VERSION ""

NS_ :

BS_:

BU_: Sound_A Ladegeraet_PAG_PF Motor_EDC17_Pirol PSM_Ant_Derivate GW_Routing_Derivate GW_Applikation_Derivate BMS_Hybrid Getriebe_Derivate LEH_Hybrid Motor_MED17_Hybrid Sound_I Tool Airbag Waehlhebel

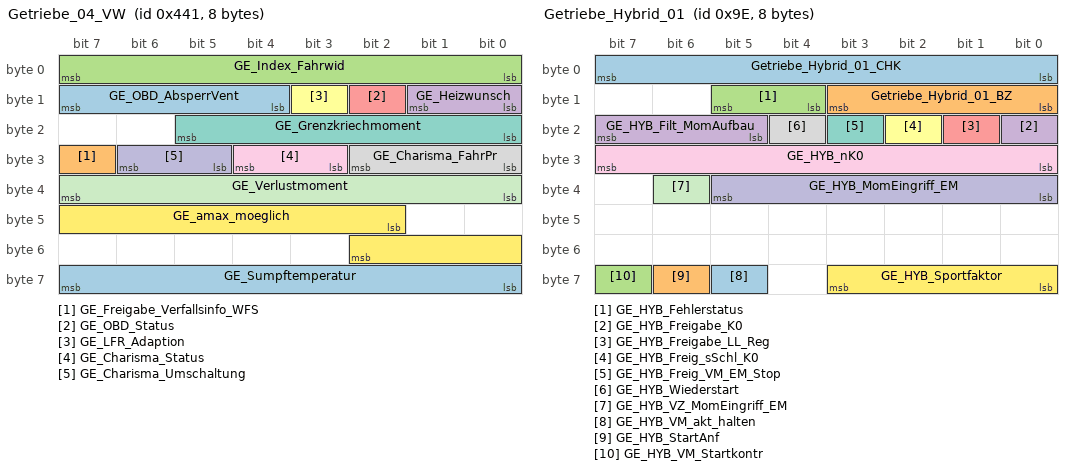
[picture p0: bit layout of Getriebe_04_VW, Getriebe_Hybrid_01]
BO_ 1089 Getriebe_04_VW: 8 Getriebe_Derivate
 SG_ GE_OBD_AbsperrVent : 12|4@1+ (1,0) [0|15] ""  GW_Routing_Derivate,Motor_EDC17_Pirol,Motor_MED17_Hybrid
 SG_ GE_Freigabe_Verfallsinfo_WFS : 31|1@1+ (1,0) [0|1] ""  GW_Routing_Derivate
 SG_ GE_Index_Fahrwid : 0|8@1+ (0.249,-31.623) [-31.623|31.623] ""  GW_Routing_Derivate,Motor_EDC17_Pirol,PSM_Ant_Derivate,Motor_MED17_Hybrid
 SG_ GE_Heizwunsch : 8|2@1+ (1,0) [0|3] ""  GW_Routing_Derivate,PSM_Ant_Derivate,Motor_MED17_Hybrid,Motor_EDC17_Pirol
 SG_ GE_OBD_Status : 10|1@1+ (1,0) [0|1] ""  GW_Routing_Derivate,Motor_EDC17_Pirol,PSM_Ant_Derivate,Motor_MED17_Hybrid
 SG_ GE_LFR_Adaption : 11|1@1+ (1,0) [0|1] ""  GW_Routing_Derivate,Motor_EDC17_Pirol,PSM_Ant_Derivate,Motor_MED17_Hybrid
 SG_ GE_Grenzkriechmoment : 16|6@1+ (2,0) [0|122] ""  GW_Routing_Derivate,PSM_Ant_Derivate
 SG_ GE_Charisma_FahrPr : 24|3@1+ (1,0) [0|7] ""  GW_Routing_Derivate
 SG_ GE_Charisma_Status : 27|2@1+ (1,0) [0|3] ""  GW_Routing_Derivate,PSM_Ant_Derivate
 SG_ GE_Charisma_Umschaltung : 29|2@1+ (1,0) [0|3] ""  GW_Routing_Derivate
 SG_ GE_Verlustmoment : 32|8@1+ (1,0) [0|254] ""  GW_Routing_Derivate,Motor_EDC17_Pirol,PSM_Ant_Derivate,Motor_MED17_Hybrid
 SG_ GE_amax_moeglich : 42|9@1+ (0.024,-2.016) [-2.016|10.224] "Unit_MeterPerSeconSquar"  GW_Routing_Derivate,Motor_EDC17_Pirol,PSM_Ant_Derivate,Motor_MED17_Hybrid
 SG_ GE_Sumpftemperatur : 56|8@1+ (1,-58) [-58|196] "Unit_DegreCelsi"  GW_Routing_Derivate,BMS_Hybrid,Motor_EDC17_Pirol,PSM_Ant_Derivate,Motor_MED17_Hybrid

BO_ 158 Getriebe_Hybrid_01: 8 Getriebe_Derivate
 SG_ Getriebe_Hybrid_01_CHK : 0|8@1+ (1,0) [0|255] "" Vector__XXX
 SG_ Getriebe_Hybrid_01_BZ : 8|4@1+ (1,0) [0|15] ""  Motor_MED17_Hybrid
 SG_ GE_HYB_Fehlerstatus : 12|2@1+ (1,0) [0|3] ""  Motor_MED17_Hybrid
 SG_ GE_HYB_Freigabe_K0 : 16|1@1+ (1,0) [0|1] ""  Motor_MED17_Hybrid
 SG_ GE_HYB_Freigabe_LL_Reg : 17|1@1+ (1,0) [0|1] ""  Motor_MED17_Hybrid
 SG_ GE_HYB_Freig_sSchl_K0 : 18|1@1+ (1,0) [0|1] ""  Motor_MED17_Hybrid
 SG_ GE_HYB_Freig_VM_EM_Stop : 19|1@1+ (1,0) [0|1] ""  Motor_MED17_Hybrid
 SG_ GE_HYB_Wiederstart : 20|1@1+ (1,0) [0|1] ""  Motor_MED17_Hybrid
 SG_ GE_HYB_nK0 : 24|8@1+ (25,0) [0|6350] "Unit_MinutInver" Vector__XXX
 SG_ GE_HYB_MomEingriff_EM : 32|6@1+ (0.5,0) [0|31.5] "Unit_NewtoMeter" Vector__XXX
 SG_ GE_HYB_VZ_MomEingriff_EM : 38|1@1+ (1,0) [0|1] "" Vector__XXX
 SG_ GE_HYB_Sportfaktor : 56|4@1+ (1,0) [0|15] ""  Motor_MED17_Hybrid
 SG_ GE_HYB_VM_akt_halten : 61|1@1+ (1,0) [0|1] ""  Motor_MED17_Hybrid
 SG_ GE_HYB_StartAnf : 62|1@1+ (1,0) [0|1] ""  Motor_MED17_Hybrid
 SG_ GE_HYB_VM_Startkontr : 63|1@1+ (1,0) [0|1] ""  Motor_MED17_Hybrid
 SG_ GE_HYB_Filt_MomAufbau : 21|3@1+ (1,0) [0|7] "" Vector__XXX

BO_ 2022 ISO_EMotor_01_Req: 8 GW_Routing_Derivate
 SG_ ISO_EMotor_01_Req_Data : 0|64@1+ (1,0) [0|1] ""  LEH_Hybrid

BO_ 2030 ISO_EMotor_01_Resp: 8 LEH_Hybrid
 SG_ ISO_EMotor_01_Resp_Data : 0|64@1+ (1,0) [0|1] ""  GW_Routing_Derivate

BO_ 2021 ISO_Hybrid_01_Req: 8 GW_Routing_Derivate
 SG_ ISO_Hybrid_01_Req_Data : 0|64@1+ (1,0) [0|1] ""  BMS_Hybrid

BO_ 2029 ISO_Hybrid_01_Resp: 8 BMS_Hybrid
 SG_ ISO_Hybrid_01_Resp_Data : 0|64@1+ (1,0) [0|1] ""  GW_Routing_Derivate

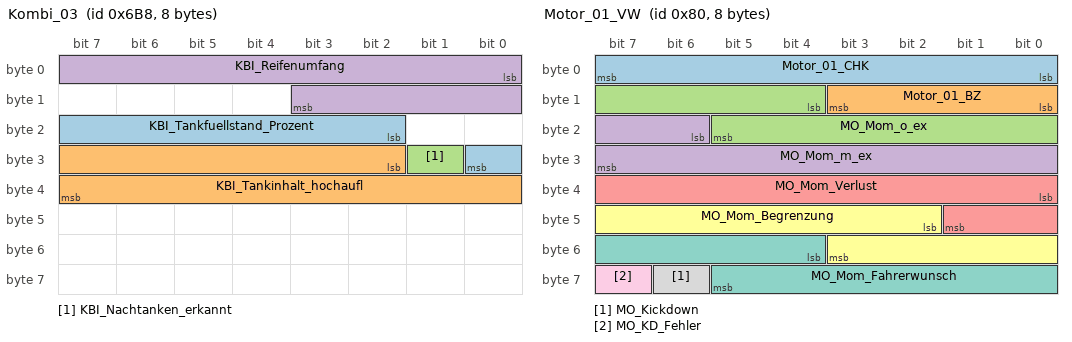
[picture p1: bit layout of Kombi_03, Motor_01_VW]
BO_ 1720 Kombi_03: 8 GW_Routing_Derivate
 SG_ KBI_Tankfuellstand_Prozent : 18|7@1+ (1,0) [0|100] "Unit_PerCent" Vector__XXX
 SG_ KBI_Tankinhalt_hochaufl : 26|14@1+ (0.01,0) [0|163.81] "Unit_Liter"  BMS_Hybrid
 SG_ KBI_Nachtanken_erkannt : 25|1@1+ (1,0) [0|1] ""  BMS_Hybrid
 SG_ KBI_Reifenumfang : 0|12@1+ (1,0) [0|4095] "Unit_MilliMeter"  Motor_MED17_Hybrid,PSM_Ant_Derivate

BO_ 128 Motor_01_VW: 8 Motor_MED17_Hybrid
 SG_ Motor_01_CHK : 0|8@1+ (1,0) [0|255] ""  PSM_Ant_Derivate,GW_Routing_Derivate,Getriebe_Derivate
 SG_ Motor_01_BZ : 8|4@1+ (1,0) [0|15] ""  PSM_Ant_Derivate,GW_Routing_Derivate,Getriebe_Derivate
 SG_ MO_Mom_o_ex : 12|10@1+ (1,0) [0|1021] ""  Sound_A,Sound_I,PSM_Ant_Derivate,GW_Routing_Derivate,Getriebe_Derivate
 SG_ MO_Mom_m_ex : 22|10@1+ (1,0) [0|1021] ""  PSM_Ant_Derivate,GW_Routing_Derivate,Getriebe_Derivate
 SG_ MO_Mom_Verlust : 32|10@1+ (1,0) [0|1021] ""  Sound_A,Sound_I,PSM_Ant_Derivate,GW_Routing_Derivate,Getriebe_Derivate
 SG_ MO_Mom_Begrenzung : 42|10@1+ (1,0) [0|1021] ""  PSM_Ant_Derivate,GW_Routing_Derivate,Getriebe_Derivate
 SG_ MO_Mom_Fahrerwunsch : 52|10@1+ (1,0) [0|1021] ""  PSM_Ant_Derivate,GW_Routing_Derivate,Getriebe_Derivate
 SG_ MO_Kickdown : 62|1@1+ (1,0) [0|1] ""  PSM_Ant_Derivate,GW_Routing_Derivate,Getriebe_Derivate
 SG_ MO_KD_Fehler : 63|1@1+ (1,0) [0|1] ""  PSM_Ant_Derivate,GW_Applikation_Derivate,GW_Routing_Derivate

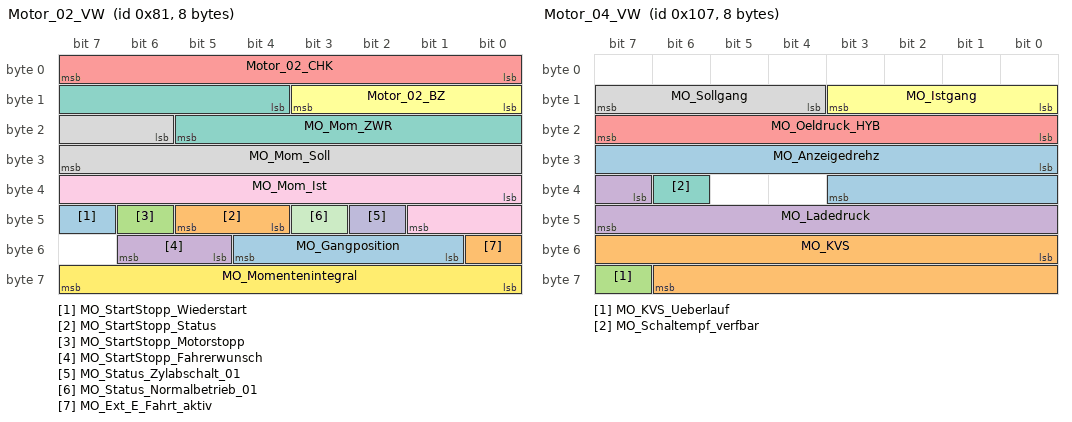
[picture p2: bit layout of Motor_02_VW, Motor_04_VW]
BO_ 129 Motor_02_VW: 8 Motor_MED17_Hybrid
 SG_ MO_StartStopp_Wiederstart : 47|1@1+ (1,0) [0|1] ""  GW_Routing_Derivate,PSM_Ant_Derivate,GW_Applikation_Derivate,Getriebe_Derivate
 SG_ MO_StartStopp_Status : 44|2@1+ (1,0) [0|3] ""  GW_Routing_Derivate,PSM_Ant_Derivate,GW_Applikation_Derivate
 SG_ MO_StartStopp_Motorstopp : 46|1@1+ (1,0) [0|1] ""  GW_Routing_Derivate,LEH_Hybrid,PSM_Ant_Derivate,GW_Applikation_Derivate,Getriebe_Derivate
 SG_ MO_StartStopp_Fahrerwunsch : 53|2@1+ (1,0) [0|3] ""  GW_Routing_Derivate
 SG_ Motor_02_CHK : 0|8@1+ (1,0) [0|255] ""  PSM_Ant_Derivate,GW_Routing_Derivate,Getriebe_Derivate
 SG_ Motor_02_BZ : 8|4@1+ (1,0) [0|15] ""  PSM_Ant_Derivate,GW_Routing_Derivate,Getriebe_Derivate
 SG_ MO_Mom_ZWR : 12|10@1+ (1,0) [0|1021] ""  PSM_Ant_Derivate,Getriebe_Derivate
 SG_ MO_Mom_Soll : 22|10@1+ (1,0) [0|1021] ""  PSM_Ant_Derivate
 SG_ MO_Mom_Ist : 32|10@1+ (1,0) [0|1021] ""  PSM_Ant_Derivate,Getriebe_Derivate
 SG_ MO_Status_Zylabschalt_01 : 42|1@1+ (1,0) [0|1] ""  PSM_Ant_Derivate
 SG_ MO_Status_Normalbetrieb_01 : 43|1@1+ (1,0) [0|1] ""  PSM_Ant_Derivate,Getriebe_Derivate
 SG_ MO_Momentenintegral : 56|8@1+ (0.3921,0) [0|99.9855] ""  PSM_Ant_Derivate,Getriebe_Derivate
 SG_ MO_Gangposition : 49|4@1+ (1,0) [0|15] "" Vector__XXX
 SG_ MO_Ext_E_Fahrt_aktiv : 48|1@1+ (1,0) [0|1] ""  Getriebe_Derivate,GW_Routing_Derivate

BO_ 261 Motor_03_VW: 8 Motor_MED17_Hybrid
 SG_ MO_QBit_Motormomente : 13|1@1+ (1,0) [0|1] ""  Getriebe_Derivate,GW_Routing_Derivate,PSM_Ant_Derivate
 SG_ Motor_03_CHK : 0|8@1+ (1,0) [0|255] ""  BMS_Hybrid,PSM_Ant_Derivate,LEH_Hybrid,GW_Routing_Derivate,Getriebe_Derivate
 SG_ Motor_03_BZ : 8|4@1+ (1,0) [0|15] ""  BMS_Hybrid,PSM_Ant_Derivate,LEH_Hybrid,GW_Routing_Derivate,Getriebe_Derivate
 SG_ MO_QBit_Fahrpedalwerte_01 : 12|1@1+ (1,0) [0|1] ""  BMS_Hybrid,PSM_Ant_Derivate,GW_Routing_Derivate,Getriebe_Derivate
 SG_ MO_QBit_Fahrer_bremst : 14|1@1+ (1,0) [0|1] ""  PSM_Ant_Derivate,GW_Routing_Derivate,Getriebe_Derivate
 SG_ MO_QBit_Drehzahl_01 : 15|1@1+ (1,0) [0|1] ""  PSM_Ant_Derivate,BMS_Hybrid,GW_Routing_Derivate,Getriebe_Derivate,LEH_Hybrid
 SG_ MO_Drehzahl_01 : 16|16@1+ (0.25,0) [0|16383] "Unit_MinutInver"  Sound_A,Sound_I,PSM_Ant_Derivate,BMS_Hybrid,GW_Applikation_Derivate,GW_Routing_Derivate,Getriebe_Derivate,LEH_Hybrid
 SG_ MO_Moment_im_Leerlauf : 32|1@1+ (1,0) [0|1] ""  PSM_Ant_Derivate,GW_Routing_Derivate,Getriebe_Derivate
 SG_ MO_Interlock : 33|1@1+ (1,0) [0|1] ""  PSM_Ant_Derivate,GW_Routing_Derivate
 SG_ MO_BLS : 34|1@1+ (1,0) [0|1] ""  PSM_Ant_Derivate,GW_Routing_Derivate,Getriebe_Derivate
 SG_ MO_Fahrer_bremst : 35|1@1+ (1,0) [0|1] ""  PSM_Ant_Derivate,GW_Routing_Derivate,Getriebe_Derivate
 SG_ MO_Konsistenz_Bremsped : 36|1@1+ (1,0) [0|1] ""  PSM_Ant_Derivate,GW_Routing_Derivate
 SG_ MO_Kuppl_schalter : 37|1@1+ (1,0) [0|1] ""  PSM_Ant_Derivate,GW_Routing_Derivate
 SG_ MO_Timeout_ESP : 38|1@1+ (1,0) [0|1] ""  PSM_Ant_Derivate,GW_Routing_Derivate
 SG_ MO_Motor_laeuft : 39|1@1+ (1,0) [0|1] ""  PSM_Ant_Derivate,GW_Applikation_Derivate,GW_Routing_Derivate,Getriebe_Derivate
 SG_ MO_Solldrehz_Leerlauf : 40|8@1+ (10,0) [0|2540] "Unit_MinutInver"  PSM_Ant_Derivate,GW_Routing_Derivate,Getriebe_Derivate,GW_Applikation_Derivate
 SG_ MO_Fahrpedalrohwert_01 : 48|8@1+ (0.4,0) [0|101.6] "Unit_PerCent"  Sound_A,Sound_I,BMS_Hybrid,PSM_Ant_Derivate,GW_Routing_Derivate,Getriebe_Derivate
 SG_ MO_erste_Ungenauschwelle : 56|1@1+ (1,0) [0|1] ""  PSM_Ant_Derivate,GW_Routing_Derivate,Getriebe_Derivate
 SG_ MO_QBit_Stressfaktor : 57|1@1+ (1,0) [0|1] ""  PSM_Ant_Derivate,GW_Routing_Derivate
 SG_ MO_Stressfaktor : 58|6@1+ (1.6,0) [0|100.8] "Unit_PerCent"  PSM_Ant_Derivate,GW_Routing_Derivate

BO_ 263 Motor_04_VW: 8 Motor_MED17_Hybrid
 SG_ MO_Anzeigedrehz : 24|12@1+ (3,0) [0|12282] "U/min"  PSM_Ant_Derivate,GW_Routing_Derivate
 SG_ MO_KVS : 48|15@1+ (1,0) [0|32767] "Unit_MicroLiter"  BMS_Hybrid,PSM_Ant_Derivate,GW_Routing_Derivate
 SG_ MO_KVS_Ueberlauf : 63|1@1+ (1,0) [0|1] ""  BMS_Hybrid,PSM_Ant_Derivate,GW_Routing_Derivate
 SG_ MO_Ladedruck : 39|9@1+ (0.01,0) [0|5.1] "Unit_Bar"  GW_Routing_Derivate,PSM_Ant_Derivate
 SG_ MO_Oeldruck_HYB : 16|8@1+ (0.04,0) [0|10] "Uni_Bar"  GW_Routing_Derivate
 SG_ MO_Istgang : 8|4@1+ (1,0) [0|15] "" Vector__XXX
 SG_ MO_Schaltempf_verfbar : 38|1@1+ (1,0) [0|1] "" Vector__XXX
 SG_ MO_Sollgang : 12|4@1+ (1,0) [0|15] "" Vector__XXX

BO_ 782 Motor_05_VW: 8 Motor_MED17_Hybrid
 SG_ MO_Handshake_STH : 47|1@1+ (1,0) [0|1] ""  GW_Routing_Derivate
 SG_ Motor_05_CHK : 0|8@1+ (1,0) [0|255] ""  GW_Routing_Derivate,Getriebe_Derivate
 SG_ Motor_05_BZ : 8|4@1+ (1,0) [0|15] ""  GW_Routing_Derivate,Getriebe_Derivate
 SG_ MO_EKlKomLeiRed : 12|2@1+ (1,0) [0|3] ""  GW_Routing_Derivate
 SG_ MO_Freig_Reku : 14|2@1+ (1,0) [0|3] ""  BMS_Hybrid,GW_Routing_Derivate,GW_Applikation_Derivate
 SG_ MO_Klima_Eingr : 16|2@1+ (1,0) [0|3] ""  GW_Routing_Derivate
 SG_ MO_Status_Normalbetrieb_02 : 18|1@1+ (1,0) [0|1] ""  GW_Routing_Derivate
 SG_ MO_Schaltbeeinfl_Leistungsbegr : 19|1@1+ (1,0) [0|1] ""  GW_Routing_Derivate
 SG_ MO_Schaltbeeinfl_Partikelfilter : 20|1@1+ (1,0) [0|1] ""  GW_Routing_Derivate,Getriebe_Derivate
 SG_ MO_Prio_MIN_Wunschdrehzahl : 21|1@1+ (1,0) [0|1] ""  GW_Routing_Derivate,Getriebe_Derivate
 SG_ MO_Freig_Anlass : 22|1@1+ (1,0) [0|1] ""  GW_Routing_Derivate
 SG_ MO_Aussp_Anlass : 23|1@1+ (1,0) [0|1] ""  GW_Routing_Derivate
 SG_ MO_MAX_Wunschdrehzahl : 24|9@1+ (25,0) [0|12750] "Unit_MinutInver"  GW_Routing_Derivate,Getriebe_Derivate
 SG_ MO_Prio_MAX_Wunschdrehzahl : 33|1@1+ (1,0) [0|1] ""  GW_Routing_Derivate,Getriebe_Derivate
 SG_ MO_Luftpfad_aktiv : 34|1@1+ (1,0) [0|1] ""  GW_Routing_Derivate
 SG_ MO_v_Begrenz_Aktiv : 35|1@1+ (1,0) [0|1] ""  GW_Routing_Derivate
 SG_ MO_v_Begrenz_Aktivierbar : 36|1@1+ (1,0) [0|1] ""  GW_Routing_Derivate
 SG_ MO_Verbot_EKP : 37|1@1+ (1,0) [0|1] ""  GW_Routing_Derivate
 SG_ MO_Anf_Pruefimpuls : 38|1@1+ (1,0) [0|1] ""  GW_Routing_Derivate
 SG_ MO_Anf_KL75 : 39|1@1+ (1,0) [0|1] ""  GW_Routing_Derivate
 SG_ MO_Charisma_FahrPr : 40|3@1+ (1,0) [0|7] ""  GW_Routing_Derivate
 SG_ MO_Charisma_Status : 43|2@1+ (1,0) [0|3] ""  PSM_Ant_Derivate,GW_Routing_Derivate
 SG_ MO_Charisma_Umschaltung : 45|2@1+ (1,0) [0|3] ""  GW_Routing_Derivate
 SG_ MO_MIN_Wunschdrehzahl : 48|8@1+ (25,0) [0|6350] "Unit_MinutInver"  GW_Routing_Derivate,Getriebe_Derivate
 SG_ MO_Drehzahlbeeinflussung : 56|8@1+ (0.39,0) [0|99.45] "Unit_PerCent"  GW_Routing_Derivate

BO_ 1088 Motor_06_VW: 8 Motor_MED17_Hybrid
 SG_ MO_Kat_Warnung : 22|1@1+ (1,0) [0|1] ""  GW_Routing_Derivate
 SG_ MO_ITM_Warnung_Pumpe : 11|1@1+ (1,0) [0|1] ""  GW_Routing_Derivate
 SG_ MO_HYB_Text_4 : 31|1@1+ (1,0) [0|1] ""  GW_Routing_Derivate
 SG_ MO_HYB_Status_HV_Ladung : 8|3@1+ (1,0) [0|7] ""  GW_Routing_Derivate
 SG_ MO_Zustand_HWP : 20|2@1+ (1,0) [0|3] ""  GW_Routing_Derivate
 SG_ MO_Kuehlerluefter_MUX M : 0|1@1+ (1,0) [0|1] ""  GW_Routing_Derivate
 SG_ MO_Kuehlerluefter_1 m0 : 1|7@1+ (1,0) [0|100] "Unit_PerCent"  GW_Routing_Derivate
 SG_ MO_Kuehlerluefter_2 m1 : 1|7@1+ (1,0) [0|100] "Unit_PerCent"  GW_Routing_Derivate
 SG_ WIV_Anzeige_aktiv : 12|1@1+ (1,0) [0|1] ""  GW_Routing_Derivate
 SG_ WIV_Oelmin_Warn : 13|1@1+ (1,0) [0|1] ""  GW_Routing_Derivate
 SG_ WIV_Sensorfehler : 14|1@1+ (1,0) [0|1] ""  GW_Routing_Derivate
 SG_ WIV_Schieflage : 15|1@1+ (1,0) [0|1] ""  GW_Routing_Derivate
 SG_ WIV_Oelstand : 16|4@1+ (12.5,0) [0|100] "Unit_PerCent"  GW_Routing_Derivate
 SG_ WIV_Oelsystem_aktiv : 24|1@1+ (1,0) [0|1] ""  GW_Routing_Derivate
 SG_ WIV_nicht_betriebswarm : 25|1@1+ (1,0) [0|1] ""  GW_Routing_Derivate
 SG_ WIV_Ueberfuell_Warn : 26|1@1+ (1,0) [0|1] ""  GW_Routing_Derivate
 SG_ WIV_laufender_Motor : 27|1@1+ (1,0) [0|1] ""  GW_Routing_Derivate
 SG_ MO_Text_Motorstart : 32|4@1+ (1,0) [0|15] ""  GW_Routing_Derivate
 SG_ MO_Text_MSG_Werkstatt : 40|1@1+ (1,0) [0|1] ""  GW_Routing_Derivate
 SG_ MO_Text_Partikelfil_Reg : 41|1@1+ (1,0) [0|1] ""  GW_Routing_Derivate
 SG_ MO_Text_Fehler_Kraftstoffsys : 42|1@1+ (1,0) [0|1] ""  GW_Routing_Derivate
 SG_ WIV_Oelmenge : 43|5@1+ (125,0) [0|3875] "Unit_MilliLiter"  GW_Routing_Derivate
 SG_ MO_Systemlampe : 48|1@1+ (1,0) [0|1] ""  GW_Routing_Derivate
 SG_ MO_OBD2_Lampe : 49|1@1+ (1,0) [0|1] ""  GW_Routing_Derivate
 SG_ MO_Heissleuchte : 50|1@1+ (1,0) [0|1] ""  GW_Routing_Derivate
 SG_ MO_Partikel_Lampe : 51|1@1+ (1,0) [0|1] ""  GW_Routing_Derivate
 SG_ MO_Winterfahrprog : 52|1@1+ (1,0) [0|1] ""  GW_Routing_Derivate
 SG_ WIV_Oelstand_nicht_vorhanden : 53|1@1+ (1,0) [0|1] ""  GW_Routing_Derivate
 SG_ WIV_nachfuellanzeige_ein : 54|1@1+ (1,0) [0|1] ""  GW_Routing_Derivate
 SG_ WIV_Ueberfuell_deaktiv : 55|1@1+ (1,0) [0|1] ""  GW_Routing_Derivate
 SG_ WIV_Unterfuell_Warn : 56|1@1+ (1,0) [0|1] ""  GW_Routing_Derivate
 SG_ MO_Tankdeckel_Lampe : 57|1@1+ (1,0) [0|1] ""  GW_Routing_Derivate
 SG_ MO_Text_Tankdeckelwarn : 58|1@1+ (1,0) [0|1] ""  GW_Routing_Derivate
 SG_ WIV_Enable_Oeldr_Motor : 59|1@1+ (1,0) [0|1] ""  GW_Routing_Derivate
 SG_ WIV_Oeldr_Warn_Motor : 60|1@1+ (1,0) [0|1] ""  GW_Routing_Derivate
 SG_ MO_Avus_Motorschutz : 61|2@1+ (1,0) [0|3] ""  GW_Routing_Derivate
 SG_ MO_HYB_Fahrbereitschaft : 63|1@1+ (1,0) [0|1] ""  Sound_A,Sound_I,BMS_Hybrid,GW_Applikation_Derivate,GW_Routing_Derivate
 SG_ WIV_Oeldyn_avl : 39|1@1+ (1,0) [0|1] ""  GW_Routing_Derivate
 SG_ MO_HYB_Text_7 : 38|1@1+ (1,0) [0|1] ""  GW_Routing_Derivate
 SG_ MO_HYB_Text_6 : 37|1@1+ (1,0) [0|1] ""  GW_Routing_Derivate
 SG_ MO_HYB_Text_5 : 36|1@1+ (1,0) [0|1] ""  GW_Routing_Derivate
 SG_ MO_HYB_Text_3 : 30|1@1+ (1,0) [0|1] ""  GW_Routing_Derivate
 SG_ MO_HYB_Text_2 : 29|1@1+ (1,0) [0|1] ""  GW_Routing_Derivate
 SG_ MO_HYB_Text_1 : 28|1@1+ (1,0) [0|1] ""  GW_Routing_Derivate

BO_ 1600 Motor_07_VW: 8 Motor_MED17_Hybrid
 SG_ MO_Nachlaufzeit_Heizungspumpe : 58|6@1+ (15,0) [0|945] "Unit_Secon"  GW_Routing_Derivate
 SG_ MO_Kennfeldk : 40|1@1+ (1,0) [0|1] ""  GW_Routing_Derivate
 SG_ MO_QBit_Ansaugluft_Temp : 0|1@1+ (1,0) [0|1] ""  GW_Routing_Derivate
 SG_ MO_QBit_Oel_Temp : 1|1@1+ (1,0) [0|1] ""  GW_Routing_Derivate
 SG_ MO_QBit_Kuehlmittel_Temp : 2|1@1+ (1,0) [0|1] ""  GW_Routing_Derivate,Getriebe_Derivate,LEH_Hybrid
 SG_ MO_Stellgliedtest_Soundaktuator : 3|1@1+ (1,0) [0|1] ""  GW_Routing_Derivate
 SG_ MO_HYB_Fehler_HV_Netz : 4|1@1+ (1,0) [0|1] ""  GW_Applikation_Derivate,GW_Routing_Derivate
 SG_ MO_Absperrventil_oeffnen : 6|2@1+ (1,0) [0|3] ""  GW_Routing_Derivate
 SG_ MO_Ansaugluft_Temp : 8|8@1+ (0.75,-48) [-48|141.75] "Unit_DegreCelsi"  GW_Routing_Derivate,Getriebe_Derivate
 SG_ MO_Oel_Temp : 16|8@1+ (1,-60) [-60|193] "Unit_DegreCelsi"  GW_Routing_Derivate
 SG_ MO_Kuehlmittel_Temp : 24|8@1+ (0.75,-48) [-48|141.75] "Unit_DegreCelsi"  BMS_Hybrid,GW_Applikation_Derivate,GW_Routing_Derivate,Getriebe_Derivate,LEH_Hybrid
 SG_ MO_Hoeheninfo : 32|8@1+ (0.00781,0) [0|1.98374] ""  GW_Routing_Derivate,Getriebe_Derivate
 SG_ MO_Versionsinfo : 41|6@1+ (1,0) [0|63] ""  Getriebe_Derivate,GW_Routing_Derivate
 SG_ MO_Getriebe_kuehlen : 47|1@1+ (1,0) [0|1] ""  Getriebe_Derivate,GW_Routing_Derivate
 SG_ MO_Mom_Traegheit_02 : 48|5@1+ (0.01,0) [0|0.31] "Unit_KiloGramMeterSquar"  GW_Routing_Derivate
 SG_ MO_Heizungspumpenansteuerung : 53|4@1+ (10,0) [0|100] "Unit_PerCent"  GW_Routing_Derivate
 SG_ MO_SpannungsAnf : 57|1@1+ (1,0) [0|1] ""  GW_Applikation_Derivate,GW_Routing_Derivate
 SG_ MO_aktives_Getriebeheizen : 5|1@1+ (1,0) [0|1] ""  Getriebe_Derivate,GW_Routing_Derivate

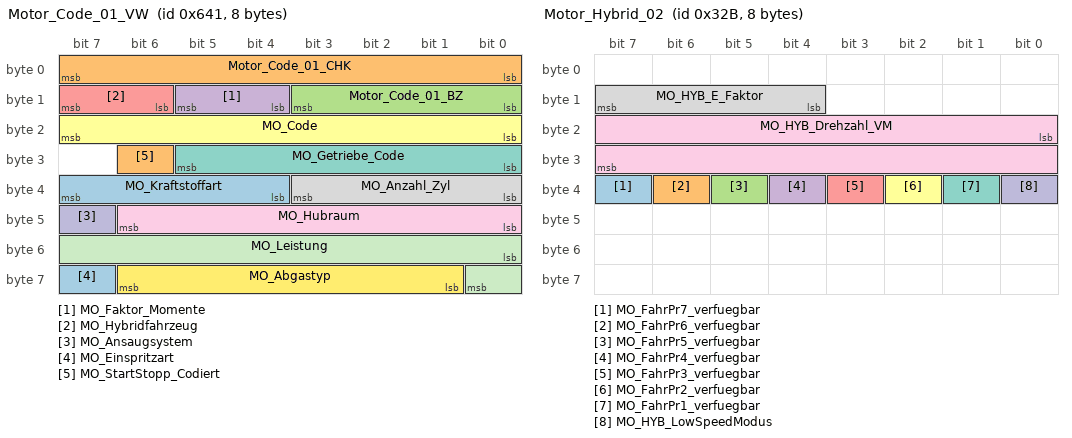
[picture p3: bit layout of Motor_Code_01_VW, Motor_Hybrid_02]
BO_ 1601 Motor_Code_01_VW: 8 Motor_MED17_Hybrid
 SG_ MO_Kraftstoffart : 36|4@1+ (1,0) [0|15] ""  PSM_Ant_Derivate,GW_Routing_Derivate,Getriebe_Derivate
 SG_ Motor_Code_01_CHK : 0|8@1+ (1,0) [0|255] ""  PSM_Ant_Derivate,LEH_Hybrid,GW_Routing_Derivate,Getriebe_Derivate
 SG_ Motor_Code_01_BZ : 8|4@1+ (1,0) [0|15] ""  PSM_Ant_Derivate,LEH_Hybrid,GW_Routing_Derivate,Getriebe_Derivate
 SG_ MO_Faktor_Momente : 12|2@1+ (1,0) [0|3] ""  PSM_Ant_Derivate,GW_Routing_Derivate,Getriebe_Derivate
 SG_ MO_Hybridfahrzeug : 14|2@1+ (1,0) [0|3] ""  PSM_Ant_Derivate,GW_Routing_Derivate
 SG_ MO_Code : 16|8@1+ (1,0) [0|255] ""  PSM_Ant_Derivate,GW_Routing_Derivate,Getriebe_Derivate
 SG_ MO_Getriebe_Code : 24|6@1+ (1,0) [0|63] ""  PSM_Ant_Derivate,GW_Routing_Derivate,Getriebe_Derivate
 SG_ MO_Anzahl_Zyl : 32|4@1+ (1,0) [0|15] ""  GW_Routing_Derivate
 SG_ MO_Hubraum : 40|7@1+ (0.1,0) [0|12.7] "Unit_Liter"  GW_Routing_Derivate
 SG_ MO_Ansaugsystem : 47|1@1+ (1,0) [0|1] ""  GW_Routing_Derivate
 SG_ MO_Leistung : 48|9@1+ (1,0) [0|511] "Unit_KiloWatt"  GW_Routing_Derivate,Getriebe_Derivate
 SG_ MO_Abgastyp : 57|6@1+ (1,0) [0|63] ""  LEH_Hybrid,BMS_Hybrid,GW_Routing_Derivate,Getriebe_Derivate
 SG_ MO_Einspritzart : 63|1@1+ (1,0) [0|1] ""  GW_Routing_Derivate
 SG_ MO_StartStopp_Codiert : 30|1@1+ (1,0) [0|1] ""  GW_Routing_Derivate,Getriebe_Derivate

BO_ 157 Motor_Hybrid_01: 8 Motor_MED17_Hybrid
 SG_ MO_HYB_EMode_Info : 14|2@1+ (1,0) [0|3] ""  Getriebe_Derivate
 SG_ Motor_Hybrid_01_CHK : 0|8@1+ (1,0) [0|255] ""  Getriebe_Derivate
 SG_ Motor_Hybrid_01_BZ : 8|4@1+ (1,0) [0|15] ""  BMS_Hybrid,Getriebe_Derivate
 SG_ MO_HYB_IstStatusK0 : 12|2@1+ (1,0) [0|3] ""  Getriebe_Derivate
 SG_ MO_HYB_max_ind_VM_Mom : 16|10@1+ (1,0) [0|1021] "Unit_NewtoMeter"  Getriebe_Derivate
 SG_ MO_HYB_Zielzustand : 26|3@1+ (1,0) [0|7] ""  BMS_Hybrid,Getriebe_Derivate
 SG_ MO_HYB_Startmodus : 29|3@1+ (1,0) [0|7] ""  Getriebe_Derivate
 SG_ MO_HYB_Startmodus_PQ3x : 32|1@1+ (1,0) [0|1] "" Vector__XXX
 SG_ MO_HYB_Stoppmodus : 33|1@1+ (1,0) [0|1] "" Vector__XXX
 SG_ MO_HYB_VM_Mom_oE : 40|10@1+ (1,-100) [-100|922] "Unit_NewtoMeter"  Getriebe_Derivate
 SG_ MO_HYB_VM_aktiv : 50|1@1+ (1,0) [0|1] ""  BMS_Hybrid,Getriebe_Derivate,GW_Routing_Derivate
 SG_ MO_HYB_Schaltverhinderung : 51|1@1+ (1,0) [0|1] ""  Getriebe_Derivate
 SG_ MO_HYB_Selektor_Momverlauf_EM M : 53|3@1+ (1,0) [0|7] ""  Getriebe_Derivate
 SG_ MO_HYB_Momverlauf_Rek m1 : 56|8@1+ (2,0) [0|510] "Unit_NewtoMeter"  Getriebe_Derivate
 SG_ MO_HYB_KnickDZ_Rek m2 : 56|8@1+ (12.5,0) [0|3150] "Unit_MinutInver"  Getriebe_Derivate
 SG_ MO_HYB_Momverlauf_EM m3 : 56|8@1+ (2,0) [0|510] "Unit_NewtoMeter"  Getriebe_Derivate
 SG_ MO_HYB_KnickDZ_EM m4 : 56|8@1+ (12.5,0) [0|3150] "Unit_MinutInver"  Getriebe_Derivate

BO_ 811 Motor_Hybrid_02: 8 Motor_MED17_Hybrid
 SG_ MO_FahrPr7_verfuegbar : 39|1@1+ (1,0) [0|1] ""  GW_Routing_Derivate
 SG_ MO_FahrPr6_verfuegbar : 38|1@1+ (1,0) [0|1] ""  GW_Routing_Derivate
 SG_ MO_FahrPr5_verfuegbar : 37|1@1+ (1,0) [0|1] ""  GW_Routing_Derivate
 SG_ MO_FahrPr4_verfuegbar : 36|1@1+ (1,0) [0|1] ""  GW_Routing_Derivate
 SG_ MO_FahrPr3_verfuegbar : 35|1@1+ (1,0) [0|1] ""  GW_Routing_Derivate
 SG_ MO_FahrPr2_verfuegbar : 34|1@1+ (1,0) [0|1] ""  GW_Routing_Derivate
 SG_ MO_FahrPr1_verfuegbar : 33|1@1+ (1,0) [0|1] ""  GW_Routing_Derivate
 SG_ MO_HYB_E_Faktor : 12|4@1+ (1,0) [0|15] ""  Getriebe_Derivate,GW_Routing_Derivate
 SG_ MO_HYB_Drehzahl_VM : 16|16@1+ (0.25,0) [0|16256] "Unit_MinutInver"  Getriebe_Derivate,GW_Routing_Derivate,BMS_Hybrid
 SG_ MO_HYB_LowSpeedModus : 32|1@1+ (1,0) [0|1] ""  Getriebe_Derivate,GW_Routing_Derivate

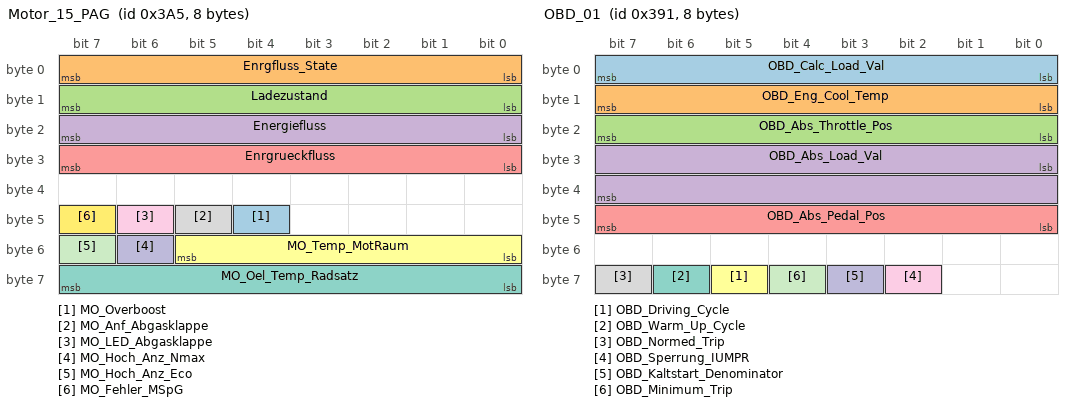
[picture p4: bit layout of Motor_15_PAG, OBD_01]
BO_ 933 Motor_15_PAG: 8 Motor_MED17_Hybrid
 SG_ MO_Overboost : 44|1@1+ (1,0) [0|1] ""  GW_Routing_Derivate
 SG_ Enrgfluss_State : 0|8@1+ (1,0) [0|255] ""  GW_Routing_Derivate
 SG_ Ladezustand : 8|8@1+ (1,0) [0|100] "Unit_PerCent"  GW_Routing_Derivate
 SG_ Energiefluss : 16|8@1+ (1,-128) [-100|100] "Unit_PerCent"  GW_Routing_Derivate
 SG_ Enrgrueckfluss : 24|8@1+ (0.2,0) [0|50.8] ""  GW_Routing_Derivate
 SG_ MO_Temp_MotRaum : 48|6@1+ (3,-48) [-48|141] "Unit_DegreCelsi"  GW_Routing_Derivate
 SG_ MO_Oel_Temp_Radsatz : 56|8@1+ (1,-60) [-60|193] "Unit_DegreCelsi"  GW_Routing_Derivate
 SG_ MO_Anf_Abgasklappe : 45|1@1+ (1,0) [0|1] ""  GW_Routing_Derivate
 SG_ MO_LED_Abgasklappe : 46|1@1+ (1,0) [0|1] ""  GW_Routing_Derivate
 SG_ MO_Hoch_Anz_Nmax : 54|1@1+ (1,0) [0|1] ""  GW_Routing_Derivate
 SG_ MO_Hoch_Anz_Eco : 55|1@1+ (1,0) [0|1] ""  GW_Routing_Derivate
 SG_ MO_Fehler_MSpG : 47|1@1+ (1,0) [0|1] ""  GW_Routing_Derivate

BO_ 1730 NMH_Getriebe: 7 Getriebe_Derivate
 SG_ NMH_GE_N_Haltephase : 19|1@1+ (1,0) [0|1] "" Vector__XXX
 SG_ NMH_GE_Start_1 : 0|1@1+ (1,0) [0|1] ""  Motor_EDC17_Pirol,BMS_Hybrid,LEH_Hybrid,Ladegeraet_PAG_PF,GW_Applikation_Derivate,Motor_MED17_Hybrid
 SG_ NMH_GE_Start_2 : 1|1@1+ (1,0) [0|1] ""  GW_Applikation_Derivate
 SG_ NMH_GE_Normal_Mode_1 : 2|1@1+ (1,0) [0|1] ""  GW_Applikation_Derivate
 SG_ NMH_GE_Normal_Mode_2 : 3|1@1+ (1,0) [0|1] ""  GW_Applikation_Derivate
 SG_ NMH_GE_Car_WakeUp : 6|1@1+ (1,0) [0|1] "" Vector__XXX
 SG_ NMH_GE_Per_WakeUp : 8|5@1+ (1,0) [0|31] "" Vector__XXX
 SG_ NMH_GE_Fkt_WakeUp : 13|3@1+ (1,0) [0|7] "" Vector__XXX
 SG_ NMH_GE_NM_aktiv_Klemme_15 : 16|1@1+ (1,0) [0|1] "" Vector__XXX
 SG_ NMH_GE_NM_aktiv_Diagnose : 17|1@1+ (1,0) [0|1] "" Vector__XXX
 SG_ NMH_GE_NM_aktiv_Start : 18|1@1+ (1,0) [0|1] "" Vector__XXX
 SG_ NMH_GE_kein_NL : 24|1@1+ (1,0) [0|1] "" Vector__XXX
 SG_ NMH_GE_NL_Daten_EEPROM : 25|1@1+ (1,0) [0|1] "" Vector__XXX
 SG_ NMH_GE_NL_Drucksens : 26|1@1+ (1,0) [0|1] "" Vector__XXX
 SG_ NMH_GE_NL_Abtrieb : 27|1@1+ (1,0) [0|1] "" Vector__XXX
 SG_ NMH_GE_NL_Waehlhebel : 28|1@1+ (1,0) [0|1] "" Vector__XXX
 SG_ NMH_GE_NL_Wegfahrsperre : 29|1@1+ (1,0) [0|1] "" Vector__XXX
 SG_ NM_GE_Signalfehler : 32|1@1+ (1,0) [0|1] "" Vector__XXX
 SG_ NMH_GE_TimeOut_Fehler : 33|1@1+ (1,0) [0|1] "" Vector__XXX
 SG_ NMH_GE_CAN_Diag_deaktiv : 34|1@1+ (1,0) [0|1] "" Vector__XXX
 SG_ NMH_GE_KompSchutz : 35|1@1+ (1,0) [0|1] "" Vector__XXX
 SG_ NMH_GE_Mute_Mode : 36|1@1+ (1,0) [0|1] "" Vector__XXX
 SG_ NMH_GE_Transport_Mode : 37|1@1+ (1,0) [0|1] "" Vector__XXX
 SG_ NMH_GE_Abschaltstufe_aktiv : 38|1@1+ (1,0) [0|1] "" Vector__XXX
 SG_ NMH_GE_Eindraht_Fehler : 39|1@1+ (1,0) [0|1] "" Vector__XXX
 SG_ NMH_GE_Lokalaktiv : 48|1@1+ (1,0) [0|1] "" Vector__XXX
 SG_ NMH_GE_Subsystemaktiv : 49|1@1+ (1,0) [0|1] "" Vector__XXX
 SG_ NMH_GSG_Subbusaktiv : 50|1@1+ (1,0) [0|1] "" Vector__XXX

BO_ 1729 NMH_Motor: 7 Motor_MED17_Hybrid
 SG_ NMH_MO_Start_1 : 0|1@1+ (1,0) [0|1] ""  BMS_Hybrid,LEH_Hybrid,Ladegeraet_PAG_PF,GW_Applikation_Derivate,Getriebe_Derivate
 SG_ NMH_MO_Start_2 : 1|1@1+ (1,0) [0|1] ""  GW_Applikation_Derivate
 SG_ NMH_MO_Normal_Mode_1 : 2|1@1+ (1,0) [0|1] ""  GW_Applikation_Derivate
 SG_ NMH_MO_NM_aktiv_HV_Abschaltung : 21|1@1+ (1,0) [0|1] "" Vector__XXX
 SG_ NMH_MO_Normal_Mode_2 : 3|1@1+ (1,0) [0|1] ""  GW_Applikation_Derivate
 SG_ NMH_MO_Car_WakeUp : 6|1@1+ (1,0) [0|1] "" Vector__XXX
 SG_ NMH_MO_Per_WakeUp : 8|5@1+ (1,0) [0|31] "" Vector__XXX
 SG_ NMH_MO_Fkt_WakeUp : 13|3@1+ (1,0) [0|7] "" Vector__XXX
 SG_ NMH_MO_NM_aktiv_Klemme_15 : 16|1@1+ (1,0) [0|1] "" Vector__XXX
 SG_ NMH_MO_NM_aktiv_Diagnose : 17|1@1+ (1,0) [0|1] "" Vector__XXX
 SG_ NMH_MO_NM_aktiv_Start : 18|1@1+ (1,0) [0|1] "" Vector__XXX
 SG_ NMH_MO_NM_aktiv_EKP_Vorlauf : 19|1@1+ (1,0) [0|1] "" Vector__XXX
 SG_ NMH_MO_NM_aktiv_STH_Betrieb : 20|1@1+ (1,0) [0|1] "" Vector__XXX
 SG_ NMH_MO_kein_NL : 24|1@1+ (1,0) [0|1] "" Vector__XXX
 SG_ NMH_MO_NL_Kuehlerluefter : 25|1@1+ (1,0) [0|1] "" Vector__XXX
 SG_ NMH_MO_NL_Diagnose : 26|1@1+ (1,0) [0|1] "" Vector__XXX
 SG_ NMH_MO_NL_WFS : 27|1@1+ (1,0) [0|1] "" Vector__XXX
 SG_ NMH_MO_NL_EEPROM : 28|1@1+ (1,0) [0|1] "" Vector__XXX
 SG_ NMH_MO_NL_Sonstige : 29|1@1+ (1,0) [0|1] "" Vector__XXX
 SG_ NM_MO_Signalfehler : 32|1@1+ (1,0) [0|1] "" Vector__XXX
 SG_ NMH_MO_TimeOut_Fehler : 33|1@1+ (1,0) [0|1] "" Vector__XXX
 SG_ NMH_MO_CAN_Diag_deaktiv : 34|1@1+ (1,0) [0|1] "" Vector__XXX
 SG_ NMH_MO_KompSchutz : 35|1@1+ (1,0) [0|1] "" Vector__XXX
 SG_ NMH_MO_Mute_Mode : 36|1@1+ (1,0) [0|1] "" Vector__XXX
 SG_ NMH_MO_Transport_Mode : 37|1@1+ (1,0) [0|1] "" Vector__XXX
 SG_ NMH_MO_Abschaltstufe_aktiv : 38|1@1+ (1,0) [0|1] "" Vector__XXX
 SG_ NMH_MO_Eindraht_Fehler : 39|1@1+ (1,0) [0|1] "" Vector__XXX
 SG_ NMH_MO_Lokalaktiv : 48|1@1+ (1,0) [0|1] "" Vector__XXX
 SG_ NMH_MO_Subsystemaktiv : 49|1@1+ (1,0) [0|1] "" Vector__XXX

BO_ 913 OBD_01: 8 Motor_MED17_Hybrid
 SG_ OBD_Calc_Load_Val : 0|8@1+ (0.39215686275,0) [0|100] "Unit_PerCent"  BMS_Hybrid,Getriebe_Derivate,LEH_Hybrid
 SG_ OBD_Eng_Cool_Temp : 8|8@1+ (1,-40) [-40|215] "Unit_DegreCelsi"  BMS_Hybrid,Getriebe_Derivate,LEH_Hybrid
 SG_ OBD_Abs_Throttle_Pos : 16|8@1+ (0.39215686275,0) [0|100] "Unit_PerCent"  BMS_Hybrid,Getriebe_Derivate,LEH_Hybrid
 SG_ OBD_Abs_Load_Val : 24|16@1+ (0.39215686275,0) [0|25700] "Unit_PerCent"  BMS_Hybrid,Getriebe_Derivate,LEH_Hybrid
 SG_ OBD_Abs_Pedal_Pos : 40|8@1+ (0.39215686275,0) [0|100] "Unit_PerCent"  BMS_Hybrid,Getriebe_Derivate,LEH_Hybrid
 SG_ OBD_Driving_Cycle : 61|1@1+ (1,0) [0|1] ""  BMS_Hybrid,Getriebe_Derivate,LEH_Hybrid
 SG_ OBD_Warm_Up_Cycle : 62|1@1+ (1,0) [0|1] ""  BMS_Hybrid,Getriebe_Derivate,LEH_Hybrid,GW_Applikation_Derivate
 SG_ OBD_Normed_Trip : 63|1@1+ (1,0) [0|1] ""  LEH_Hybrid,BMS_Hybrid,Getriebe_Derivate
 SG_ OBD_Sperrung_IUMPR : 58|1@1+ (1,0) [0|1] ""  BMS_Hybrid
 SG_ OBD_Kaltstart_Denominator : 59|1@1+ (1,0) [0|1] ""  LEH_Hybrid,BMS_Hybrid
 SG_ OBD_Minimum_Trip : 60|1@1+ (1,0) [0|1] ""  LEH_Hybrid,Getriebe_Derivate,BMS_Hybrid

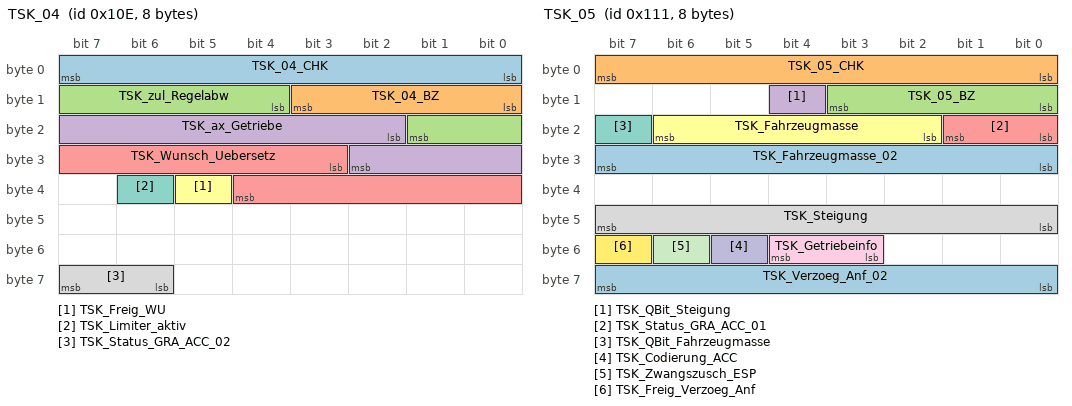
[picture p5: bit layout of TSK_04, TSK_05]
BO_ 270 TSK_04: 8 Motor_MED17_Hybrid
 SG_ TSK_04_CHK : 0|8@1+ (1,0) [0|255] ""  Getriebe_Derivate
 SG_ TSK_04_BZ : 8|4@1+ (1,0) [0|15] ""  Getriebe_Derivate
 SG_ TSK_zul_Regelabw : 12|6@1+ (0.024,0) [0|1.512] "Unit_MeterPerSeconSquar"  Getriebe_Derivate
 SG_ TSK_ax_Getriebe : 18|9@1+ (0.024,-2.016) [-2.016|10.224] "Unit_MeterPerSeconSquar"  Getriebe_Derivate
 SG_ TSK_Wunsch_Uebersetz : 27|10@1+ (0.0245,0) [0.0245|25.0635] "" Vector__XXX
 SG_ TSK_Freig_WU : 37|1@1+ (1,0) [0|1] "" Vector__XXX
 SG_ TSK_Limiter_aktiv : 38|1@1+ (1,0) [0|1] ""  Getriebe_Derivate
 SG_ TSK_Status_GRA_ACC_02 : 62|2@1+ (1,0) [0|3] ""  Getriebe_Derivate

BO_ 273 TSK_05: 8 Motor_MED17_Hybrid
 SG_ TSK_Fahrzeugmasse_02 : 24|8@1+ (32,0) [0|8128] "Unit_KiloGram"  GW_Routing_Derivate
 SG_ TSK_05_CHK : 0|8@1+ (1,0) [0|255] ""  PSM_Ant_Derivate,GW_Routing_Derivate,Getriebe_Derivate
 SG_ TSK_05_BZ : 8|4@1+ (1,0) [0|15] ""  PSM_Ant_Derivate,GW_Routing_Derivate,Getriebe_Derivate
 SG_ TSK_QBit_Steigung : 12|1@1+ (1,0) [0|1] ""  GW_Routing_Derivate
 SG_ TSK_Status_GRA_ACC_01 : 16|2@1+ (1,0) [0|3] ""  PSM_Ant_Derivate,GW_Routing_Derivate
 SG_ TSK_Fahrzeugmasse : 18|5@1+ (200,500) [500|6500] "Unit_KiloGram"  Getriebe_Derivate,GW_Routing_Derivate
 SG_ TSK_QBit_Fahrzeugmasse : 23|1@1+ (1,0) [0|1] ""  GW_Routing_Derivate
 SG_ TSK_Steigung : 40|8@1+ (0.8,-101.6) [-101.6|101.6] "Unit_PerCent"  GW_Routing_Derivate
 SG_ TSK_Getriebeinfo : 51|2@1+ (1,0) [0|3] ""  GW_Routing_Derivate
 SG_ TSK_Codierung_ACC : 53|1@1+ (1,0) [0|1] ""  GW_Routing_Derivate
 SG_ TSK_Zwangszusch_ESP : 54|1@1+ (1,0) [0|1] ""  GW_Routing_Derivate
 SG_ TSK_Freig_Verzoeg_Anf : 55|1@1+ (1,0) [0|1] ""  GW_Routing_Derivate
 SG_ TSK_Verzoeg_Anf_02 : 56|8@1+ (0.024,-3.984) [-3.984|2.136] "Unit_MeterPerSeconSquar"  GW_Routing_Derivate

BO_ 915 WBA_02: 8 Getriebe_Derivate
 SG_ WBA_GE_Zusatzwarnungen m0 : 39|3@1+ (1,0) [0|7] "" Vector__XXX
 SG_ WBA_Effizienzmodus : 14|1@1+ (1,0) [0|1] "" Vector__XXX
 SG_ WBA_Istgang m1 : 24|4@1+ (1,0) [0|15] "" Vector__XXX
 SG_ WBA_GE_Texte m0 : 32|3@1+ (1,0) [0|7] "" Vector__XXX
 SG_ WBA_Schaltschema_Aktiv m0 : 35|1@1+ (1,0) [0|1] "" Vector__XXX
 SG_ WH_Warnung m0 : 36|3@1+ (1,0) [0|7] "" Vector__XXX
 SG_ WBA_Sollgang m1 : 28|4@1+ (1,0) [0|15] "" Vector__XXX
 SG_ WBA_02_BZ : 8|4@1+ (1,0) [0|15] "" Vector__XXX
 SG_ WBA_Senderkennung M : 12|1@1+ (1,0) [0|1] "" Vector__XXX
 SG_ WBA_Lampe_Shift_Lock m0 : 13|1@1+ (1,0) [0|1] "" Vector__XXX
 SG_ WBA_Blinken m0 : 16|1@1+ (1,0) [0|1] ""  GW_Routing_Derivate
 SG_ WBA_Getriebevariante m0 : 17|4@1+ (1,0) [0|15] "" Vector__XXX
 SG_ WBA_GE_Warnung : 21|3@1+ (1,0) [0|7] ""  GW_Routing_Derivate
 SG_ WBA_Fahrstufe m0 : 24|4@1+ (1,0) [0|15] ""  GW_Routing_Derivate
 SG_ WBA_Schaltempf_verfbar m1 : 13|1@1+ (1,0) [0|1] "" Vector__XXX
 SG_ WBA_eing_Gang m0 : 28|4@1+ (1,0) [0|15] ""  GW_Routing_Derivate
 SG_ WBA_02_CHK : 0|8@1+ (1,0) [0|255] "" Vector__XXX

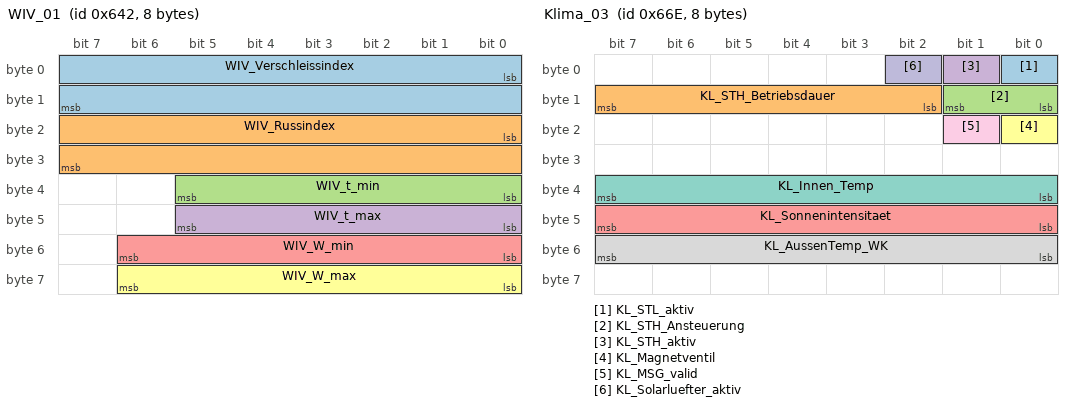
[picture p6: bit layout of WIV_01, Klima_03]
BO_ 1602 WIV_01: 8 Motor_MED17_Hybrid
 SG_ WIV_Verschleissindex : 0|16@1+ (2E-008,0) [0|0.00131068] ""  GW_Routing_Derivate
 SG_ WIV_Russindex : 16|16@1+ (2E-008,0) [0|0.00131068] ""  GW_Routing_Derivate
 SG_ WIV_t_min : 32|6@1+ (1,0) [0|63] "Unit_Month"  GW_Routing_Derivate
 SG_ WIV_t_max : 40|6@1+ (1,0) [0|63] "Unit_Month"  GW_Routing_Derivate
 SG_ WIV_W_min : 48|7@1+ (1000,0) [0|127000] "Unit_KiloMeter"  GW_Routing_Derivate
 SG_ WIV_W_max : 56|7@1+ (1000,0) [0|127000] "Unit_KiloMeter"  GW_Routing_Derivate

BO_ 1646 Klima_03: 8 GW_Routing_Derivate
 SG_ KL_STL_aktiv : 0|1@1+ (1,0) [0|1] "" Vector__XXX
 SG_ KL_STH_Betriebsdauer : 10|6@1+ (1,0) [0|60] "min" Vector__XXX
 SG_ KL_STH_Ansteuerung : 8|2@1+ (1,0) [0|3] "" Vector__XXX
 SG_ KL_STH_aktiv : 1|1@1+ (1,0) [0|1] "" Vector__XXX
 SG_ KL_Sonnenintensitaet : 40|8@1+ (10,0) [0|1000] "W/qm" Vector__XXX
 SG_ KL_Magnetventil : 16|1@1+ (1,0) [0|1] "" Vector__XXX
 SG_ KL_Innen_Temp : 32|8@1+ (0.5,-50) [-50|77.5] "°C"  BMS_Hybrid
 SG_ KL_AussenTemp_WK : 48|8@1+ (0.5,-50) [-50|76] "°C"  BMS_Hybrid
 SG_ KL_MSG_valid : 17|1@1+ (1,0) [0|1] "" Vector__XXX
 SG_ KL_Solarluefter_aktiv : 2|1@1+ (1,0) [0|1] "" Vector__XXX

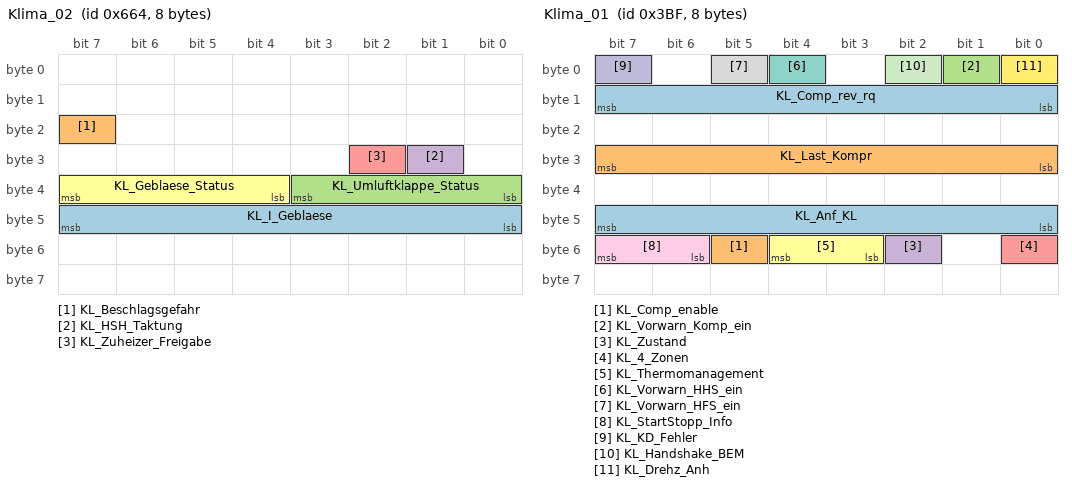
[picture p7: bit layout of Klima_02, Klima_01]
BO_ 1636 Klima_02: 8 GW_Routing_Derivate
 SG_ KL_I_Geblaese : 40|8@1+ (0.25,0) [0|63.5] "Unit_Amper" Vector__XXX
 SG_ KL_Beschlagsgefahr : 23|1@1+ (1,0) [0|1] "" Vector__XXX
 SG_ KL_Umluftklappe_Status : 32|4@1+ (1,0) [0|15] ""  BMS_Hybrid
 SG_ KL_HSH_Taktung : 25|1@1+ (1,0) [0|1] "" Vector__XXX
 SG_ KL_Zuheizer_Freigabe : 26|1@1+ (1,0) [0|1] "" Vector__XXX
 SG_ KL_Geblaese_Status : 36|4@1+ (1,0) [0|15] ""  BMS_Hybrid

BO_ 959 Klima_01: 8 GW_Routing_Derivate
 SG_ KL_Comp_rev_rq : 8|8@1+ (50,0) [0|8600] "Unit_MinutInver" Vector__XXX
 SG_ KL_Comp_enable : 53|1@1+ (1,0) [0|1] "" Vector__XXX
 SG_ KL_Vorwarn_Komp_ein : 1|1@1+ (1,0) [0|1] ""  Motor_EDC17_Pirol,Motor_MED17_Hybrid
 SG_ KL_Zustand : 50|1@1+ (1,0) [0|1] ""  BMS_Hybrid,Motor_EDC17_Pirol,Motor_MED17_Hybrid
 SG_ KL_4_Zonen : 48|1@1+ (1,0) [0|1] ""  Motor_EDC17_Pirol,Motor_MED17_Hybrid
 SG_ KL_Thermomanagement : 51|2@1+ (1,0) [0|3] ""  Motor_EDC17_Pirol,Motor_MED17_Hybrid
 SG_ KL_Vorwarn_HHS_ein : 4|1@1+ (1,0) [0|1] ""  Motor_EDC17_Pirol,Motor_MED17_Hybrid
 SG_ KL_Vorwarn_HFS_ein : 5|1@1+ (1,0) [0|1] ""  Motor_EDC17_Pirol,Motor_MED17_Hybrid
 SG_ KL_StartStopp_Info : 54|2@1+ (1,0) [0|3] ""  Motor_EDC17_Pirol,Motor_MED17_Hybrid
 SG_ KL_KD_Fehler : 7|1@1+ (1,0) [0|1] "" Vector__XXX
 SG_ KL_Handshake_BEM : 2|1@1+ (1,0) [0|1] "" Vector__XXX
 SG_ KL_Drehz_Anh : 0|1@1+ (1,0) [0|1] ""  Motor_EDC17_Pirol,Motor_MED17_Hybrid
 SG_ KL_Anf_KL : 40|8@1+ (0.4,0) [0|100] "%"  Motor_EDC17_Pirol,Motor_MED17_Hybrid
 SG_ KL_Last_Kompr : 24|8@1+ (0.25,0) [0|63.5] "Nm"  Motor_EDC17_Pirol

BO_ 2041 Response_Airbag_Deployment: 8 Airbag
 SG_ Response_Airbag_Deployment : 0|64@1+ (1,0) [0|4294967295] ""  GW_Routing_Derivate

BO_ 2033 Request_Airbag_Deployment: 8 GW_Routing_Derivate
 SG_ Request_Airbag_Deployment : 0|64@1+ (1,0) [0|4294967295] ""  Airbag

BO_TX_BU_ 128 : Motor_EDC17_Pirol,Motor_MED17_Hybrid;
BO_TX_BU_ 129 : Motor_EDC17_Pirol,Motor_MED17_Hybrid;
BO_TX_BU_ 261 : Motor_EDC17_Pirol,Motor_MED17_Hybrid;
BO_TX_BU_ 263 : Motor_EDC17_Pirol,Motor_MED17_Hybrid;
BO_TX_BU_ 782 : Motor_EDC17_Pirol,Motor_MED17_Hybrid;
BO_TX_BU_ 1088 : Motor_EDC17_Pirol,Motor_MED17_Hybrid;
BO_TX_BU_ 1600 : Motor_EDC17_Pirol,Motor_MED17_Hybrid;
BO_TX_BU_ 1601 : Motor_EDC17_Pirol,Motor_MED17_Hybrid;
BO_TX_BU_ 933 : Motor_EDC17_Pirol,Motor_MED17_Hybrid;
BO_TX_BU_ 1729 : Motor_EDC17_Pirol,Motor_MED17_Hybrid;
BO_TX_BU_ 913 : Motor_EDC17_Pirol,Motor_MED17_Hybrid;
BO_TX_BU_ 270 : Motor_EDC17_Pirol,Motor_MED17_Hybrid;
BO_TX_BU_ 273 : Motor_EDC17_Pirol,Motor_MED17_Hybrid;
BO_TX_BU_ 1602 : Motor_EDC17_Pirol,Motor_MED17_Hybrid;
CM_ SG_ 1089 GE_OBD_AbsperrVent "Das Getriebesteuergerät führt eine elektrische Diagnose des von ihm angesteuerten Absperrventils für den Öl-Wasser-Wärmetauscher durch und übermittelt das Ergebnis an das MSG (Standard-4Bit-OBD-Status, nicht alle Zustände müssen genutzt werden; so sind z.";
CM_ SG_ 1089 GE_Freigabe_Verfallsinfo_WFS "WFS";
CM_ SG_ 1089 GE_Index_Fahrwid "Auf % Steigung am Berg normiert";
CM_ SG_ 1089 GE_OBD_Status "Dieses Bit steuert die MIL-Lampe an (Motorsteuergerät reicht diese Info an Kombi weiter).";
CM_ SG_ 1089 GE_LFR_Adaption "Da das VL30-Getriebe im Stillstand unter gewissen Randbedingungen wechselnde Kupplungsmomente einstellt (z.B. Hillholder), sollte die Leerlaufauffüllungsadaption im Motorsteuergerät für diese Zustände gesperrt werden. 

";
CM_ SG_ 1089 GE_Grenzkriechmoment "Achtung:
Einheitenloser CAN-Wert.
Faktor in MO_Faktor_Momente in Motor_Code_01 beachten!

Es gilt: Signalspec GE_Grenzkriechmoment v1.0

Maximales Kupplungs-/Wandlermoment im Leerlauf. Darin sind motorische Umwelteinflüsse enthalten. CAN-Wert = 0,5 ";
CM_ SG_ 1089 GE_Charisma_FahrPr "Aktuelles Fahrprogramm des Charisma-Teilnehmers

Achtung neue Modusnamen (wie im MMI):

0x1 = Komfort = Comfort
0x2 = Dynamik = Auto
0x3 = Sport = Dynamic";
CM_ SG_ 1089 GE_Charisma_Status "Charisma Systemstatus des Charisma-Teilnehmers";
CM_ SG_ 1089 GE_Charisma_Umschaltung "Erkennung  Umschaltaufforderung des Charisma-Teilnehmers";
CM_ SG_ 1089 GE_Verlustmoment "Achtung:
Einheitenloser CAN-Wert.
Faktor in MO_Faktor_Momente in Motor_Code_01 beachten!

Es gilt: Signalspec GE_Verlustmoment v1.0

Verlustmoment inklusive Pumpenaufnahmemoment (Rechenwert aus CAN-Werten und Kennfeldern ermittelt). Inhalt wird alle";
CM_ SG_ 1089 GE_amax_moeglich "Fzg mit Stufenautomat: Maximale mögliche Beschleunigung bei der jetzigen Übersetzung (Übertragungsfunktion), bezogen auf Begrenzungsmoment, Fahrzeugmasse, Fahrwiderstandsindex und Motor Stressfaktor

Fzg mit stufenlosem Getriebe: Maximale mögliche Besch";
CM_ SG_ 1089 GE_Sumpftemperatur "Getriebesumpftemperatur wird über den Temperatursensor auf der Getriebeplatine ermittelt. Die absolute Sumpftemperatur wird vom Motor empfangen, um entsprechende Kühlleistung für das Getriebe einzustellen.";
CM_ BO_ 158 "Motor - Getriebe - Schnittstelle auf CAN-Antrieb (PL72H)";
CM_ SG_ 158 Getriebe_Hybrid_01_CHK "Berechnung siehe Lastenheft 'Kommunikationsabsicherung für FlexRay und CAN'
Endwerte siehe 'Kommunikationsabsicherung für FlexRay und CAN / Anhang C: Tabelle S-PDU Kennungen'


";
CM_ SG_ 158 Getriebe_Hybrid_01_BZ "überlaufender 4bit Botschaftszaehler; wird in jeder Sendebotschaft inkrementiert";
CM_ SG_ 158 GE_HYB_Fehlerstatus "Hybrid-spezifische Fehlerstati
PQ3x: Fehlerstatus x1b signalisiert, dass der Druck zum Öffnen der K0 nicht ausreicht (nach Kl15 ein)
PL71: Fehlerstatus x1b signalisiert eine unzureichende Druckversorgung durch die EOP.
Fehlerstatus 1xb : Verhinderung u";
CM_ SG_ 158 GE_HYB_Freigabe_K0 "PQ3x: Bit ist Zwangsanforderung für Status der K0
0 = K0 auf
1 = K0 zu
PL72: Übergang von 0 nach 1 (bzw von 1 nach 0) ist Teil des Wiederstart- (Stop-) Handshakes
0 = Freigabe K0 öffnen
1 = Freigabe K0 schließen";
CM_ SG_ 158 GE_HYB_Freigabe_LL_Reg "GSG gibt hier die Aktivierung einer DZ-Regelung von VM und/oder EM frei. (Verhinderung Selbstbeschleuniger)";
CM_ SG_ 158 GE_HYB_Freig_sSchl_K0 "PL72 Hybrid: GSG zeigt an, dass K0 bei Wiederstart schnell geschlossen werden soll (Zweck: Verwendung des folgenden DZ-Sprunges zur Synchronisierung)";
CM_ SG_ 158 GE_HYB_Freig_VM_EM_Stop "Signalisiert Bereitschaft GSG, dass VM gestoppt werden darf (Soft Stop) oder dass EM gestoppt werden darf (Übergang EM-Fahren => EMFahrbereitschaft)";
CM_ SG_ 158 GE_HYB_Wiederstart "Getriebe zeigt an, ob Wiederstart aktiv ist.";
CM_ SG_ 158 GE_HYB_nK0 "Nur PQ3x Hybrid:
GSG teilt MSG mit, auf welcher DZ die EM nach schnellem Schließen der K0 und nach DZAngleichung durch das GSG landen wird.
Wenn Signal 'Wiederstart' nicht aktiv: EM-Drehzahl wird gespiegelt.
Wenn Signal 'Wiederstart' aktiv: DZ, auf der";
CM_ SG_ 158 GE_HYB_MomEingriff_EM "Nur PQ3x Hybrid: Direkter Eingriff des GSG auf EM.
Ist der Betrag des Absolutwertes des Eingriffsmomentes in Nm. Verwendet zur Dämpfung des Triebstranges nach Impulsstart, wenn VM-Momente noch ungenau sind.
E-Gas-Sicherheit: begrenzt auf 30 Nm, zusätzli";
CM_ SG_ 158 GE_HYB_VZ_MomEingriff_EM "PQ3x Hybrid:Vorzeichen für Getriebeeingriff auf EM (MomEingriff_EM)";
CM_ SG_ 158 GE_HYB_Sportfaktor "Sportlichkeitsfaktor Getriebe, zur Verwendung in der Hybrid-Fahrstrategie
0 = nicht sportlich
1..15 = sportlich";
CM_ SG_ 158 GE_HYB_VM_akt_halten "Im elektrischen Fahren/Tipp: Übergang von 0 auf 1 zeigt VM-Startanforderung des GSG an.
Empfehlung GSG an MSG, dass VM aktiv gehalten werden soll. Verwendbar z.B. bei den Funktionen 'fast off (Gang halten)' oder bei 'Rückschaltung bei Bremsen'.";
CM_ SG_ 158 GE_HYB_StartAnf "Auslösen des VM_Widerstart bei EM-Betrieb";
CM_ SG_ 158 GE_HYB_VM_Startkontr "Freigabe der Wiederstartkontrolle";
CM_ SG_ 158 GE_HYB_Filt_MomAufbau "Faktor, der im MSG zur Berechnung der Filterkonstanten für den Fahrerwunschmomentenaufbau im Impulsstart verwendet wird.";
CM_ SG_ 1720 KBI_Tankfuellstand_Prozent "Tankfüllstand in %";
CM_ SG_ 1720 KBI_Tankinhalt_hochaufl "angezeigter Tankinhalt hochauflösend zur Restreichweitenberechnung";
CM_ SG_ 1720 KBI_Nachtanken_erkannt "Statusinformation Nachtankmodus";
CM_ SG_ 1720 KBI_Reifenumfang "Mittlerer Radumfang aus der K-Zahl gerechnet in Millimeter.  Byte 2 Bit 5,4 reserviert, Byte 2 Bit 3..0 und Byte 1 Bit 7..0; Wertebereich 0..4096 mm
";
CM_ SG_ 128 Motor_01_CHK "Berechnung siehe Lastenheft 'Kommunikationsabsicherung für FlexRay und CAN'
Endwerte siehe 'Kommunikationsabsicherung für FlexRay und CAN / Anhang C: Tabelle S-PDU Kennungen'";
CM_ SG_ 128 MO_Mom_o_ex "Achtung:
Einheitenloser CAN-Wert.
Faktor in MO_Faktor_Momente in Motor_Code_01 beachten!

Indiziertes Motormoment ohne externe Eingriffe (ASR, MSR, Getriebe ...) aber inklusive integrierter GRA";
CM_ SG_ 128 MO_Mom_m_ex "Achtung:
Einheitenloser CAN-Wert.
Faktor in MO_Faktor_Momente in Motor_Code_01 beachten!

Indiziertes Motormoment, d.h. idealisiertes berechnetes Moment ohne mechanische Verluste, aber mit externen Eingriffen.";
CM_ SG_ 128 MO_Mom_Verlust "Achtung:
Einheitenloser CAN-Wert.
Faktor in MO_Faktor_Momente in Motor_Code_01 beachten!

Beinhaltet z.Zt. Reibung vom Motor und Klimakompressor, beim TDI z.T. auch die Generatorverluste";
CM_ SG_ 128 MO_Mom_Begrenzung "Achtung:
Einheitenloser CAN-Wert.
Faktor in MO_Faktor_Momente in Motor_Code_01 beachten!

Inneres maximal mögliches Moment bei einer Drehzahl (z.B. Rauchbegrenzung oder Fehlerfall)";
CM_ SG_ 128 MO_Mom_Fahrerwunsch "Achtung:
Einheitenloser CAN-Wert.
Faktor in MO_Faktor_Momente in Motor_Code_01 beachten!

Moment vor Filter, nutzbar zur Zug- / Schuberkennung beim Getriebe (beim Diesel identisch mit innerem Moment ohne externe Eingriffe)";
CM_ SG_ 128 MO_Kickdown "Es gilt: Signalspec MO_Kickdown v1.0";
CM_ SG_ 128 MO_KD_Fehler "Kundendienstfehlerspeicherbit";
CM_ SG_ 129 MO_StartStopp_Wiederstart "Motorwiederstart durch Start/Stopp-Koordinator";
CM_ SG_ 129 MO_StartStopp_Status "St/St-Koordinator Systemstatus
zu Wert=1: Fehlerstatus erkannt oder Sicherheitsabschaltung aktiv (zeitabh. Grösse 1. innerhalb von 500ms kein Verbau St/St-Funktion 2. Nach Ablauf der Zeit kein St/St im aktuellen Fahrzyklus)
Initialwert ab Matrix 5.2=2";
CM_ SG_ 129 MO_StartStopp_Motorstopp "Motor-Stopp durch Start/Stopp-Koordinator";
CM_ SG_ 129 MO_StartStopp_Fahrerwunsch "Fahreraktivität Start/Stop";
CM_ SG_ 129 Motor_02_CHK "Berechnung siehe Lastenheft 'Kommunikationsabsicherung für FlexRay und CAN'
Endwerte siehe 'Kommunikationsabsicherung für FlexRay und CAN / Anhang C: Tabelle S-PDU Kennungen'";
CM_ SG_ 129 MO_Mom_ZWR "Minimales Motormoment bei Zündwinkelrücknahme.

Achtung:
Einheitenloser CAN-Wert.
Faktor in MO_Faktor_Momente in Motor_Code_01 beachten!";
CM_ SG_ 129 MO_Mom_Soll "Achtung:
Einheitenloser CAN-Wert.
Faktor in MO_Faktor_Momente in Motor_Code_01 beachten!

Sollmoment ohne P und D Anteil des Leerlaufreglers, ohne Antiruckelfunktion und ohne Getriebeeingriff";
CM_ SG_ 129 MO_Mom_Ist "Achtung:
Einheitenloser CAN-Wert.
Faktor in MO_Faktor_Momente in Motor_Code_01 beachten!

Istmoment ohne P und D Anteil des Leerlaufreglers, ohne Antiruckelfunktion und ohne Getriebeeingriff";
CM_ SG_ 129 MO_Status_Zylabschalt_01 "Statusbit: Motor ist in Zylinderabschaltregelung";
CM_ SG_ 129 MO_Status_Normalbetrieb_01 "Das Motorsteuergerät sendet das Informationsbit, wenn die Initialisierungsphase des Steuergerätes abgeschlossen ist. Zusätzlich muss die Klemme 15 eingeschalten sein und eine applizierbare Mindestdrehzahlschwelle (Kennlinie in Abh. von der Kühlwassertempe";
CM_ SG_ 129 MO_Momentenintegral "100 %  entspricht volle Verfügbarkeit aktuell vorhanden. 0 % entspricht Integral bis Limit gefüllt, erhöhender Eingriff kann aktuell nicht berücksichtigt werden oder erhöhender Eingriff ist in diesem Projekt nicht möglich (applikativ deaktiviert) oder auf";
CM_ SG_ 129 MO_Gangposition "Stellung des Wählhebels in der Schaltgasse des Handschaltgetriebes.
(Signal wird im Panamera nicht bedient)";
CM_ SG_ 129 MO_Ext_E_Fahrt_aktiv "Rückmeldung E-Taster (Hybrid-Signal, wird im E2H in der Motor_K_02 gesendet.)
(Signal wird nur im Panamera Hybrid bedient)";
CM_ BO_ 261 "Motor_03:

Im B8/Q5: 20ms

sonst: 10ms";
CM_ SG_ 261 MO_QBit_Motormomente "AUDI D4: Zykluszeit: 10ms (siehe Zykluszeit schnell/Cycletime Fast)

Ungenaue Momentenangaben, weil die Momente aus Ersatzwerten berechnet wurden (z.B. HFM ausgefallen). Qualifizierungsbit für die Motormomente.

Achtung:
Reduktion der Zykluszeit Moto";
CM_ SG_ 261 Motor_03_CHK "Berechnung siehe Lastenheft 'Kommunikationsabsicherung für FlexRay und CAN'
Endwerte siehe 'Kommunikationsabsicherung für FlexRay und CAN / Anhang C: Tabelle S-PDU Kennungen'";
CM_ SG_ 261 Motor_03_BZ "AUDI D4: Zykluszeit: 10ms (siehe Zykluszeit schnell/Cycletime Fast)

Achtung:
Reduktion der Zykluszeit Motor_03 auf 10ms geplant.
Projektabhängig soll künftig mit 10ms gesendet werden.
Empfänger die in weiteren Konzern-Projekten eingesetzt werden müs";
CM_ SG_ 261 MO_QBit_Fahrpedalwerte_01 "AUDI D4: Zykluszeit: 10ms (siehe Zykluszeit schnell/Cycletime Fast)

QBit für beide Fahrpedalwerte des Motors (Fahrpedalrohsignal für ESP, EPB, ACC; Fahrpedalwert für Getriebe)

Achtung:
Reduktion der Zykluszeit Motor_03 auf 10ms geplant.
Projektabh";
CM_ SG_ 261 MO_QBit_Fahrer_bremst "AUDI D4: Zykluszeit: 10ms (siehe Zykluszeit schnell/Cycletime Fast)

Achtung:
Reduktion der Zykluszeit Motor_03 auf 10ms geplant.
Projektabhängig soll künftig mit 10ms gesendet werden.
Empfänger die in weiteren Konzern-Projekten eingesetzt werden müs";
CM_ SG_ 261 MO_QBit_Drehzahl_01 "AUDI D4: Zykluszeit: 10ms (siehe Zykluszeit schnell/Cycletime Fast)

Achtung:
Reduktion der Zykluszeit Motor_03 auf 10ms geplant.
Projektabhängig soll künftig mit 10ms gesendet werden.
Empfänger die in weiteren Konzern-Projekten eingesetzt werden müs";
CM_ SG_ 261 MO_Drehzahl_01 "AUDI D4: Zykluszeit: 10ms (siehe Zykluszeit schnell/Cycletime Fast)

Im Fehlerfall wird die Motordrehzahl über die Nockenwellendrehzahl als Ersatzgrösse ausgegeben

Achtung:
Reduktion der Zykluszeit Motor_03 auf 10ms geplant.
Projektabhängig soll kü";
CM_ SG_ 261 MO_Moment_im_Leerlauf "AUDI D4: Zykluszeit: 10ms (siehe Zykluszeit schnell/Cycletime Fast)

Achtung:
Einheitenloser CAN-Wert.
Faktor in MO_Faktor_Momente in Motor_Code_01 beachten!

Motorbetriebszustand ist Leerlauf, keine Momentenerhöhung durch Fahrpedal, ACC, GRA+

Ac";
CM_ SG_ 261 MO_Interlock "Das Motorsteuergerät gibt die Information aus, ab wann der Kupplungsschalter durch das Motorsteuergerät als getreten gesehen wird.
Bei Systemen für Start Stopp muss das Interlocksignal für einen Start durch das MSG generiert werden, sobald der Schalthebe";
CM_ SG_ 261 MO_BLS "AUDI D4: Zykluszeit: 10ms (siehe Zykluszeit schnell/Cycletime Fast)

Ungefiltertes Rohsignal des Bremslichtschalters, nur wenn HW-Eingang bestückt und ausgewertet wird. Bei Motoren ohne genutzten HW-Eingang wird kein Ersatzwert (bspw. SW-Signal über CAN";
CM_ SG_ 261 MO_Fahrer_bremst "Redundante Bremsinformation vom Motor. Im B8 wird in diesem Bit der Wert der ESP-CAN-Information 'ESP_Fahrer_bremst' ausgegeben.
Achtung:
Reduktion der Zykluszeit Motor_03 auf 10ms
(in Gateway_01_VW: Signal wird nur im Panamera H/P bedient)";
CM_ SG_ 261 MO_Konsistenz_Bremsped "AUDI D4: Zykluszeit: 10ms (siehe Zykluszeit schnell/Cycletime Fast)

Siehe 'Funktionsspezifikation Bremslichtinfo B8'

Achtung:
Reduktion der Zykluszeit Motor_03 auf 10ms geplant.
Projektabhängig soll künftig mit 10ms gesendet werden.
Empfänger die";
CM_ SG_ 261 MO_Kuppl_schalter "AUDI D4: Zykluszeit: 10ms (siehe Zykluszeit schnell/Cycletime Fast)

Nur Handschalter; aktiv, wenn Schalter verbaut; sonst konstant auf '0' gesetzt; Bit wird gesetzt, wenn Kupplungspedal betätigt wird (Kupplungsschalter hoch), Triebstrang kann noch eing";
CM_ SG_ 261 MO_Timeout_ESP "AUDI D4: Zykluszeit: 10ms (siehe Zykluszeit schnell/Cycletime Fast)

500 ms Timeout auf Bremsen-Botschaft ist >= 1 mal aufgelaufen, Löschen des Bits nach Neustart (KL15).

Achtung:
Reduktion der Zykluszeit Motor_03 auf 10ms geplant.
Projektabhängig ";
CM_ SG_ 261 MO_Motor_laeuft "AUDI D4: Zykluszeit: 10ms (siehe Zykluszeit schnell/Cycletime Fast)

Es gilt: Signalspec MO_Motor_laeuft v1.0

Dieses Bit signalisiert, dass der Motor autark läuft und mechanisch belastbar ist. Das Bit wird abhängig von den Umgebungsbedingungen gesetz";
CM_ SG_ 261 MO_Solldrehz_Leerlauf "AUDI D4: Zykluszeit: 10ms (siehe Zykluszeit schnell/Cycletime Fast)

Leerlaufsolldrehzahl, die im Motor eingestellt ist. Der Motor paßt aufgrund der Anforderung von anderen
Steuergeräten seine Leerlaufsolldrehzahl an, bspw. Kat-Heizen, Anforderung vom ";
CM_ SG_ 261 MO_Fahrpedalrohwert_01 "AUDI D4: Zykluszeit: 10ms (siehe Zykluszeit schnell/Cycletime Fast)

Stellung des Fahrpedales (Rohwert, ohne Überlagerung durch GRA-Eingriffe etc.)

Die Funktionen zur Berechung des Fahrpedalrohwerts laufen im 10ms Raster. Der Fahrpedalwert berechnet ";
CM_ SG_ 261 MO_erste_Ungenauschwelle "AUDI D4: Zykluszeit: 10ms (siehe Zykluszeit schnell/Cycletime Fast)

Zusätzliche Ungenauigkeit (zur Grundungenauigkeit). Motormomente ungenau >8% (kleinste Ungenauschwelle)

Achtung:
Reduktion der Zykluszeit Motor_03 auf 10ms geplant.
Projektabhängi";
CM_ SG_ 261 MO_QBit_Stressfaktor "AUDI D4: Zykluszeit: 10ms (siehe Zykluszeit schnell/Cycletime Fast)

Achtung:
Reduktion der Zykluszeit Motor_03 auf 10ms geplant.
Projektabhängig soll künftig mit 10ms gesendet werden.
Empfänger die in weiteren Konzern-Projekten eingesetzt werden müs";
CM_ SG_ 261 MO_Stressfaktor "AUDI D4: Zykluszeit: 10ms (siehe Zykluszeit schnell/Cycletime Fast)

Berücksichtigung von Höhe und Ansauglufttemperatur im aktuellen Betriebspunkt. Berücksichtigung bei Berechnung der ACC-Sollbeschleunigung. Fehlerwert existiert nicht, 0x3F ist gültiger";
CM_ SG_ 263 MO_Anzeigedrehz "Ausgabe einer gefilterten Anzeigendrehzahl während des Starts für die Ausgabe im Drehzahlmesser des Kombiinstruments.";
CM_ SG_ 263 MO_KVS "Motorsteuergerätinterner Verbrauchszähler, der vom Kombi zyklisch ausgelesen wird, um die Einspritzmenge zur Verbrauchsmessung aufzusummieren; aus diesem Zählerstand werden Momentan- und Durchschnittsverbrauch berechnet; das Überlauf-Bit ist zu berücksich";
CM_ SG_ 263 MO_KVS_Ueberlauf "Der motorsteuergeräteinterne Verbrauchszähler ist mindestens einmal übergelaufen. Dieses Bit wird genutzt, um erkennen zu können, daß das Motorsteuergerät aus dem Reset-Zustand hochläuft.";
CM_ SG_ 263 MO_Ladedruck "Zur Anzeige im Kombi, z.Zt. nur Porsche Colorado und PQ35 Biturbo, ab B8 Vorhalt";
CM_ SG_ 263 MO_Oeldruck_HYB "Öldruck analog zur Anzeige
(Signal wird im Panamera nicht bedient)";
CM_ SG_ 263 MO_Istgang "Wenn Motor die WBA-Botschaft sendet wird in diesem Signal der aktuelle Gang ausgegeben (= Istgang des Schaltgetriebes). Nur falls WBA_Senderkennung = 01 (MSG).
(Signal wird im Panamera nicht bedient)";
CM_ SG_ 263 MO_Schaltempf_verfbar "Info, ob Schaltempfehlung im Fzg. verfügbar. Statischer Wert, ändert sich für ein Fzg nicht - nur falls WBA_Senderkennung = 01 (MSG)
(Signal wird im Panamera nicht bedient)";
CM_ SG_ 263 MO_Sollgang "Motor sendet den Sollgang in den der Fahrer schalten soll. Wird im Kombi als Hochschaltempfehlung hervorgehoben. Nur falls WBA_Senderkennung = 01 (MSG)
(Signal wird im Panamera nicht bedient)";
CM_ SG_ 782 MO_Handshake_STH "Es gilt: Signalspec MO_Handshake v1.0

Handshake zwischen MSG und STH. Wenn das MSG die EKP aufgrund einer STH-Anforderung ansteuert und kein Fehlereintrag bzgl. EKP/KPE/NDR vorliegt, wird das Bit gesetzt.";
CM_ SG_ 782 Motor_05_CHK "Berechnung siehe Lastenheft 'Kommunikationsabsicherung für FlexRay und CAN'
Endwerte siehe 'Kommunikationsabsicherung für FlexRay und CAN / Anhang C: Tabelle S-PDU Kennungen'";
CM_ SG_ 782 MO_EKlKomLeiRed "Anforderung an die Klimasteuerung, die Leistungsaufnahme des E-Kompressors bei schlechtem SOC und in bestimmten Fahrsituationen zu begrenzen...
(Signal wird nur im Hybrid bedient)";
CM_ SG_ 782 MO_Freig_Reku "Empfehlung des Motor-SG's zur Spannungsabsenkung/-anhebung für den Rekuperationsbetrieb";
CM_ SG_ 782 MO_Klima_Eingr "Eingriffe des Motor bei der Klima";
CM_ SG_ 782 MO_Status_Normalbetrieb_02 "Signal ausschließlich für AUDI B8.
Auch im B8 nur GSG Empfänger dieses Signales.
Alle weiteren Fahrzeuge verwenden das Signal in Motor_02.
(Signal wird im Panamera nicht bedient)";
CM_ SG_ 782 MO_Schaltbeeinfl_Leistungsbegr "Schaltbeeinflussung an das Getriebe wegen Leistungsbegrenzung";
CM_ SG_ 782 MO_Schaltbeeinfl_Partikelfilter "Schaltbeeinflussung an das Getriebe wegen Partikelfilter-Regeneration
(Signal wird nur im Panamera Pirol bedient)
";
CM_ SG_ 782 MO_Prio_MIN_Wunschdrehzahl "Motorwunschdrehzahl ist als Zwang oder als Wunsch an das Getriebe zu interpretieren";
CM_ SG_ 782 MO_Freig_Anlass "Bit wird gesetzt, wenn der Motor beim Automatikstart gestartet werden darf (Motorstillstand, Emissionsmaßnahmen sind erfüllt).";
CM_ SG_ 782 MO_Aussp_Anlass "Bit wird gesetzt, wenn der Motorhochlauf ohne Anlasserunterstützung beendet werden kann oder ein Start-Timeout erreicht wurde.
(in Gateway_01_VW: Signal wird nur im Panamera H/P bedient)";
CM_ SG_ 782 MO_MAX_Wunschdrehzahl "Wenn das Bit 'MO_Prio_MAX_Wunschdrehzahl' gesetzt wird, wird hier vom Motor-SG eine wegen Partikelfilterregeneration bedingte minimale Motordrehzahl ausgegeben, die das Getriebe-SG nicht unterschreiten darf...
(Signal wird nur im Panamera Pirol bedient)";
CM_ SG_ 782 MO_Prio_MAX_Wunschdrehzahl "Motorwunschdrehzahl in Byte 4 ist als Zwang oder als Wunsch an das Getriebe zu interpretieren
(Signal wird nur im Panamera Pirol bedient)";
CM_ SG_ 782 MO_Luftpfad_aktiv "Getriebeeingriff wird zusätzlich zum Zündungspfad auch über den Luftpfad umgesetzt, kommt zu B8 neu in die PL48-Getriebe";
CM_ SG_ 782 MO_v_Begrenz_Aktiv "Motor begrenzt aktuell die Geschwindigkeit des Fahrzeugs; Reaktion auf externe oder interne Anforderung
(Signal wird im Panamera nicht bedient)";
CM_ SG_ 782 MO_v_Begrenz_Aktivierbar "Fehlerbit wird vom Motor-SG gesetzt, wenn dieses nicht in dieGeschwindigkeits-begrenzung gehen kann, ein Fehler während der v-Begrenzung auftritt oder v > v_Begrenzung - v_Delta";
CM_ SG_ 782 MO_Verbot_EKP "Es gilt: Signalspec MO_Verbot_EKP V1.1
MSG sendet Verbot der EKP-Ansteuerung an das BCM
(Signal wird im Panamera nicht bedient)";
CM_ SG_ 782 MO_Anf_Pruefimpuls "Es gilt: Signalspec MO_Anf_Pruefimpuls v1.1
Anforderung des MSG an das BCM  zum Senden eines Prüfimpulses zur Diagnose der Wakeup-Leitung auf Dauerlow
(Signal wird im Panamera nicht bedient)";
CM_ SG_ 782 MO_Anf_KL75 "Information wann die Kl. 75 während des Startvorgangs abgeschaltet werden soll. Umsetzung durch BCM2.";
CM_ SG_ 782 MO_Charisma_FahrPr "Aktuelles Fahrprogramm des Charisma-Teilnehmers

Achtung neue Modusnamen (wie im MMI):

0x1 = Komfort = Comfort
0x2 = Dynamik = Auto
0x3 = Sport = Dynamic";
CM_ SG_ 782 MO_Charisma_Status "Charisma Systemstatus des Charisma-Teilnehmers";
CM_ SG_ 782 MO_Charisma_Umschaltung "Erkennung  Umschaltaufforderung des Charisma-Teilnehmers";
CM_ SG_ 782 MO_MIN_Wunschdrehzahl "Wenn das Bit 'MO_Prio_MIN_Wunschdrehzahl' gesetzt wird, wird vom Motor-SG wegen Partikelfilterregeneration wird eine minimale Motordrehzahl ausgegeben, die das Getriebe-SG nicht unterschreiten darf.
(Signal wird nur im Panamera Pirol bedient)";
CM_ SG_ 782 MO_Drehzahlbeeinflussung "Mit diesem Faktor kann das Motorsteuergerät die vom CVT-Getriebe einzustellende Sollmotodrehzahl beeinflussen. Im CVT-Steuergerät ist ein verbrauchsoptimales Kennfeld und ein abgasoptimiertes Kennfeld abgelegt. Mit dem Wert von 0-100% wird zwischen diesen";
CM_ BO_ 1088 "Botschaft von MED17 (G1Hybrid)";
CM_ SG_ 1088 MO_Kat_Warnung "Das Signal lässt im Kombi des LB83x eine Warnlampe angehen um eine Überhitzung des Katalysators zu signalisieren
(Signal wird im Panamera nicht bedient)";
CM_ SG_ 1088 MO_ITM_Warnung_Pumpe "Textanzeige: 'Motor sofort abstellen, geschaltete Wasserpumpe defekt / klemmt'";
CM_ SG_ 1088 MO_HYB_Text_4 "Textanzeige: E-Mode unterbrochen (passiv)
(Signal wird nur im Panamera Hybrid bedient)";
CM_ SG_ 1088 MO_HYB_Status_HV_Ladung "Statusanzeige für Funktion HV-Ladung über 12V-Seite
(Signal wird im Panamera nicht bedient)";
CM_ SG_ 1088 MO_Zustand_HWP "Rückmeldung des  Ansteuerzustand der Hauptwasserpumpe an das Klima-SG .
Der Zustand 'HWP fördert' wird übermittelt, wenn die Schaufeln der Hauptwasserpumpe frei drehen können und die Motordrehzahl und damit die Wasserpumpendrehzahl größer als Null ist. B";
CM_ SG_ 1088 MO_Kuehlerluefter_MUX "Multiplexer für das Signal 'MO_Kuehlerlüfter'";
CM_ SG_ 1088 MO_Kuehlerluefter_1 "Ansteuertastverhaeltnis (PWM) der Kuehlerluefterendstufe 1";
CM_ SG_ 1088 MO_Kuehlerluefter_2 "Ansteuertastverhaeltnis (PWM) der Kuehlerluefterendstufe 2";
CM_ SG_ 1088 WIV_Anzeige_aktiv "Peilstabsanzeigefunktion aktiv";
CM_ SG_ 1088 WIV_Oelmin_Warn "Min-Warnung";
CM_ SG_ 1088 WIV_Sensorfehler "Ölstand/Öltemperatursensor (TOG) defekt";
CM_ SG_ 1088 WIV_Schieflage "Fahrzeug steht nicht waagerecht, Messung ungenau";
CM_ SG_ 1088 WIV_Oelstand "8 Segmente zur Balkenanzeige des Ölstands";
CM_ SG_ 1088 WIV_Oelsystem_aktiv "Gesamtölsystem aktiv (entspricht Ölsensor verbaut)";
CM_ SG_ 1088 WIV_nicht_betriebswarm "Motor nicht betriebswarm, Messung ungenau";
CM_ SG_ 1088 WIV_Ueberfuell_Warn "Überfüllungswarnung";
CM_ SG_ 1088 WIV_laufender_Motor "Messung bei laufendem Motor nicht möglich";
CM_ SG_ 1088 MO_Text_Motorstart "Anzeigetexte für Start/Stopp und Motor-Start
";
CM_ SG_ 1088 MO_Text_MSG_Werkstatt "Über dieses Bit wird im Kombi ein Fehlerklartextanzeige erzeugt werden: 'Motorsteuergerät Werkstatt'.
(Signal wird im Panamera nicht bedient)
";
CM_ SG_ 1088 MO_Text_Partikelfil_Reg "Über dieses Bit im Kombi wird ein Klartextanzeige erzeugt werden: 'Partikelfilter benötigt Regeneration'.
(Signal wird nur im Panamera Pirol bedient)
";
CM_ SG_ 1088 MO_Text_Fehler_Kraftstoffsys "Über dieses Bit wird im Kombi ein Fehlerklartextanzeige erzeugt wird: 'Fehler im Kraftstoffsystem'.	
(Signal wird im Panamera nicht bedient)";
CM_ SG_ 1088 WIV_Oelmenge "Ölmenge zwischen Min und Max";
CM_ SG_ 1088 MO_Systemlampe "EGas Systemlampe (EPC) oder Vorglühlampe im Kombi, Kombi steuert immer gleiche
LED an, nur über Ziffernblatt wird die EPC von der Vorglühlampe differenziert";
CM_ SG_ 1088 MO_OBD2_Lampe "OBD bzw. MIL-Lampe wird vom Motorsteuergerät angesteuert, die Information in der Getriebe1 Botschaft (Byte 6, Bit 7...4) wird 
vom Motorsteuergerät an das Kombi weitergereicht";
CM_ SG_ 1088 MO_Heissleuchte "Ansteuerung der Kühlwassertemperatur-Heißleuchte (Sensor nur noch am Motorsteuergerät): Temperaturschaltschwellen mit Hysterese (bei VW D1/Colorado Kombi derzeit noch nicht genutzt).";
CM_ SG_ 1088 MO_Partikel_Lampe "Partikelfilter-Lampe wird eingeschaltet
(Signal wird nur im Panamera Pirol bedient)";
CM_ SG_ 1088 WIV_Oelstand_nicht_vorhanden "Kein aktueller Ölstand vorhanden";
CM_ SG_ 1088 WIV_nachfuellanzeige_ein "Steuert das Aufblenden der Nachfüllanzeige im Kombi, nach Klemme 15 ein und geöffneter Motorhaube";
CM_ SG_ 1088 WIV_Ueberfuell_deaktiv "Anzeige 'Check Oil' im Kombiinstrument ohne Aufruf durch Kunden
Signalbezeichnung in NIP 5.0 'WIV_Check_Oil'

";
CM_ SG_ 1088 WIV_Unterfuell_Warn "Unterfüllungswarnung";
CM_ SG_ 1088 MO_Tankdeckel_Lampe "Ansteuerung Tankdeckel-Warnlampe Kombiinstrument (nur Ottomotoren) z.Zt. Vorhalt VW
(Signal wird nur im Panamera Hybrid bedient)";
CM_ SG_ 1088 MO_Text_Tankdeckelwarn "Textbit der Tankdeckelwarnung, z.Zt. Vorhalt VW
(Signal wird nur im Panamera Hybrid bedient)";
CM_ SG_ 1088 WIV_Enable_Oeldr_Motor "Schaltet die interne Öldruckauswertung im Kombiinstrument ab und aktiviert die Auswertung des Bits 'WIV_Oeldr_Warn_Motor'";
CM_ SG_ 1088 WIV_Oeldr_Warn_Motor "Löst im Kombiinstrument die rote Prio1-Öldruckwarnung (inkl. 3xBeep) aus; die Warnauslösung erfolgt nur bei gleichzeitig gesetztem 'WIV_Enable_Oeldr_Motor'";
CM_ SG_ 1088 MO_Avus_Motorschutz "Warntexten zum Kombi für den Fall des Avus-Notlauf. Priowarnung, kann parallel mit anderen Warnungen 
im Mitteldisplay angezeigt werden.";
CM_ SG_ 1088 MO_HYB_Fahrbereitschaft "Signal steuert u.a. in der Lenkhilfe zusammen mit weiteren Informationen den Modewechsel in den 'Drivemode'
Grüne Anzeige im Kombiinstrument zur Signalisierung der Bereitschaft des Hybridsystems.
(Signal wird nur im Panamera Hybrid bedient)";
CM_ SG_ 1088 WIV_Oeldyn_avl "Ölstand aus dynamischer Messung vorhanden
(Signal wird im Panamera nicht bedient)";
CM_ SG_ 1088 MO_HYB_Text_7 "Textanzeige: Traktionsbatterie wird geladen bitte Motor nicht abstellen
(Signal wird nur im Panamera Hybrid bedient)";
CM_ SG_ 1088 MO_HYB_Text_6 "Textanzeige: Elektrisches Fahren zur Zeit nicht möglich
(Signal wird nur im Panamera Hybrid bedient)";
CM_ SG_ 1088 MO_HYB_Text_5 "Textanzeige: Hybrid-Funktionen nicht verfügbar
(Signal wird nur im Panamera Hybrid bedient)";
CM_ SG_ 1088 MO_HYB_Text_3 "Textanzeige: Bitte Motor erneut Starten
(Signal wird nur im Panamera Hybrid bedient)";
CM_ SG_ 1088 MO_HYB_Text_2 "Textanzeige: Fehler Hybridystem
bitte Werkstatt aufsuchen
(Signal wird nur im Panamera Hybrid bedient)";
CM_ SG_ 1088 MO_HYB_Text_1 "Textanzeige: Fehler Hybridsystem
bitte Fahrzeug an sicherem Ort anhalten
(Signal wird nur im Panamera Hybrid bedient)";
CM_ SG_ 1600 MO_Nachlaufzeit_Heizungspumpe "Nachlaufzeit für Heizungspumpe für Turboladerschutz";
CM_ SG_ 1600 MO_Kennfeldk "Die Kennfeldkühlung ist in diesem Fahrzeug verbaut und hat keinen Systemfehler";
CM_ SG_ 1600 MO_QBit_Ansaugluft_Temp "
";
CM_ SG_ 1600 MO_QBit_Kuehlmittel_Temp "
";
CM_ SG_ 1600 MO_Stellgliedtest_Soundaktuator "Ansteuerung des Stellgliedtest
(Signal wird im Panamera nicht bedient)";
CM_ SG_ 1600 MO_HYB_Fehler_HV_Netz "Im HV-Bordnetz ist fehlerbedingt kein generatorischer Betrieb möglich. Das 12V-Bordnetz wird über den DC/DC-Wandler allein aus der Traktionsbatterie gespeist. Um diesen Zustand möglichst lange...
(Signal wird nur im Panamera Hybrid bedient)";
CM_ SG_ 1600 MO_Absperrventil_oeffnen "Signal an Klima-SG das Absperrrventil anzusteuern. Ab D4 auch 0x3 Ventil_schließen.";
CM_ SG_ 1600 MO_Ansaugluft_Temp "In Fahrzeugen ohne Außentemperatur vom Kombi kann aus der Ansauglufttemperatur auf die Außentemperatur geschlossen werden. Beim SDI ist das mit einer gewissen Genauigkeit gegeben. Genutzt wird es vom ASG.";
CM_ SG_ 1600 MO_Oel_Temp "Realer Meßbereich ca. -40..150 Grad";
CM_ SG_ 1600 MO_Kuehlmittel_Temp "Kuehlmitteltemperatur";
CM_ SG_ 1600 MO_Hoeheninfo "Korrekturfaktor Höhe (1 entspricht 1013 mbar)";
CM_ SG_ 1600 MO_Versionsinfo "Versioninformation vom Motor zur Steuerung bei inkompatiblen KMatrix-Änderung bzw. Einführung von neuen Funktionen, die in den Empfängern verriegelt werden müssen. Freilaufender Zähler, der nach Änderungsereignis festgelegt wird. Zu jedem Ereignis wird ei";
CM_ SG_ 1600 MO_Getriebe_kuehlen "Anforderung Getriebekühlventilansteuerung";
CM_ SG_ 1600 MO_Mom_Traegheit_02 "Massenträgheit des Motors (J) in kgm²
Bei Handschaltern wird das Zweimassenschwungrad mit berücksichtigt.
Bei eingebautem Getriebesteuergerät wird nur das Motorträgheitsmoment angegeben (Ohne Anteile des Massenschwungrades).";
CM_ SG_ 1600 MO_Heizungspumpenansteuerung "Anforderung Heizungspumpenansteuerung ";
CM_ SG_ 1600 MO_SpannungsAnf "Forderung des Motor-SGs zur Spannungsanhebung";
CM_ SG_ 1600 MO_aktives_Getriebeheizen "Information für Getriebe, ob ein Ventil für Getriebheizen angesteuert werden muss";
CM_ SG_ 1601 MO_Kraftstoffart "Kraftstoffart";
CM_ SG_ 1601 Motor_Code_01_CHK "Berechnung siehe Lastenheft 'Kommunikationsabsicherung für FlexRay und CAN'
Endwerte siehe 'Kommunikationsabsicherung für FlexRay und CAN / Anhang C: Tabelle S-PDU Kennungen'


";
CM_ SG_ 1601 MO_Faktor_Momente "Dieses Bit schaltet den Wertebereich aller Momente vom Motor, Getriebe, TSK, ESP ... um! Die Momente besitzen somit einen variablen Wertebereich, weil sich durch den Faktor die Momente sowohl in Auflösung als auch Maximalwerten ändert.

Defaultwert ist ";
CM_ SG_ 1601 MO_Hybridfahrzeug "Anhand dieses Signals plausibilisiert die Lenkhilfe das Bit Fahrbereitschaft
(Signal wird nur im Panamera Hybrid bedient)";
CM_ SG_ 1601 MO_Code "Motorcodierinformation für Getriebe. Überwachung auf Falschverbau.






";
CM_ SG_ 1601 MO_Getriebe_Code "Getriebecodierung des Motors 

0x0 - 0x1 = tbd. 
0x3 = tbd. 
0x5 - 0x9 = tbd. 
0xB - 0xE = tbd.
0x10 - 3F =tbd.";
CM_ SG_ 1601 MO_Abgastyp "Bit 0:

0x0 = kein EOBD
0x1 = EOBD

Bit 1:

0x0 = kein OBD (US-Norm)
0x1 = OBD (US-Norm)

0x4 -0x3f=tdb. 
";
CM_ SG_ 1601 MO_StartStopp_Codiert "Funktion 'StartStopp' im aktuellen Klemmenzyklus verbaut
(entspricht Status LV_VAR_STST)";
CM_ BO_ 157 "Motor - Getriebe - Schnittstelle auf CAN-Antrieb (PL72H)";
CM_ SG_ 157 MO_HYB_EMode_Info "Hybrid-Mode der Motorsteuerung zur Beeinflussung der Schaltkennfelder im Getriebe. Nicht-Hybridfahrzeuge senden den Initwert.
Signal wird nur von Porsche genutzt.";
CM_ SG_ 157 Motor_Hybrid_01_CHK "Berechnung siehe Lastenheft 'Kommunikationsabsicherung für FlexRay und CAN'
Endwerte siehe 'Kommunikationsabsicherung für FlexRay und CAN / Anhang C: Tabelle S-PDU Kennungen'


";
CM_ SG_ 157 Motor_Hybrid_01_BZ "überlaufender 4bit Botschaftszaehler; wird in jeder Sendebotschaft inkrementiert";
CM_ SG_ 157 MO_HYB_IstStatusK0 "Status 'offen' muss eine voll geöffnete Kupplung sicherstellen.";
CM_ SG_ 157 MO_HYB_max_ind_VM_Mom "inneres maximal mögliches VM-Moment bei einer Drehzahl (z.B. Rauchbegrenzung oder Fehlerfall).";
CM_ SG_ 157 MO_HYB_Startmodus "Hybridsteuerung zeigt an, auf welche Weise gestartet werden soll.";
CM_ SG_ 157 MO_HYB_Startmodus_PQ3x "Hybridsteuerung (MSG) zeigt an, auf welche Weise gestartet werden soll. (Nur PQ3x Hybrid)";
CM_ SG_ 157 MO_HYB_Stoppmodus "Hybridsteuerung zeigt an, auf welche Weise gestoppt werden soll.";
CM_ SG_ 157 MO_HYB_VM_Mom_oE "Verbrenner-Fahrmoment abzüglich Verbrenner-Verlustmoment. Vorzeichenbehaftet. Für Benutzung in Getriebe-Schaltstrategie";
CM_ SG_ 157 MO_HYB_VM_aktiv "0 = VMotor wird nicht aktiv gehalten (nVM < n_min und keine LL-Regelung aktiv)
1 = VMotor aktiv (ab der ersten Einspritzung; gilt auch für Schubbetrieb, wenn VMotor spätestens durch LLRegelung befeuert würde)
Verwendet zur Bestimmung des Ist-Zustandes";
CM_ SG_ 157 MO_HYB_Schaltverhinderung "Schaltungen werden an den DZ-Grenzen (Nullgas-Schaltdrehzahl und Kickdown-Schaltdrehzahl) ausgeführt.";
CM_ SG_ 157 MO_HYB_Selektor_Momverlauf_EM "Selektor welche Größe des Momentenverlauf aktuell übertragen wird
000b = 0 :  keine Werte(GRA/ACC nicht aktiv)
001b = 1 : max. umsetzbares langfristiges Rekup.-Moment
010b = 2 : Knickdrehzahl d. langfr. Rekup-Kurve
011b = 3 : max. verfügbares langfr. ";
CM_ SG_ 157 MO_HYB_Momverlauf_Rek "Momentenverlaufs-information bei aktiver GRA/ACC
max. umsetzbares langfristiges Rekup.-Moment";
CM_ SG_ 157 MO_HYB_KnickDZ_Rek "Momentenverlaufs-information bei aktiver GRA/ACC
Knickdrehzahl d. langfr. Rekup-Kurve";
CM_ SG_ 157 MO_HYB_Momverlauf_EM "Momentenverlaufs-information bei aktiver GRA/ACC
max. umsetzbares langfristiges Rekup.-Moment";
CM_ SG_ 157 MO_HYB_KnickDZ_EM "Momentenverlaufs-information bei aktiver GRA/ACC
Knickdrehzahl d. langfr. pos. EM-Kurve";
CM_ BO_ 811 "Motor - Getriebe - Schnittstelle auf CAN-Antrieb (PL72H)";
CM_ SG_ 811 MO_FahrPr7_verfuegbar "Verfügbarkeitsanzeige des Fahrprogramm 7";
CM_ SG_ 811 MO_FahrPr6_verfuegbar "Verfügbarkeitsanzeige des Fahrprogramm 6";
CM_ SG_ 811 MO_FahrPr5_verfuegbar "Verfügbarkeitsanzeige des Fahrprogramm 5";
CM_ SG_ 811 MO_FahrPr4_verfuegbar "Verfügbarkeitsanzeige des Fahrprogramm 4";
CM_ SG_ 811 MO_FahrPr3_verfuegbar "Verfügbarkeitsanzeige des Fahrprogramm 3";
CM_ SG_ 811 MO_FahrPr2_verfuegbar "Verfügbarkeitsanzeige des Fahrprogramm 2";
CM_ SG_ 811 MO_FahrPr1_verfuegbar "Verfügbarkeitsanzeige des Fahrprogramm 1";
CM_ SG_ 811 MO_HYB_E_Faktor "Signed Nibble, verwendet vom GSG zur Interpolation zwischen VMKennfeld und dem Rekuperations-Grenzkennfeld (negative Werte des E-Faktors) bzw. dem Boost-Grenzkennfeld (positive Werte des E-Faktors).
0000 = VM-Kennfeld (keine Interpolation)
0001..0111 = ";
CM_ SG_ 811 MO_HYB_Drehzahl_VM "für OBD freeze frame";
CM_ SG_ 811 MO_HYB_LowSpeedModus "MSG legt fest:
0 = klassisches Ausrollen/Anfahren mit N_mot >= N_Leerlauf_VM
1 = elektr. Ausrollen/Anfahren mit geschl. Triebstrang mit N_mot < N_Leerlauf_VM";
CM_ SG_ 933 MO_Overboost "Nur Turbo. Anzeige eines Overboostpfeils im Kombi während Overboostzustand der Ladedruckregelung.";
CM_ SG_ 933 Enrgfluss_State "Energiefluss zwischen den Achsen, Batterie, Elektromotor und Verbrennungsmotor";
CM_ SG_ 933 Ladezustand "Ladezustand der Batterie
";
CM_ SG_ 933 Energiefluss "Die %-Werte ergeben sich aus dem momentanen Moment der E-Maschine bezogen auf das im aktuellen Arbeitspunkt maximal mögliche Moment der E-Maschine (generatorisch = negativ / motorisch = positiv )
(Signal wird nur im Panamera Hybrid bedient)";
CM_ SG_ 933 Enrgrueckfluss "Frei laufender Zähler für die rückgewonnene Energie
(Signal wird nur im Panamera Hybrid bedient)";
CM_ SG_ 933 MO_Temp_MotRaum "Der Motor sendet dem BCM2 die Temperatur im Motorraum in °C.
(Signal wird nicht im Panamera bedient)";
CM_ SG_ 933 MO_Oel_Temp_Radsatz "Öltemperatur in PDK Radsatz
(Signal wird im Panamera nicht bedient)";
CM_ SG_ 933 MO_Anf_Abgasklappe "Motorsteuergeraet sendet Anforderung zur Aktivierung der Abgasklappe";
CM_ SG_ 933 MO_LED_Abgasklappe "Status der Abgasklappe
Signal zur Ansteuerung der Funktionsleuchte im Abgasklappentaster in der BKE";
CM_ SG_ 933 MO_Hoch_Anz_Nmax "Hochschaltempfehlung der Motorsteuerung vor Erreichen der Abstellerdrehzahl, gangabhängig. Hochschaltpfeil im Kombi, oder Schaltblitz, auch mit Automat.
Keine Befüllung des Signals im G1";
CM_ SG_ 933 MO_Hoch_Anz_Eco "Hochschaltempfehlung der Motorsteuerung für günstigen Kraftstoffverbrauch. Hochschaltpfeil im Kombi. Auch mit Automat.
Keine Befüllung des Signals im G1";
CM_ SG_ 933 MO_Fehler_MSpG "Wenn das Motorraumspülgebläse defekt ist, oder die Motorraumtemperatur zu hoch sendet die DME Info ans Kombiinstrument. Dieses gibt Textmeldung aus. Und blinkende Heissleuchte.
(Signal wird im Panamera nicht bedient)";
CM_ BO_ 1730 "200ms ab D4";
CM_ SG_ 1730 NMH_GE_N_Haltephase "Falls Wefgahrsperre Nachlauf vor CAN-Wakeup aktiv (Nur AL-Getriebe)";
CM_ SG_ 1730 NMH_GE_Start_1 "Zustand Start (<--Sleep)";
CM_ SG_ 1730 NMH_GE_Start_2 "Zustand Start (<--Prepare to Sleep)";
CM_ SG_ 1730 NMH_GE_Normal_Mode_1 "Zustand Normal Mode (<-- Start)";
CM_ SG_ 1730 NMH_GE_Normal_Mode_2 "Zustand Normal Mode (<-- Ready to Sleep)";
CM_ SG_ 1730 NMH_GE_Car_WakeUp "Car WakeUp (optional), wird vom Getriebe nicht gesendet";
CM_ SG_ 1730 NMH_GE_Per_WakeUp "Weckurasche Peripherie
";
CM_ SG_ 1730 NMH_GE_Fkt_WakeUp "Weckursache Funktion

";
CM_ SG_ 1730 NMH_GE_NM_aktiv_Klemme_15 "Klemme 15 ein (NM-Nachlaufursache, nicht 'Ready To Sleep')
";
CM_ SG_ 1730 NMH_GE_NM_aktiv_Diagnose "Diagnose bei Kl 15 aus (Nachlaufursache, nicht 'Ready To Sleep')";
CM_ SG_ 1730 NMH_GE_NM_aktiv_Start "Mindestaktivzeit Zustand 'Start' (Nachlaufursache, nicht 'Ready To Sleep')";
CM_ SG_ 1730 NMH_GE_kein_NL "kein lokaler / SG interner Nachlauf vor Wakeup";
CM_ SG_ 1730 NMH_GE_NL_Daten_EEPROM "EEPROM Datenspeicherung (lokaler / SG interner Nachlauf vor Wakeup)";
CM_ SG_ 1730 NMH_GE_NL_Drucksens "lokaler / SG interner Nachlauf: Wird gesetzt falls Druck auf einer der beiden Drucksensoren über applizierbarer Schwelle (bedeutet Motor läuft) vor CAN-Wakeup - nur VL Getriebe";
CM_ SG_ 1730 NMH_GE_NL_Abtrieb "lokaler / SG interner Nachlauf: Wird gesetzt falls Abtriebsdrehzahl größer applizierbarer Schwelle (bedeutet Fahrzeug bewegt sich) vor CAN-Wakeup - nicht DL Getriebe";
CM_ SG_ 1730 NMH_GE_NL_Waehlhebel "lokaler / SG interner Nachlauf: Wird gesetzt falls Wählhebel nicht in P oder N vor CAN-Wakeup - nur AL Getriebe";
CM_ SG_ 1730 NMH_GE_NL_Wegfahrsperre "lokaler / SG interner Nachlauf: Wird gesetzt falls Wegfahrsperre Nachlauf vor CAN-Wakeup aktiv - nur AL Getriebe";
CM_ SG_ 1730 NM_GE_Signalfehler "Bei der Speicherung eines CAN-Signalfehlers muss dieser mindestens einmal in der NM-Botschaft angezeigt werden.";
CM_ SG_ 1730 NMH_GE_TimeOut_Fehler "Aktiver Timeout Fehlerspeichereintrag  ";
CM_ SG_ 1730 NMH_GE_CAN_Diag_deaktiv "CAN Bus bezogene Eigendiagnose deaktiviert (Überspannung, Unterspannung, Hochlaufphase, ...) ";
CM_ SG_ 1730 NMH_GE_KompSchutz "Funktionseinschränung aufgrund Komponentenschutz aktiv";
CM_ SG_ 1730 NMH_GE_Mute_Mode "Funktionseinschränung aufgrund Mute Mode aktiv, nur VW";
CM_ SG_ 1730 NMH_GE_Transport_Mode "Funktionseinschränung aufgrund Transport Mode aktiv";
CM_ SG_ 1730 NMH_GE_Abschaltstufe_aktiv "Funktionsabschaltung wegen Abschaltschaltstufe";
CM_ SG_ 1730 NMH_GE_Eindraht_Fehler "Erkennung Eindrahtfehler";
CM_ SG_ 1730 NMH_GE_Lokalaktiv "Zeigt an ob das SG nach Klemme15 AUS und nach entsprechender MAX Aktivzeit noch aktiv war";
CM_ SG_ 1730 NMH_GE_Subsystemaktiv "Zeigt an ob ein Subsystem des SGs nach Klemme15 AUS und nach entsprechender MAX Aktivzeit noch aktiv war";
CM_ SG_ 1730 NMH_GSG_Subbusaktiv "Zeigt an ob der Subbus aktiv oder inaktiv ist";
CM_ BO_ 1729 "200ms ab D4";
CM_ SG_ 1729 NMH_MO_Start_1 "Zustand Start (<--Sleep)";
CM_ SG_ 1729 NMH_MO_Start_2 "Zustand Start (<--Prepare to Sleep)";
CM_ SG_ 1729 NMH_MO_Normal_Mode_1 "Zustand Normal Mode (<-- Start)";
CM_ SG_ 1729 NMH_MO_NM_aktiv_HV_Abschaltung "Hybrid-Manager deaktiviert alle Hochvolt-Verbraucher für stromloses Öffnen der Batterieschütze
(Nachlaufursache, nicht 'Ready To Sleep')";
CM_ SG_ 1729 NMH_MO_Normal_Mode_2 "Zustand Normal Mode (<-- Ready to Sleep)";
CM_ SG_ 1729 NMH_MO_Car_WakeUp "Car WakeUp (optional), wird vom Motor nicht gesendet";
CM_ SG_ 1729 NMH_MO_Per_WakeUp "Weckursache Peripherie
";
CM_ SG_ 1729 NMH_MO_Fkt_WakeUp "Weckursache Funktion
";
CM_ SG_ 1729 NMH_MO_NM_aktiv_Klemme_15 "Klemme 15 ein (NM-Nachlaufursache, nicht 'Ready To Sleep')";
CM_ SG_ 1729 NMH_MO_NM_aktiv_Diagnose "Diagnose bei Kl 15 aus (NM-Nachlaufursache, nicht 'Ready To Sleep')
";
CM_ SG_ 1729 NMH_MO_NM_aktiv_Start "Mindestaktivzeit Zustand 'Start' (NM-Nachlaufursache, nicht 'Ready To Sleep')";
CM_ SG_ 1729 NMH_MO_NM_aktiv_EKP_Vorlauf "EKP-Vorlauf (z. Zt. nicht bei Diesel)
(NM-Nachlaufursache, nicht 'Ready To Sleep')
";
CM_ SG_ 1729 NMH_MO_NM_aktiv_STH_Betrieb "STH-Betrieb (NM-Nachlaufursache, nicht 'Ready To Sleep')
";
CM_ SG_ 1729 NMH_MO_kein_NL "kein lokaler / SG interner Nachlauf vor Wakeup";
CM_ SG_ 1729 NMH_MO_NL_Kuehlerluefter "Kühlerlüfter Steuerung / Zusatzwasserpumpe (lokaler / SG interner Nachlauf vor Wakeup)";
CM_ SG_ 1729 NMH_MO_NL_Diagnose "Diagnosefunktionen (lokaler / SG interner Nachlauf vor Wakeup)";
CM_ SG_ 1729 NMH_MO_NL_WFS "Wegfahrsperre (lokaler / SG interner Nachlauf vor Wakeup)";
CM_ SG_ 1729 NMH_MO_NL_EEPROM "EEPROM Zugriffe RAM/ROM Tests (lokaler / SG interner Nachlauf vor Wakeup)";
CM_ SG_ 1729 NMH_MO_NL_Sonstige "Sonstige lokale / SG interne Nachläufe vor Wakeup";
CM_ SG_ 1729 NM_MO_Signalfehler "Bei der Speicherung eines CAN-Signalfehlers muss dieser mindestens einmal in der NM-Botschaft angezeigt werden.";
CM_ SG_ 1729 NMH_MO_TimeOut_Fehler "Aktiver Timeout Fehlerspeichereintrag  ";
CM_ SG_ 1729 NMH_MO_CAN_Diag_deaktiv "CAN Bus bezogene Eigendiagnose deaktiviert (Überspannung, Unterspannung, Hochlaufphase, ...) ";
CM_ SG_ 1729 NMH_MO_KompSchutz "Funktionseinschränung aufgrund Komponentenschutz aktiv";
CM_ SG_ 1729 NMH_MO_Mute_Mode "Funktionseinschränung aufgrund Mute Mode aktiv, nur VW";
CM_ SG_ 1729 NMH_MO_Transport_Mode "1 = Funktionseinschränung aufgrund Transport Mode aktiv";
CM_ SG_ 1729 NMH_MO_Abschaltstufe_aktiv "Funktionsabschaltung wegen Abschaltschaltstufe";
CM_ SG_ 1729 NMH_MO_Eindraht_Fehler "Erkennung Eindrahtfehler";
CM_ SG_ 1729 NMH_MO_Lokalaktiv "Zeigt an ob das SG nach Klemme15 AUS und nach entsprechender MAX Aktivzeit noch aktiv war";
CM_ SG_ 1729 NMH_MO_Subsystemaktiv "Zeigt an ob ein Subsystem des SGs nach Klemme15 AUS und nach entsprechender MAX Aktivzeit noch aktiv war";
CM_ SG_ 913 OBD_Calc_Load_Val "Calculated Load Value

Übertragung von Meßgrößen an das Getriebesteuergerät für Freeze Frame Abspeicherung bei Getriebefehlern

PID $04 Calculated Load Value; 0 .. 100% mit 100/255 % per bit
";
CM_ SG_ 913 OBD_Eng_Cool_Temp "Engine Coolant Temperature

Übertragung von Meßgrößen an das Getriebesteuergerät für Freeze Frame Abspeicherung bei Getriebefehlern

PID $05 Engine Coolant Temperature; -40 .. +215°C mit 1°C/bit und 40°C Offset";
CM_ SG_ 913 OBD_Abs_Throttle_Pos "Absolute Throttle Position

Übertragung von Meßgrößen an das Getriebesteuergerät für Freeze Frame Abspeicherung bei Getriebefehlern

PID $11 Absolute Throttle Position; 0 .. 100% mit 100/255 %/bit";
CM_ SG_ 913 OBD_Abs_Load_Val "Absolute Load Value

Übertragung von Meßgrößen an das Getriebesteuergerät für Freeze Frame Abspeicherung bei Getriebefehlern

PID $43 Absolute Load Value; 0 .. 25700%  mit 100/255 %/bit";
CM_ SG_ 913 OBD_Abs_Pedal_Pos "Absolute Pedal Position

Übertragung von Meßgrößen an das Getriebesteuergerät für Freeze Frame Abspeicherung bei Getriebefehlern

PID $49 Accelerator Pedal Position D; 0 .. 100% mit 100/255 %/bit";
CM_ SG_ 913 OBD_Warm_Up_Cycle "Mit dem Warm-Up-Cycle wird der zentrale Verlernzähler vom Gateway inkrementiert";
CM_ SG_ 913 OBD_Normed_Trip "Gesetzlich definierte 'Normed Condition' erfüllt, 'General Denominator' darf erhöht werden";
CM_ SG_ 913 OBD_Sperrung_IUMPR "Wenn der General Denominator auf Grund eines Fehlers in den Eingangsgrößen gesperrt wird, wird diese Information über Bussystem als OBD-Statusinformation OBD_Sperrung_IUMPR für andere OBD-Steuergeräte bereitgestellt. 

Das MSG (MIL-Master) setzt dieses ";
CM_ SG_ 913 OBD_Kaltstart_Denominator "Bestimmte Diagnosen werden nur unter Kaltstartbedingungen durchgeführt, der entsprechende Denominator bei IUMPR-pflichtigen Systemen wird anhand dieses vom MSG gebildeten Signals inkr...
(Signal wird nur im Panamera Hybrid bedient)";
CM_ SG_ 913 OBD_Minimum_Trip "Grundlage OBD-Gesetz CCR 1968.2 (d)(4.3) Denominator Specifications
Bildung des General Denominator 'Normed Trip':
¿ 600 sec. (kumulativ) Zeit nach Motorstart
¿ 300 sec. (kumulativ) mit Fahrzeuggeschwindigkeit > 25 mph (40 km/h)
¿ 30 sec. (kontinuierl";
CM_ SG_ 270 TSK_04_CHK "Berechnung siehe Lastenheft 'Kommunikationsabsicherung für FlexRay und CAN'
Endwerte siehe 'Kommunikationsabsicherung für FlexRay und CAN / Anhang C: Tabelle S-PDU Kennungen'";
CM_ SG_ 270 TSK_zul_Regelabw "Anforderung der zulässigen Regelabweichung vom Triebstrangkoordinator. Zulässiger Betrag der Abweichung zwischen angeforderter 'TSK_Sollbeschleunigung_Getriebe' und umzusetzender Sollbeschleunigung  im Getriebe. Im TSK wird, abhängig vom Arbeitspunkt die ";
CM_ SG_ 270 TSK_ax_Getriebe "Beschleunigungsanforderung des Beschleunigungsreglers (u. a. für ACC, GRA, Speed Limiter). Das Signal wird vom Getriebe benutzt, um die von GRA/ACC geforderte Sollbeschleunigung in dem verbrauchsgünstigsten Gang einzustellen.";
CM_ SG_ 270 TSK_Wunsch_Uebersetz "Bei ACC/GRA Betrieb bergab teilt der TSK dem Getriebe mit, dass eine Drehzahlerhöhung erwünscht ist, um mehr Schleppmoment und damit verbunden die nötige Verzögerung zu erzeugen, um die Geschwindigkeit konstant zu halten. 

Nutzung im VL: das Getriebe v";
CM_ SG_ 270 TSK_Freig_WU "Freigabe des TSK_Übersetzungswunsches bei ACC/GRA Betrieb bergab für die Verstellung nach kurz bzw. Rückschaltung im Getriebe.";
CM_ SG_ 270 TSK_Limiter_aktiv "Information, ob der Höchstgeschwindigkeitsbegrenzer aktiv ist. Beim gesetzten Bit kann das Getriebe hochschalten, unabhängig vom Fahrpedal";
CM_ SG_ 270 TSK_Status_GRA_ACC_02 "Signal redundant zu 'TSK_Status_GRA_ACC_01' in TSK_02, um für das Getriebe die einzulesenden Botschaften zu definieren.  

Die Zustände 0x1 und 0x2 werden vom Motor auch bei ACC gesetzt, wegen Umsetzung des Triebsstrangkoordinators im Motor. ";
CM_ SG_ 273 TSK_Fahrzeugmasse_02 "Neue Definition ab D4
Fahrzeugmasse in kg. Das Signal dient der Anpassung der Sollbeschleunigung vom ACC";
CM_ SG_ 273 TSK_05_CHK "Berechnung siehe Lastenheft 'Kommunikationsabsicherung für FlexRay und CAN'
Endwerte siehe 'Kommunikationsabsicherung für FlexRay und CAN / Anhang C: Tabelle S-PDU Kennungen'";
CM_ SG_ 273 TSK_Status_GRA_ACC_01 "Die Zustände 0x1 und 0x2 werden vom Motor auch bei ACC gesetzt, wegen Umsetzung des Triebsstrangkoordinators im Motor. ";
CM_ SG_ 273 TSK_Fahrzeugmasse "Fahrzeugmasse in kg. Das Signal dient der Anpassung der Sollbeschleunigung vom ACC
Init (entspricht phys. 500kg)
(Signal wird im Panamera nicht bedient)
";
CM_ SG_ 273 TSK_Steigung "Steigung in % Berg. Das Signal dient der Anpassung der Sollbeschleunigung vom ACC

Positive Werte > bergauf; 
Negative Werte < bergab

Fehler: Die Steigung aufgrund eines Fehlers (mit KD-Fehlereintrag) nicht mehr berechnet werden";
CM_ SG_ 273 TSK_Codierung_ACC "Information über den plausibilisierten Codierungszustand des Triebstrangskoordinators auf ACC.
Nutzung im ESP: Aktivierung der Timeout Überwachung auf ACC_01-Botschaft und Überwachung der zusätzlichen Drucksensoren bei gesetztem Bit.";
CM_ SG_ 273 TSK_Zwangszusch_ESP "Mit diesem Bit wird das ESP/ASR zwangsweise aktiviert. Bei gesetztem Bit ist ein ausgetastetes ESP (oder ASR) wieder aktiviert bzw. wird die Austastung verhindert.";
CM_ SG_ 273 TSK_Freig_Verzoeg_Anf "Freigabe der Verzögerungsanforderung der ACC oder ggf. GRA+ Funktion für ECD Regelung im ESP";
CM_ SG_ 273 TSK_Verzoeg_Anf_02 "Verzögerungsanforderung der ACC oder ggf. GRA+ Funktion für ECD Regelung im ESP";
CM_ SG_ 915 WBA_GE_Zusatzwarnungen "Prioritaetswarnungen Getriebe an Kombi
aktuell nur im Audi MLB genutzt";
CM_ SG_ 915 WBA_Effizienzmodus "Bei Handschaltern wird  das Fahrprogramm Effizienz signalisiert. 
Bei Automatikgetrieben wird das Fahrprogramm 'D' durch 'E' ersetzt.";
CM_ SG_ 915 WBA_Istgang "Wenn Motor die WBA-Botschaft sendet wird in diesem Signal der aktuelle Gang ausgegeben (= Istgang des Schaltgetriebes). Nur falls WBA_Senderkennung = 01 (MSG).
(Signal wird im Panamera nicht bedient)";
CM_ SG_ 915 WBA_GE_Texte "Fahrerhinweise für das Kombi";
CM_ SG_ 915 WBA_Schaltschema_Aktiv "Anforderung Getriebe zur Anzeige des Schaltschemas im Kombi";
CM_ SG_ 915 WH_Warnung "Warntexte vom Waehlhebel";
CM_ SG_ 915 WBA_Sollgang "Motor sendet den Sollgang in den der Fahrer schalten soll. Wird im Kombi als Hochschaltempfehlung hervorgehoben. Nur falls WBA_Senderkennung = 01 (MSG)
(Signal wird im Panamera nicht bedient)";
CM_ SG_ 915 WBA_Senderkennung "Die Botschaft WBA_02 wird vom Automatgetriebe gesendet, bei Handschaltern alternativ vom Motor. Das Getriebe stellt damit die Wählbereichsanzeige dar, der Motor beim Handschalter die Hochschaltaufforderung für den Fahrer im Kombi. Zur Unterscheidung des S";
CM_ SG_ 915 WBA_Lampe_Shift_Lock "Im Kombi wird Anzeige im Mitteldisplay geschaltet: 'Zum Einlegen einer Fahrstufe bitte Bremse betätigen' - nur falls WBA_Senderkennung = 00 (GSG)

";
CM_ SG_ 915 WBA_Blinken "Dieses Bit steuert die Fehlerlampe an oder wird zum Blinken der WBA-Anzeige genutzt - nur falls WBA_Senderkennung = 00 (GSG)
";
CM_ SG_ 915 WBA_Getriebevariante "Verwendete Getriebe-Variante im Fahrzeug, Kombi stellt entsprechende WBA dar (bspw. PRNDS). Nur falls WBA_Senderkennung = 00 (GSG).
";
CM_ SG_ 915 WBA_GE_Warnung "Prioritaetswarnungen Getriebe mit Shift by wire";
CM_ SG_ 915 WBA_Fahrstufe "Bei Automatgetrieben wird in diesem Signal die aktuelle Fahrstufe (=Wählhebelposition) ausgegeben. Nur falls WBA_Senderkennung = 00 (GSG):

Im Automatik-Betrieb:

0x0 = Zwischenstellung, keine Position  (Normaldarstellung aller Fahrstufen)
0x1 = Getr";
CM_ SG_ 915 WBA_Schaltempf_verfbar "Info, ob Schaltempfehlung im Fzg. verfügbar. Statischer Wert, ändert sich für ein Fzg nicht - nur falls WBA_Senderkennung = 01 (MSG)
(Signal wird im Panamera nicht bedient)";
CM_ SG_ 915 WBA_eing_Gang "Das Automatgetriebe gibt den aktuell eingelegten Gang aus. Nur falls WBA_Senderkennung = 00 (GSG)

0xB - 0xF = tbd.";
CM_ SG_ 915 WBA_02_CHK "Berechnung siehe Lastenheft 'Kommunikationsabsicherung für FlexRay und CAN'
Endwerte siehe 'Kommunikationsabsicherung für FlexRay und CAN / Anhang C: Tabelle S-PDU Kennungen'";
CM_ SG_ 1602 WIV_Verschleissindex "Bei Otto Verbrauch, bei Diesel Verschleiss";
CM_ SG_ 1602 WIV_Russindex "Nur für Diesel, Rußwert, bei Otto Wert = 0";
CM_ SG_ 1602 WIV_t_min "Minimales Wartungsintervall für WIV in Monaten";
CM_ SG_ 1602 WIV_t_max "Maximales Wartungsintervall für WIV in Monaten";
CM_ SG_ 1602 WIV_W_min "Minimales Wartungsintervall für WIV in km";
CM_ SG_ 1602 WIV_W_max "Maximales Wartungsintervall für WIV in km";
CM_ BO_ 1646 "Botschaft analog Konzernmatrix Audi/VW";
CM_ SG_ 1646 KL_STL_aktiv "Betriebsstatus Standlueftung";
CM_ SG_ 1646 KL_STH_Betriebsdauer "Signal aus B8: im D3 derzeit nur 15, 30, 45, 60 Min
";
CM_ SG_ 1646 KL_STH_Ansteuerung "Ansteuerung Standheizung";
CM_ SG_ 1646 KL_STH_aktiv "Standheizung aktiv";
CM_ SG_ 1646 KL_Sonnenintensitaet "Sonnenintensitaet Klimaanlage";
CM_ SG_ 1646 KL_Magnetventil "Wasserventil zum Waermetauscher geoeffnet/geschlossen";
CM_ SG_ 1646 KL_Innen_Temp "Innentemperatur
";
CM_ SG_ 1646 KL_AussenTemp_WK "Aussentemperatur";
CM_ SG_ 1646 KL_MSG_valid "Signal zeigt an, ob alle Daten in der Botschaft gültig und plausibilisiert sind";
CM_ SG_ 1646 KL_Solarluefter_aktiv "Betriebsstatus Solarluefter";
CM_ BO_ 1636 "Botschaft analog Konzernmatrix Audi/VW";
CM_ SG_ 1636 KL_I_Geblaese "Stromaufnahme Gebläse";
CM_ SG_ 1636 KL_Beschlagsgefahr "Beschlagsgefahr auf der Frontscheibe im Bereich des Spiegelfusses. Dient zur präventiven Ansteuerung der  Kamera-Scheibenheizung, um Kamera-Blindheit zu vermeiden
PHEV: volle Leistungsfreigabe HV Heizer und HV EKK bei Scheibenbeschlag ";
CM_ SG_ 1636 KL_Umluftklappe_Status "Status Umluftklappe

";
CM_ SG_ 1636 KL_HSH_Taktung "Status Heckscheibenheizung
alter Signalname in Matrix 3.0 vor Angleichung an Konzernmatrix VW/Audi:
KL_St_HsHzg";
CM_ SG_ 1636 KL_Zuheizer_Freigabe "Freigabe Zuheizer";
CM_ SG_ 1636 KL_Geblaese_Status "Status Geblaese
Hinweis: Zur Matrix 5 gibt es eine abgestimmte Änderung der Wertetabelle (von Stufen nach prozentual) sowie der Signallänge (3 Bit --> 4 Bit)";
CM_ BO_ 959 "Botschaft analog Konzernmatrix Audi/VW";
CM_ SG_ 959 KL_Comp_rev_rq "Requested compressor revolution
over 8600 rpm = compressor stop";
CM_ SG_ 959 KL_Comp_enable "Enable to start for compressor
After 1 second when High-voltage becomes available, turn on '1'";
CM_ SG_ 959 KL_Vorwarn_Komp_ein "Vorwarnung Kompressor ein; 140ms vorher; Information für Motor zum Aufbau Momentenreserve";
CM_ SG_ 959 KL_Zustand "Betrieb Klimaanlage
";
CM_ SG_ 959 KL_4_Zonen "Vorhalt für D4: Information, ob 4-Zonen-Klimaanlage verbaut
Gilt nicht für PAG Panamera. Wird konstant mit '0' gesendet.

";
CM_ SG_ 959 KL_Thermomanagement "Stufen des Thermomanagements";
CM_ SG_ 959 KL_Vorwarn_HHS_ein "Vorwarnung Heckscheibenheizung ein; Information für Motor zum Aufbau Momentenreserve";
CM_ SG_ 959 KL_Vorwarn_HFS_ein "Vorwarnung Frontscheibenheizung ein (Info für Motor zum Aufbau Momentenreserve), aktuell keine HFS für B8 geplant
";
CM_ SG_ 959 KL_StartStopp_Info "Start/Stop-Info, Veto";
CM_ SG_ 959 KL_KD_Fehler "Status Kundendienstfehlerspeichereinträge";
CM_ SG_ 959 KL_Handshake_BEM "Handshake Klima / BEM (Heizleistungsänderung)";
CM_ SG_ 959 KL_Drehz_Anh "Anhebung der Leerlaufdrehzahl
alter Signalname in Matrix 3.0 vor Angleichung an Konzernmatrix VW/Audi:
KL_N_Anheb
";
CM_ SG_ 959 KL_Anf_KL "Ansteuerung Kuehlerluefter";
CM_ SG_ 959 KL_Last_Kompr "Kompressorlast
alter Signalname in Matrix 3.0 vor Angleichung an Konzernmatrix VW/Audi:
KL_Komp_Last";
CM_ BO_ 2041 "Diagnosebotschaft Response zwischen Airbag SG und Entsorgungsgerät (Tool).";
CM_ SG_ 2041 Response_Airbag_Deployment "Response_Airbag_Deployment";
CM_ BO_ 2033 "Diagnosebotschaft Request zwischen Entsorgungsgerät (Tool) und Airbag SG.";
CM_ SG_ 2033 Request_Airbag_Deployment "Request_Airbag_Deployment";
BA_DEF_ SG_  "DERIVATE_Pruefung" ENUM  "offen","geprüft";
BA_DEF_ SG_  "HYB_Rx_Baureihe" ENUM  "G1+Derivate","nur G1","nur Derivate";
BA_DEF_ SG_  "HYB_Rx_Verwendung" ENUM  "DERIV_Rout","DERIV_Calc","DERIV_Rout+DERIV_Calc";
BA_DEF_ SG_  "GenSigSwitchedByIgnition" ENUM  "No","Yes";
BA_DEF_ SG_  "GenSigEnvVarType" ENUM  "int","float","undef";
BA_DEF_ SG_  "GenSigAutoGenSnd" ENUM  "No","Yes";
BA_DEF_ SG_  "GenSigAutoGenDsp" ENUM  "No","Yes";
BA_DEF_ SG_  "GenSigActiveRepetitions" INT -2147483648 2147483647;
BA_DEF_ SG_  "GenSigFuncType" ENUM  "NoFunction","MsgCounter","CRC-8","XOR","XOR-2","DatedBit","SW-Kl15","CHK","Constant","Protocol";
BA_DEF_ SG_  "Info_BCM_HutHut_Kommunikation" ENUM  "Nein","Ja";
BA_DEF_ SG_  "NWM-WakeupAllowed" ENUM  "No","Yes";
BA_DEF_ SG_  "GenSigInactiveValue" STRING ;
BA_DEF_ SG_  "GenSigMissingSourceValue" INT 0 2147483647;
BA_DEF_ SG_  "GenSigStartValue" INT 0 0;
BA_DEF_ SG_  "Fehlerwert" HEX 0 2147483647;
BA_DEF_ SG_  "Bemerkung" STRING ;
BA_DEF_ SG_  "GenSigSendType" ENUM  "Cyclic","OnWrite","OnWriteWithRepetition","OnChange","OnChangeWithRepetition","IfActive","IfActiveWithRepetition","NoSigSendType";
BA_DEF_ BO_  "NmMessage" ENUM  "No","Yes";
BA_DEF_ BO_  "GenMsgAutoGenSnd" ENUM  "No","Yes";
BA_DEF_ BO_  "GenMsgAutoGenDsp" ENUM  "No","Yes";
BA_DEF_ BO_  "MsgType" ENUM  "Broadcast","Event","NM ","NMH","TP2.0","ISO-TP ","BAP","EID";
BA_DEF_ BO_  "GenMsgChkConstant" HEX 0 4095;
BA_DEF_ BO_  "sim_GenMsgILSupport" ENUM  "No","Yes";
BA_DEF_ BO_  "NWM-Botschaft" ENUM  "No","Yes";
BA_DEF_ BO_  "VAGTP20_StatConnection" ENUM  "No","Yes";
BA_DEF_ BO_  "VAGTP20_DynSetup" ENUM  "No","Yes";
BA_DEF_ BO_  "VAGTP20_DynConnection" ENUM  "No","Yes";
BA_DEF_ BO_  "VAGTP20_API" HEX 0 255;
BA_DEF_ BO_  "Direkt_1zu1" ENUM  "Nein","Ja";
BA_DEF_ BO_  "GenMsgSendType" ENUM  "Cyclic","NotUsed","NotUsed","NotUsed","NotUsed","NotUsed","NotUsed","IfActive","NoMsgSendType","NotUsed";
BA_DEF_ BO_  "DiagResponse" ENUM  "No","Yes";
BA_DEF_ BO_  "DiagRequest" ENUM  "No","Yes";
BA_DEF_ BO_  "GenMsgDelayTime" INT 0 65535;
BA_DEF_ BO_  "GenMsgStartDelayTime" INT 0 65535;
BA_DEF_ BO_  "GenMsgILSupport" ENUM  "No","Yes";
BA_DEF_ BO_  "NmhMessage" ENUM  "No","Yes";
BA_DEF_ BO_  "GenMsgNrOfRepetition" INT 0 65535;
BA_DEF_ BO_  "GenMsgCycleTimeFast" INT 0 65535;
BA_DEF_ BO_  "DiagState" ENUM  "No","Yes";
BA_DEF_ BO_  "GenMsgCycleTime" INT 0 65535;
BA_DEF_REL_ BU_BO_REL_  "HYB_Tx_Verwendung" ENUM  "Rout","Calc";
BA_DEF_REL_ BU_BO_REL_  "HYB_Tx_Baureihe" ENUM  "G1+Derivate","G1","Derivate","vector_leerstring";
BA_DEF_REL_ BU_SG_REL_  "GenSigTimeoutTime" INT 0 65535;
BA_DEF_DEF_  "DERIVATE_Pruefung" "offen";
BA_DEF_DEF_  "HYB_Rx_Baureihe" "G1+Derivate";
BA_DEF_DEF_  "HYB_Rx_Verwendung" "DERIV_Rout";
BA_DEF_DEF_  "GenSigSwitchedByIgnition" "No";
BA_DEF_DEF_  "GenSigEnvVarType" "undef";
BA_DEF_DEF_  "GenSigAutoGenSnd" "No";
BA_DEF_DEF_  "GenSigAutoGenDsp" "No";
BA_DEF_DEF_  "GenSigActiveRepetitions" 0;
BA_DEF_DEF_  "GenSigFuncType" "NoFunction";
BA_DEF_DEF_  "Info_BCM_HutHut_Kommunikation" "Nein";
BA_DEF_DEF_  "NWM-WakeupAllowed" "Yes";
BA_DEF_DEF_  "GenSigInactiveValue" "0";
BA_DEF_DEF_  "GenSigMissingSourceValue" 0;
BA_DEF_DEF_  "GenSigStartValue" 0;
BA_DEF_DEF_  "Fehlerwert" 0;
BA_DEF_DEF_  "Bemerkung" "";
BA_DEF_DEF_  "GenSigSendType" "Cyclic";
BA_DEF_DEF_  "NmMessage" "No";
BA_DEF_DEF_  "GenMsgAutoGenSnd" "Yes";
BA_DEF_DEF_  "GenMsgAutoGenDsp" "Yes";
BA_DEF_DEF_  "MsgType" "Broadcast";
BA_DEF_DEF_  "GenMsgChkConstant" 0;
BA_DEF_DEF_  "sim_GenMsgILSupport" "No";
BA_DEF_DEF_  "NWM-Botschaft" "No";
BA_DEF_DEF_  "VAGTP20_StatConnection" "No";
BA_DEF_DEF_  "VAGTP20_DynSetup" "No";
BA_DEF_DEF_  "VAGTP20_DynConnection" "No";
BA_DEF_DEF_  "VAGTP20_API" 1;
BA_DEF_DEF_  "Direkt_1zu1" "Nein";
BA_DEF_DEF_  "GenMsgSendType" "Cyclic";
BA_DEF_DEF_  "DiagResponse" "No";
BA_DEF_DEF_  "DiagRequest" "No";
BA_DEF_DEF_  "GenMsgDelayTime" 0;
BA_DEF_DEF_  "GenMsgStartDelayTime" 0;
BA_DEF_DEF_  "GenMsgILSupport" "No";
BA_DEF_DEF_  "NmhMessage" "No";
BA_DEF_DEF_  "GenMsgNrOfRepetition" 0;
BA_DEF_DEF_  "GenMsgCycleTimeFast" 0;
BA_DEF_DEF_  "DiagState" "No";
BA_DEF_DEF_  "GenMsgCycleTime" 0;
BA_DEF_DEF_REL_ "HYB_Tx_Verwendung" "Rout";
BA_DEF_DEF_REL_ "HYB_Tx_Baureihe" "G1+Derivate";
BA_DEF_DEF_REL_ "GenSigTimeoutTime" 0;
BA_ "GenMsgCycleTime" BO_ 1089 100;
BA_ "GenMsgILSupport" BO_ 1089 1;
BA_ "VAGTP20_API" BO_ 1089 0;
BA_ "sim_GenMsgILSupport" BO_ 1089 1;
BA_ "GenMsgCycleTime" BO_ 158 20;
BA_ "GenMsgILSupport" BO_ 158 1;
BA_ "Direkt_1zu1" BO_ 158 1;
BA_ "VAGTP20_API" BO_ 158 0;
BA_ "sim_GenMsgILSupport" BO_ 158 1;
BA_ "GenMsgChkConstant" BO_ 158 158;
BA_ "DiagRequest" BO_ 2022 1;
BA_ "GenMsgSendType" BO_ 2022 8;
BA_ "Direkt_1zu1" BO_ 2022 1;
BA_ "VAGTP20_API" BO_ 2022 0;
BA_ "MsgType" BO_ 2022 5;
BA_ "DiagResponse" BO_ 2030 1;
BA_ "GenMsgSendType" BO_ 2030 8;
BA_ "Direkt_1zu1" BO_ 2030 1;
BA_ "VAGTP20_API" BO_ 2030 0;
BA_ "MsgType" BO_ 2030 5;
BA_ "DiagRequest" BO_ 2021 1;
BA_ "GenMsgSendType" BO_ 2021 8;
BA_ "Direkt_1zu1" BO_ 2021 1;
BA_ "VAGTP20_API" BO_ 2021 0;
BA_ "MsgType" BO_ 2021 5;
BA_ "DiagResponse" BO_ 2029 1;
BA_ "GenMsgSendType" BO_ 2029 8;
BA_ "Direkt_1zu1" BO_ 2029 1;
BA_ "VAGTP20_API" BO_ 2029 0;
BA_ "MsgType" BO_ 2029 5;
BA_ "GenMsgCycleTime" BO_ 1720 1000;
BA_ "GenMsgILSupport" BO_ 1720 1;
BA_ "VAGTP20_API" BO_ 1720 0;
BA_ "GenMsgCycleTime" BO_ 128 10;
BA_ "GenMsgILSupport" BO_ 128 1;
BA_ "Direkt_1zu1" BO_ 128 1;
BA_ "VAGTP20_API" BO_ 128 0;
BA_ "sim_GenMsgILSupport" BO_ 128 1;
BA_ "GenMsgChkConstant" BO_ 128 128;
BA_ "GenMsgCycleTime" BO_ 129 10;
BA_ "GenMsgILSupport" BO_ 129 1;
BA_ "Direkt_1zu1" BO_ 129 1;
BA_ "VAGTP20_API" BO_ 129 0;
BA_ "sim_GenMsgILSupport" BO_ 129 1;
BA_ "GenMsgChkConstant" BO_ 129 129;
BA_ "GenMsgCycleTime" BO_ 261 10;
BA_ "GenMsgILSupport" BO_ 261 1;
BA_ "Direkt_1zu1" BO_ 261 1;
BA_ "VAGTP20_API" BO_ 261 0;
BA_ "sim_GenMsgILSupport" BO_ 261 1;
BA_ "GenMsgChkConstant" BO_ 261 4;
BA_ "GenMsgCycleTime" BO_ 263 20;
BA_ "GenMsgILSupport" BO_ 263 1;
BA_ "VAGTP20_API" BO_ 263 0;
BA_ "sim_GenMsgILSupport" BO_ 263 1;
BA_ "GenMsgCycleTime" BO_ 782 50;
BA_ "GenMsgILSupport" BO_ 782 1;
BA_ "Direkt_1zu1" BO_ 782 1;
BA_ "VAGTP20_API" BO_ 782 0;
BA_ "sim_GenMsgILSupport" BO_ 782 1;
BA_ "GenMsgChkConstant" BO_ 782 13;
BA_ "GenMsgCycleTime" BO_ 1088 100;
BA_ "GenMsgILSupport" BO_ 1088 1;
BA_ "VAGTP20_API" BO_ 1088 0;
BA_ "sim_GenMsgILSupport" BO_ 1088 1;
BA_ "GenMsgCycleTime" BO_ 1600 500;
BA_ "GenMsgILSupport" BO_ 1600 1;
BA_ "VAGTP20_API" BO_ 1600 0;
BA_ "sim_GenMsgILSupport" BO_ 1600 1;
BA_ "GenMsgCycleTime" BO_ 1601 1000;
BA_ "GenMsgILSupport" BO_ 1601 1;
BA_ "Direkt_1zu1" BO_ 1601 1;
BA_ "VAGTP20_API" BO_ 1601 0;
BA_ "sim_GenMsgILSupport" BO_ 1601 1;
BA_ "GenMsgChkConstant" BO_ 1601 71;
BA_ "GenMsgCycleTime" BO_ 157 20;
BA_ "GenMsgILSupport" BO_ 157 1;
BA_ "Direkt_1zu1" BO_ 157 1;
BA_ "VAGTP20_API" BO_ 157 0;
BA_ "sim_GenMsgILSupport" BO_ 157 1;
BA_ "GenMsgChkConstant" BO_ 157 157;
BA_ "GenMsgCycleTime" BO_ 811 50;
BA_ "GenMsgILSupport" BO_ 811 1;
BA_ "VAGTP20_API" BO_ 811 0;
BA_ "sim_GenMsgILSupport" BO_ 811 1;
BA_ "GenMsgCycleTime" BO_ 933 100;
BA_ "GenMsgILSupport" BO_ 933 1;
BA_ "GenMsgDelayTime" BO_ 933 50;
BA_ "VAGTP20_API" BO_ 933 0;
BA_ "sim_GenMsgILSupport" BO_ 933 1;
BA_ "GenMsgCycleTime" BO_ 1730 200;
BA_ "NmhMessage" BO_ 1730 1;
BA_ "GenMsgSendType" BO_ 1730 8;
BA_ "VAGTP20_API" BO_ 1730 0;
BA_ "MsgType" BO_ 1730 3;
BA_ "GenMsgCycleTime" BO_ 1729 200;
BA_ "NmhMessage" BO_ 1729 1;
BA_ "GenMsgSendType" BO_ 1729 8;
BA_ "VAGTP20_API" BO_ 1729 0;
BA_ "MsgType" BO_ 1729 3;
BA_ "GenMsgCycleTime" BO_ 913 100;
BA_ "GenMsgILSupport" BO_ 913 1;
BA_ "VAGTP20_API" BO_ 913 0;
BA_ "sim_GenMsgILSupport" BO_ 913 1;
BA_ "GenMsgCycleTime" BO_ 270 20;
BA_ "GenMsgILSupport" BO_ 270 1;
BA_ "Direkt_1zu1" BO_ 270 1;
BA_ "VAGTP20_API" BO_ 270 0;
BA_ "sim_GenMsgILSupport" BO_ 270 1;
BA_ "GenMsgChkConstant" BO_ 270 15;
BA_ "GenMsgCycleTime" BO_ 273 20;
BA_ "GenMsgILSupport" BO_ 273 1;
BA_ "Direkt_1zu1" BO_ 273 1;
BA_ "VAGTP20_API" BO_ 273 0;
BA_ "sim_GenMsgILSupport" BO_ 273 1;
BA_ "GenMsgChkConstant" BO_ 273 16;
BA_ "GenMsgCycleTime" BO_ 915 80;
BA_ "GenMsgILSupport" BO_ 915 1;
BA_ "GenMsgDelayTime" BO_ 915 10;
BA_ "Direkt_1zu1" BO_ 915 1;
BA_ "VAGTP20_API" BO_ 915 0;
BA_ "sim_GenMsgILSupport" BO_ 915 1;
BA_ "GenMsgChkConstant" BO_ 915 144;
BA_ "GenMsgCycleTime" BO_ 1602 2000;
BA_ "GenMsgILSupport" BO_ 1602 1;
BA_ "GenMsgDelayTime" BO_ 1602 200;
BA_ "VAGTP20_API" BO_ 1602 0;
BA_ "sim_GenMsgILSupport" BO_ 1602 1;
BA_ "GenMsgCycleTime" BO_ 1646 2000;
BA_ "GenMsgILSupport" BO_ 1646 1;
BA_ "GenMsgDelayTime" BO_ 1646 200;
BA_ "sim_GenMsgILSupport" BO_ 1646 1;
BA_ "GenMsgCycleTime" BO_ 1636 500;
BA_ "GenMsgILSupport" BO_ 1636 1;
BA_ "sim_GenMsgILSupport" BO_ 1636 1;
BA_ "GenMsgCycleTime" BO_ 959 100;
BA_ "GenMsgILSupport" BO_ 959 1;
BA_ "sim_GenMsgILSupport" BO_ 959 1;
BA_ "GenMsgSendType" BO_ 2041 8;
BA_ "Direkt_1zu1" BO_ 2041 1;
BA_ "MsgType" BO_ 2041 1;
BA_ "GenMsgSendType" BO_ 2033 8;
BA_ "Direkt_1zu1" BO_ 2033 1;
BA_ "MsgType" BO_ 2033 1;
BA_ "NWM-WakeupAllowed" SG_ 1089 GE_OBD_AbsperrVent 0;
BA_ "NWM-WakeupAllowed" SG_ 1089 GE_Freigabe_Verfallsinfo_WFS 0;
BA_ "Fehlerwert" SG_ 1089 GE_Index_Fahrwid 255;
BA_ "GenSigStartValue" SG_ 1089 GE_Index_Fahrwid 127;
BA_ "GenSigStartValue" SG_ 1089 GE_Heizwunsch 1;
BA_ "Fehlerwert" SG_ 1089 GE_Grenzkriechmoment 63;
BA_ "GenSigStartValue" SG_ 1089 GE_Grenzkriechmoment 62;
BA_ "Fehlerwert" SG_ 1089 GE_Verlustmoment 255;
BA_ "GenSigStartValue" SG_ 1089 GE_amax_moeglich 84;
BA_ "Fehlerwert" SG_ 1089 GE_Sumpftemperatur 255;
BA_ "GenSigFuncType" SG_ 158 Getriebe_Hybrid_01_CHK 4;
BA_ "GenSigFuncType" SG_ 158 Getriebe_Hybrid_01_BZ 1;
BA_ "Fehlerwert" SG_ 158 GE_HYB_nK0 255;
BA_ "NWM-WakeupAllowed" SG_ 158 GE_HYB_Filt_MomAufbau 0;
BA_ "GenSigSendType" SG_ 2022 ISO_EMotor_01_Req_Data 7;
BA_ "GenSigSendType" SG_ 2030 ISO_EMotor_01_Resp_Data 7;
BA_ "GenSigSendType" SG_ 2021 ISO_Hybrid_01_Req_Data 7;
BA_ "GenSigSendType" SG_ 2029 ISO_Hybrid_01_Resp_Data 7;
BA_ "Fehlerwert" SG_ 1720 KBI_Tankfuellstand_Prozent 127;
BA_ "GenSigStartValue" SG_ 1720 KBI_Tankfuellstand_Prozent 126;
BA_ "NWM-WakeupAllowed" SG_ 1720 KBI_Tankfuellstand_Prozent 0;
BA_ "Fehlerwert" SG_ 1720 KBI_Tankinhalt_hochaufl 16383;
BA_ "GenSigStartValue" SG_ 1720 KBI_Tankinhalt_hochaufl 16382;
BA_ "NWM-WakeupAllowed" SG_ 1720 KBI_Tankinhalt_hochaufl 0;
BA_ "GenSigAutoGenDsp" SG_ 1720 KBI_Tankinhalt_hochaufl 1;
BA_ "GenSigAutoGenSnd" SG_ 1720 KBI_Tankinhalt_hochaufl 1;
BA_ "NWM-WakeupAllowed" SG_ 1720 KBI_Nachtanken_erkannt 0;
BA_ "GenSigAutoGenDsp" SG_ 1720 KBI_Nachtanken_erkannt 1;
BA_ "GenSigAutoGenSnd" SG_ 1720 KBI_Nachtanken_erkannt 1;
BA_ "GenSigFuncType" SG_ 128 Motor_01_CHK 4;
BA_ "GenSigFuncType" SG_ 128 Motor_01_BZ 1;
BA_ "Fehlerwert" SG_ 128 MO_Mom_o_ex 1023;
BA_ "GenSigStartValue" SG_ 128 MO_Mom_o_ex 1022;
BA_ "Fehlerwert" SG_ 128 MO_Mom_m_ex 1023;
BA_ "GenSigStartValue" SG_ 128 MO_Mom_m_ex 1022;
BA_ "Fehlerwert" SG_ 128 MO_Mom_Verlust 1023;
BA_ "GenSigStartValue" SG_ 128 MO_Mom_Verlust 1022;
BA_ "Fehlerwert" SG_ 128 MO_Mom_Begrenzung 1023;
BA_ "GenSigStartValue" SG_ 128 MO_Mom_Begrenzung 1022;
BA_ "Fehlerwert" SG_ 128 MO_Mom_Fahrerwunsch 1023;
BA_ "GenSigStartValue" SG_ 128 MO_Mom_Fahrerwunsch 1022;
BA_ "GenSigStartValue" SG_ 129 MO_StartStopp_Status 2;
BA_ "NWM-WakeupAllowed" SG_ 129 MO_StartStopp_Fahrerwunsch 0;
BA_ "GenSigFuncType" SG_ 129 Motor_02_CHK 4;
BA_ "GenSigFuncType" SG_ 129 Motor_02_BZ 1;
BA_ "Fehlerwert" SG_ 129 MO_Mom_ZWR 1023;
BA_ "GenSigStartValue" SG_ 129 MO_Mom_ZWR 1022;
BA_ "Fehlerwert" SG_ 129 MO_Mom_Soll 1023;
BA_ "GenSigStartValue" SG_ 129 MO_Mom_Soll 1022;
BA_ "Fehlerwert" SG_ 129 MO_Mom_Ist 1023;
BA_ "GenSigStartValue" SG_ 129 MO_Mom_Ist 1022;
BA_ "Fehlerwert" SG_ 129 MO_Gangposition 15;
BA_ "GenSigStartValue" SG_ 129 MO_Gangposition 14;
BA_ "NWM-WakeupAllowed" SG_ 129 MO_Gangposition 0;
BA_ "GenSigStartValue" SG_ 261 MO_QBit_Motormomente 1;
BA_ "GenSigFuncType" SG_ 261 Motor_03_CHK 4;
BA_ "GenSigFuncType" SG_ 261 Motor_03_BZ 1;
BA_ "GenSigStartValue" SG_ 261 MO_QBit_Fahrpedalwerte_01 1;
BA_ "GenSigStartValue" SG_ 261 MO_QBit_Fahrer_bremst 1;
BA_ "GenSigStartValue" SG_ 261 MO_QBit_Drehzahl_01 1;
BA_ "Fehlerwert" SG_ 261 MO_Drehzahl_01 65535;
BA_ "Fehlerwert" SG_ 261 MO_Solldrehz_Leerlauf 255;
BA_ "Fehlerwert" SG_ 261 MO_Fahrpedalrohwert_01 255;
BA_ "GenSigStartValue" SG_ 261 MO_QBit_Stressfaktor 1;
BA_ "Fehlerwert" SG_ 263 MO_Anzeigedrehz 4095;
BA_ "Fehlerwert" SG_ 263 MO_Ladedruck 511;
BA_ "Fehlerwert" SG_ 263 MO_Oeldruck_HYB 255;
BA_ "GenSigStartValue" SG_ 263 MO_Oeldruck_HYB 254;
BA_ "NWM-WakeupAllowed" SG_ 263 MO_Oeldruck_HYB 0;
BA_ "NWM-WakeupAllowed" SG_ 782 MO_Handshake_STH 0;
BA_ "GenSigFuncType" SG_ 782 Motor_05_CHK 4;
BA_ "GenSigFuncType" SG_ 782 Motor_05_BZ 1;
BA_ "Fehlerwert" SG_ 782 MO_MAX_Wunschdrehzahl 511;
BA_ "GenSigStartValue" SG_ 782 MO_Anf_KL75 1;
BA_ "Fehlerwert" SG_ 782 MO_MIN_Wunschdrehzahl 255;
BA_ "NWM-WakeupAllowed" SG_ 1088 MO_Kat_Warnung 0;
BA_ "NWM-WakeupAllowed" SG_ 1088 MO_ITM_Warnung_Pumpe 0;
BA_ "NWM-WakeupAllowed" SG_ 1088 MO_HYB_Text_4 0;
BA_ "NWM-WakeupAllowed" SG_ 1088 MO_HYB_Status_HV_Ladung 0;
BA_ "GenSigStartValue" SG_ 1088 MO_Zustand_HWP 1;
BA_ "NWM-WakeupAllowed" SG_ 1088 MO_Zustand_HWP 0;
BA_ "Fehlerwert" SG_ 1088 MO_Kuehlerluefter_1 127;
BA_ "GenSigStartValue" SG_ 1088 MO_Kuehlerluefter_1 126;
BA_ "Fehlerwert" SG_ 1088 MO_Kuehlerluefter_2 127;
BA_ "GenSigStartValue" SG_ 1088 MO_Kuehlerluefter_2 126;
BA_ "NWM-WakeupAllowed" SG_ 1088 WIV_Oeldyn_avl 0;
BA_ "NWM-WakeupAllowed" SG_ 1088 MO_HYB_Text_7 0;
BA_ "NWM-WakeupAllowed" SG_ 1088 MO_HYB_Text_6 0;
BA_ "NWM-WakeupAllowed" SG_ 1088 MO_HYB_Text_5 0;
BA_ "NWM-WakeupAllowed" SG_ 1088 MO_HYB_Text_3 0;
BA_ "NWM-WakeupAllowed" SG_ 1088 MO_HYB_Text_2 0;
BA_ "NWM-WakeupAllowed" SG_ 1088 MO_HYB_Text_1 0;
BA_ "NWM-WakeupAllowed" SG_ 1600 MO_Nachlaufzeit_Heizungspumpe 0;
BA_ "Bemerkung" SG_ 1600 MO_Kennfeldk "0=keine Kennfeldkühlung vorhanden; 1=Kennfeldkühlung vorhanden";
BA_ "GenSigStartValue" SG_ 1600 MO_QBit_Ansaugluft_Temp 1;
BA_ "GenSigStartValue" SG_ 1600 MO_QBit_Oel_Temp 1;
BA_ "GenSigStartValue" SG_ 1600 MO_QBit_Kuehlmittel_Temp 1;
BA_ "Fehlerwert" SG_ 1600 MO_Ansaugluft_Temp 255;
BA_ "GenSigStartValue" SG_ 1600 MO_Ansaugluft_Temp 254;
BA_ "Fehlerwert" SG_ 1600 MO_Oel_Temp 255;
BA_ "GenSigStartValue" SG_ 1600 MO_Oel_Temp 254;
BA_ "Fehlerwert" SG_ 1600 MO_Kuehlmittel_Temp 255;
BA_ "GenSigStartValue" SG_ 1600 MO_Kuehlmittel_Temp 254;
BA_ "Fehlerwert" SG_ 1600 MO_Hoeheninfo 255;
BA_ "GenSigStartValue" SG_ 1600 MO_Heizungspumpenansteuerung 14;
BA_ "NWM-WakeupAllowed" SG_ 1600 MO_SpannungsAnf 0;
BA_ "NWM-WakeupAllowed" SG_ 1600 MO_aktives_Getriebeheizen 0;
BA_ "GenSigFuncType" SG_ 1601 Motor_Code_01_CHK 4;
BA_ "GenSigFuncType" SG_ 1601 Motor_Code_01_BZ 1;
BA_ "NWM-WakeupAllowed" SG_ 157 MO_HYB_EMode_Info 0;
BA_ "GenSigAutoGenDsp" SG_ 157 MO_HYB_EMode_Info 1;
BA_ "GenSigAutoGenSnd" SG_ 157 MO_HYB_EMode_Info 1;
BA_ "GenSigFuncType" SG_ 157 Motor_Hybrid_01_CHK 4;
BA_ "GenSigFuncType" SG_ 157 Motor_Hybrid_01_BZ 1;
BA_ "Fehlerwert" SG_ 157 MO_HYB_IstStatusK0 3;
BA_ "Fehlerwert" SG_ 157 MO_HYB_max_ind_VM_Mom 1023;
BA_ "GenSigStartValue" SG_ 157 MO_HYB_max_ind_VM_Mom 1022;
BA_ "Fehlerwert" SG_ 157 MO_HYB_Zielzustand 7;
BA_ "Fehlerwert" SG_ 157 MO_HYB_VM_Mom_oE 1023;
BA_ "GenSigStartValue" SG_ 157 MO_HYB_VM_Mom_oE 100;
BA_ "NWM-WakeupAllowed" SG_ 811 MO_FahrPr7_verfuegbar 0;
BA_ "NWM-WakeupAllowed" SG_ 811 MO_FahrPr6_verfuegbar 0;
BA_ "NWM-WakeupAllowed" SG_ 811 MO_FahrPr5_verfuegbar 0;
BA_ "NWM-WakeupAllowed" SG_ 811 MO_FahrPr4_verfuegbar 0;
BA_ "NWM-WakeupAllowed" SG_ 811 MO_FahrPr3_verfuegbar 0;
BA_ "NWM-WakeupAllowed" SG_ 811 MO_FahrPr2_verfuegbar 0;
BA_ "NWM-WakeupAllowed" SG_ 811 MO_FahrPr1_verfuegbar 0;
BA_ "Fehlerwert" SG_ 811 MO_HYB_Drehzahl_VM 65280;
BA_ "Fehlerwert" SG_ 933 Enrgfluss_State 255;
BA_ "NWM-WakeupAllowed" SG_ 933 Enrgfluss_State 0;
BA_ "Fehlerwert" SG_ 933 Ladezustand 255;
BA_ "NWM-WakeupAllowed" SG_ 933 Ladezustand 0;
BA_ "Fehlerwert" SG_ 933 Energiefluss 255;
BA_ "GenSigStartValue" SG_ 933 Energiefluss 128;
BA_ "Fehlerwert" SG_ 933 Enrgrueckfluss 255;
BA_ "Fehlerwert" SG_ 933 MO_Temp_MotRaum 63;
BA_ "GenSigStartValue" SG_ 933 MO_Temp_MotRaum 62;
BA_ "NWM-WakeupAllowed" SG_ 933 MO_Temp_MotRaum 0;
BA_ "Fehlerwert" SG_ 933 MO_Oel_Temp_Radsatz 255;
BA_ "GenSigStartValue" SG_ 933 MO_Oel_Temp_Radsatz 254;
BA_ "NWM-WakeupAllowed" SG_ 933 MO_Oel_Temp_Radsatz 0;
BA_ "GenSigSendType" SG_ 933 MO_Anf_Abgasklappe 3;
BA_ "GenSigSendType" SG_ 933 MO_LED_Abgasklappe 3;
BA_ "NWM-WakeupAllowed" SG_ 933 MO_Hoch_Anz_Nmax 0;
BA_ "GenSigSendType" SG_ 933 MO_Hoch_Anz_Nmax 3;
BA_ "NWM-WakeupAllowed" SG_ 933 MO_Hoch_Anz_Eco 0;
BA_ "GenSigSendType" SG_ 933 MO_Hoch_Anz_Eco 3;
BA_ "NWM-WakeupAllowed" SG_ 933 MO_Fehler_MSpG 0;
BA_ "GenSigStartValue" SG_ 1730 NMH_GE_Start_1 1;
BA_ "GenSigStartValue" SG_ 1729 NMH_MO_Start_1 1;
BA_ "GenSigStartValue" SG_ 913 OBD_Calc_Load_Val 255;
BA_ "GenSigStartValue" SG_ 913 OBD_Eng_Cool_Temp 255;
BA_ "GenSigStartValue" SG_ 913 OBD_Abs_Throttle_Pos 255;
BA_ "GenSigStartValue" SG_ 913 OBD_Abs_Load_Val 65535;
BA_ "GenSigStartValue" SG_ 913 OBD_Abs_Pedal_Pos 255;
BA_ "NWM-WakeupAllowed" SG_ 913 OBD_Sperrung_IUMPR 0;
BA_ "NWM-WakeupAllowed" SG_ 913 OBD_Kaltstart_Denominator 0;
BA_ "NWM-WakeupAllowed" SG_ 913 OBD_Minimum_Trip 0;
BA_ "GenSigFuncType" SG_ 270 TSK_04_CHK 4;
BA_ "GenSigFuncType" SG_ 270 TSK_04_BZ 1;
BA_ "GenSigStartValue" SG_ 270 TSK_ax_Getriebe 84;
BA_ "Fehlerwert" SG_ 273 TSK_Fahrzeugmasse_02 255;
BA_ "GenSigFuncType" SG_ 273 TSK_05_CHK 4;
BA_ "GenSigFuncType" SG_ 273 TSK_05_BZ 1;
BA_ "GenSigStartValue" SG_ 273 TSK_QBit_Steigung 1;
BA_ "Fehlerwert" SG_ 273 TSK_Fahrzeugmasse 31;
BA_ "GenSigStartValue" SG_ 273 TSK_QBit_Fahrzeugmasse 1;
BA_ "Fehlerwert" SG_ 273 TSK_Steigung 255;
BA_ "GenSigStartValue" SG_ 273 TSK_Verzoeg_Anf_02 166;
BA_ "NWM-WakeupAllowed" SG_ 915 WBA_GE_Zusatzwarnungen 0;
BA_ "GenSigSendType" SG_ 915 WBA_GE_Zusatzwarnungen 3;
BA_ "NWM-WakeupAllowed" SG_ 915 WBA_Effizienzmodus 0;
BA_ "GenSigSendType" SG_ 915 WBA_GE_Texte 3;
BA_ "GenSigSendType" SG_ 915 WBA_Schaltschema_Aktiv 3;
BA_ "GenSigSendType" SG_ 915 WH_Warnung 3;
BA_ "GenSigFuncType" SG_ 915 WBA_02_BZ 1;
BA_ "GenSigSendType" SG_ 915 WBA_Senderkennung 3;
BA_ "GenSigSendType" SG_ 915 WBA_Lampe_Shift_Lock 3;
BA_ "GenSigSendType" SG_ 915 WBA_Blinken 3;
BA_ "GenSigSendType" SG_ 915 WBA_Getriebevariante 3;
BA_ "GenSigSendType" SG_ 915 WBA_GE_Warnung 3;
BA_ "GenSigSendType" SG_ 915 WBA_Fahrstufe 3;
BA_ "GenSigStartValue" SG_ 915 WBA_eing_Gang 1;
BA_ "GenSigSendType" SG_ 915 WBA_eing_Gang 3;
BA_ "GenSigFuncType" SG_ 915 WBA_02_CHK 4;
BA_ "Fehlerwert" SG_ 1602 WIV_Verschleissindex 65535;
BA_ "Fehlerwert" SG_ 1602 WIV_Russindex 65535;
BA_ "GenSigStartValue" SG_ 1602 WIV_t_min 12;
BA_ "GenSigStartValue" SG_ 1602 WIV_t_max 24;
BA_ "GenSigStartValue" SG_ 1602 WIV_W_min 17;
BA_ "GenSigStartValue" SG_ 1602 WIV_W_max 31;
BA_ "GenSigSendType" SG_ 1646 KL_STL_aktiv 3;
BA_ "GenSigSendType" SG_ 1646 KL_STH_Betriebsdauer 3;
BA_ "GenSigSendType" SG_ 1646 KL_STH_Ansteuerung 3;
BA_ "GenSigSendType" SG_ 1646 KL_STH_aktiv 3;
BA_ "GenSigMissingSourceValue" SG_ 1646 KL_Innen_Temp 255;
BA_ "Fehlerwert" SG_ 1646 KL_AussenTemp_WK 255;
BA_ "GenSigStartValue" SG_ 1646 KL_AussenTemp_WK 254;
BA_ "GenSigMissingSourceValue" SG_ 1646 KL_AussenTemp_WK 255;
BA_ "Fehlerwert" SG_ 1636 KL_I_Geblaese 255;
BA_ "NWM-WakeupAllowed" SG_ 1636 KL_Beschlagsgefahr 0;
BA_ "Fehlerwert" SG_ 1636 KL_Umluftklappe_Status 15;
BA_ "GenSigStartValue" SG_ 1636 KL_Umluftklappe_Status 14;
BA_ "Fehlerwert" SG_ 1636 KL_Geblaese_Status 15;
BA_ "GenSigStartValue" SG_ 1636 KL_Geblaese_Status 14;
BA_ "GenSigMissingSourceValue" SG_ 1636 KL_Geblaese_Status 15;
BA_ "Bemerkung" SG_ 959 KL_Drehz_Anh "0=keine Drehzahlanhebung; 1=Drehzahlanhebung";
BA_ "Bemerkung" SG_ 959 KL_Anf_KL "Ansteuerung des Kuehlerluefters in Prozent";
BA_ "Fehlerwert" SG_ 959 KL_Last_Kompr 255;
BA_ "GenSigSendType" SG_ 2041 Response_Airbag_Deployment 1;
BA_ "GenSigSendType" SG_ 2033 Request_Airbag_Deployment 1;
BA_REL_ "GenSigTimeoutTime" BU_SG_REL_ GW_Routing_Derivate SG_ 1089 GE_OBD_AbsperrVent 1000;
BA_REL_ "GenSigTimeoutTime" BU_SG_REL_ Motor_EDC17_Pirol SG_ 1089 GE_OBD_AbsperrVent 1000;
BA_REL_ "GenSigTimeoutTime" BU_SG_REL_ Motor_MED17_Hybrid SG_ 1089 GE_OBD_AbsperrVent 1000;
BA_REL_ "GenSigTimeoutTime" BU_SG_REL_ GW_Routing_Derivate SG_ 1089 GE_Freigabe_Verfallsinfo_WFS 1000;
BA_REL_ "GenSigTimeoutTime" BU_SG_REL_ GW_Routing_Derivate SG_ 1089 GE_Index_Fahrwid 1000;
BA_REL_ "GenSigTimeoutTime" BU_SG_REL_ Motor_EDC17_Pirol SG_ 1089 GE_Index_Fahrwid 1000;
BA_REL_ "GenSigTimeoutTime" BU_SG_REL_ PSM_Ant_Derivate SG_ 1089 GE_Index_Fahrwid 1000;
BA_REL_ "GenSigTimeoutTime" BU_SG_REL_ Motor_MED17_Hybrid SG_ 1089 GE_Index_Fahrwid 1000;
BA_REL_ "GenSigTimeoutTime" BU_SG_REL_ GW_Routing_Derivate SG_ 1089 GE_Heizwunsch 1000;
BA_REL_ "GenSigTimeoutTime" BU_SG_REL_ PSM_Ant_Derivate SG_ 1089 GE_Heizwunsch 1000;
BA_REL_ "GenSigTimeoutTime" BU_SG_REL_ Motor_MED17_Hybrid SG_ 1089 GE_Heizwunsch 1000;
BA_REL_ "GenSigTimeoutTime" BU_SG_REL_ Motor_EDC17_Pirol SG_ 1089 GE_Heizwunsch 1000;
BA_REL_ "GenSigTimeoutTime" BU_SG_REL_ GW_Routing_Derivate SG_ 1089 GE_OBD_Status 1000;
BA_REL_ "GenSigTimeoutTime" BU_SG_REL_ Motor_EDC17_Pirol SG_ 1089 GE_OBD_Status 1000;
BA_REL_ "GenSigTimeoutTime" BU_SG_REL_ PSM_Ant_Derivate SG_ 1089 GE_OBD_Status 1000;
BA_REL_ "GenSigTimeoutTime" BU_SG_REL_ Motor_MED17_Hybrid SG_ 1089 GE_OBD_Status 1000;
BA_REL_ "GenSigTimeoutTime" BU_SG_REL_ GW_Routing_Derivate SG_ 1089 GE_LFR_Adaption 1000;
BA_REL_ "GenSigTimeoutTime" BU_SG_REL_ Motor_EDC17_Pirol SG_ 1089 GE_LFR_Adaption 1000;
BA_REL_ "GenSigTimeoutTime" BU_SG_REL_ PSM_Ant_Derivate SG_ 1089 GE_LFR_Adaption 1000;
BA_REL_ "GenSigTimeoutTime" BU_SG_REL_ Motor_MED17_Hybrid SG_ 1089 GE_LFR_Adaption 1000;
BA_REL_ "GenSigTimeoutTime" BU_SG_REL_ GW_Routing_Derivate SG_ 1089 GE_Grenzkriechmoment 1000;
BA_REL_ "GenSigTimeoutTime" BU_SG_REL_ PSM_Ant_Derivate SG_ 1089 GE_Grenzkriechmoment 1000;
BA_REL_ "GenSigTimeoutTime" BU_SG_REL_ GW_Routing_Derivate SG_ 1089 GE_Charisma_FahrPr 1000;
BA_REL_ "GenSigTimeoutTime" BU_SG_REL_ GW_Routing_Derivate SG_ 1089 GE_Charisma_Status 1000;
BA_REL_ "GenSigTimeoutTime" BU_SG_REL_ PSM_Ant_Derivate SG_ 1089 GE_Charisma_Status 1000;
BA_REL_ "GenSigTimeoutTime" BU_SG_REL_ GW_Routing_Derivate SG_ 1089 GE_Charisma_Umschaltung 1000;
BA_REL_ "GenSigTimeoutTime" BU_SG_REL_ GW_Routing_Derivate SG_ 1089 GE_Verlustmoment 1000;
BA_REL_ "GenSigTimeoutTime" BU_SG_REL_ Motor_EDC17_Pirol SG_ 1089 GE_Verlustmoment 1000;
BA_REL_ "GenSigTimeoutTime" BU_SG_REL_ PSM_Ant_Derivate SG_ 1089 GE_Verlustmoment 1000;
BA_REL_ "GenSigTimeoutTime" BU_SG_REL_ Motor_MED17_Hybrid SG_ 1089 GE_Verlustmoment 1000;
BA_REL_ "GenSigTimeoutTime" BU_SG_REL_ GW_Routing_Derivate SG_ 1089 GE_amax_moeglich 1000;
BA_REL_ "GenSigTimeoutTime" BU_SG_REL_ Motor_EDC17_Pirol SG_ 1089 GE_amax_moeglich 1000;
BA_REL_ "GenSigTimeoutTime" BU_SG_REL_ PSM_Ant_Derivate SG_ 1089 GE_amax_moeglich 1000;
BA_REL_ "GenSigTimeoutTime" BU_SG_REL_ Motor_MED17_Hybrid SG_ 1089 GE_amax_moeglich 1000;
BA_REL_ "GenSigTimeoutTime" BU_SG_REL_ GW_Routing_Derivate SG_ 1089 GE_Sumpftemperatur 1000;
BA_REL_ "GenSigTimeoutTime" BU_SG_REL_ BMS_Hybrid SG_ 1089 GE_Sumpftemperatur 1000;
BA_REL_ "GenSigTimeoutTime" BU_SG_REL_ Motor_EDC17_Pirol SG_ 1089 GE_Sumpftemperatur 1000;
BA_REL_ "GenSigTimeoutTime" BU_SG_REL_ PSM_Ant_Derivate SG_ 1089 GE_Sumpftemperatur 1000;
BA_REL_ "GenSigTimeoutTime" BU_SG_REL_ Motor_MED17_Hybrid SG_ 1089 GE_Sumpftemperatur 1000;
BA_REL_ "GenSigTimeoutTime" BU_SG_REL_ Motor_MED17_Hybrid SG_ 158 Getriebe_Hybrid_01_BZ 500;
BA_REL_ "GenSigTimeoutTime" BU_SG_REL_ Motor_MED17_Hybrid SG_ 158 GE_HYB_Fehlerstatus 500;
BA_REL_ "GenSigTimeoutTime" BU_SG_REL_ Motor_MED17_Hybrid SG_ 158 GE_HYB_Freigabe_K0 500;
BA_REL_ "GenSigTimeoutTime" BU_SG_REL_ Motor_MED17_Hybrid SG_ 158 GE_HYB_Freigabe_LL_Reg 500;
BA_REL_ "GenSigTimeoutTime" BU_SG_REL_ Motor_MED17_Hybrid SG_ 158 GE_HYB_Freig_sSchl_K0 500;
BA_REL_ "GenSigTimeoutTime" BU_SG_REL_ Motor_MED17_Hybrid SG_ 158 GE_HYB_Freig_VM_EM_Stop 500;
BA_REL_ "GenSigTimeoutTime" BU_SG_REL_ Motor_MED17_Hybrid SG_ 158 GE_HYB_Wiederstart 500;
BA_REL_ "GenSigTimeoutTime" BU_SG_REL_ Motor_MED17_Hybrid SG_ 158 GE_HYB_Sportfaktor 500;
BA_REL_ "GenSigTimeoutTime" BU_SG_REL_ Motor_MED17_Hybrid SG_ 158 GE_HYB_VM_akt_halten 500;
BA_REL_ "GenSigTimeoutTime" BU_SG_REL_ Motor_MED17_Hybrid SG_ 158 GE_HYB_StartAnf 500;
BA_REL_ "GenSigTimeoutTime" BU_SG_REL_ Motor_MED17_Hybrid SG_ 158 GE_HYB_VM_Startkontr 500;
BA_REL_ "GenSigTimeoutTime" BU_SG_REL_ LEH_Hybrid SG_ 2022 ISO_EMotor_01_Req_Data 500;
BA_REL_ "GenSigTimeoutTime" BU_SG_REL_ GW_Routing_Derivate SG_ 2030 ISO_EMotor_01_Resp_Data 500;
BA_REL_ "GenSigTimeoutTime" BU_SG_REL_ BMS_Hybrid SG_ 2021 ISO_Hybrid_01_Req_Data 500;
BA_REL_ "GenSigTimeoutTime" BU_SG_REL_ GW_Routing_Derivate SG_ 2029 ISO_Hybrid_01_Resp_Data 500;
BA_REL_ "GenSigTimeoutTime" BU_SG_REL_ BMS_Hybrid SG_ 1720 KBI_Tankinhalt_hochaufl 5000;
BA_REL_ "GenSigTimeoutTime" BU_SG_REL_ BMS_Hybrid SG_ 1720 KBI_Nachtanken_erkannt 5000;
BA_REL_ "GenSigTimeoutTime" BU_SG_REL_ Motor_MED17_Hybrid SG_ 1720 KBI_Reifenumfang 5000;
BA_REL_ "GenSigTimeoutTime" BU_SG_REL_ PSM_Ant_Derivate SG_ 1720 KBI_Reifenumfang 5000;
BA_REL_ "GenSigTimeoutTime" BU_SG_REL_ PSM_Ant_Derivate SG_ 128 Motor_01_CHK 500;
BA_REL_ "GenSigTimeoutTime" BU_SG_REL_ GW_Routing_Derivate SG_ 128 Motor_01_CHK 500;
BA_REL_ "GenSigTimeoutTime" BU_SG_REL_ Getriebe_Derivate SG_ 128 Motor_01_CHK 500;
BA_REL_ "GenSigTimeoutTime" BU_SG_REL_ PSM_Ant_Derivate SG_ 128 Motor_01_BZ 500;
BA_REL_ "GenSigTimeoutTime" BU_SG_REL_ GW_Routing_Derivate SG_ 128 Motor_01_BZ 500;
BA_REL_ "GenSigTimeoutTime" BU_SG_REL_ Getriebe_Derivate SG_ 128 Motor_01_BZ 500;
BA_REL_ "GenSigTimeoutTime" BU_SG_REL_ PSM_Ant_Derivate SG_ 128 MO_Mom_o_ex 500;
BA_REL_ "GenSigTimeoutTime" BU_SG_REL_ GW_Routing_Derivate SG_ 128 MO_Mom_o_ex 500;
BA_REL_ "GenSigTimeoutTime" BU_SG_REL_ Getriebe_Derivate SG_ 128 MO_Mom_o_ex 500;
BA_REL_ "GenSigTimeoutTime" BU_SG_REL_ PSM_Ant_Derivate SG_ 128 MO_Mom_m_ex 500;
BA_REL_ "GenSigTimeoutTime" BU_SG_REL_ GW_Routing_Derivate SG_ 128 MO_Mom_m_ex 500;
BA_REL_ "GenSigTimeoutTime" BU_SG_REL_ Getriebe_Derivate SG_ 128 MO_Mom_m_ex 500;
BA_REL_ "GenSigTimeoutTime" BU_SG_REL_ PSM_Ant_Derivate SG_ 128 MO_Mom_Verlust 500;
BA_REL_ "GenSigTimeoutTime" BU_SG_REL_ GW_Routing_Derivate SG_ 128 MO_Mom_Verlust 500;
BA_REL_ "GenSigTimeoutTime" BU_SG_REL_ Getriebe_Derivate SG_ 128 MO_Mom_Verlust 500;
BA_REL_ "GenSigTimeoutTime" BU_SG_REL_ PSM_Ant_Derivate SG_ 128 MO_Mom_Begrenzung 500;
BA_REL_ "GenSigTimeoutTime" BU_SG_REL_ GW_Routing_Derivate SG_ 128 MO_Mom_Begrenzung 500;
BA_REL_ "GenSigTimeoutTime" BU_SG_REL_ Getriebe_Derivate SG_ 128 MO_Mom_Begrenzung 500;
BA_REL_ "GenSigTimeoutTime" BU_SG_REL_ PSM_Ant_Derivate SG_ 128 MO_Mom_Fahrerwunsch 500;
BA_REL_ "GenSigTimeoutTime" BU_SG_REL_ GW_Routing_Derivate SG_ 128 MO_Mom_Fahrerwunsch 500;
BA_REL_ "GenSigTimeoutTime" BU_SG_REL_ Getriebe_Derivate SG_ 128 MO_Mom_Fahrerwunsch 500;
BA_REL_ "GenSigTimeoutTime" BU_SG_REL_ PSM_Ant_Derivate SG_ 128 MO_Kickdown 500;
BA_REL_ "GenSigTimeoutTime" BU_SG_REL_ GW_Routing_Derivate SG_ 128 MO_Kickdown 500;
BA_REL_ "GenSigTimeoutTime" BU_SG_REL_ Getriebe_Derivate SG_ 128 MO_Kickdown 500;
BA_REL_ "GenSigTimeoutTime" BU_SG_REL_ PSM_Ant_Derivate SG_ 128 MO_KD_Fehler 500;
BA_REL_ "GenSigTimeoutTime" BU_SG_REL_ GW_Applikation_Derivate SG_ 128 MO_KD_Fehler 500;
BA_REL_ "GenSigTimeoutTime" BU_SG_REL_ GW_Routing_Derivate SG_ 128 MO_KD_Fehler 500;
BA_REL_ "GenSigTimeoutTime" BU_SG_REL_ GW_Routing_Derivate SG_ 129 MO_StartStopp_Wiederstart 500;
BA_REL_ "GenSigTimeoutTime" BU_SG_REL_ PSM_Ant_Derivate SG_ 129 MO_StartStopp_Wiederstart 500;
BA_REL_ "GenSigTimeoutTime" BU_SG_REL_ GW_Applikation_Derivate SG_ 129 MO_StartStopp_Wiederstart 500;
BA_REL_ "GenSigTimeoutTime" BU_SG_REL_ Getriebe_Derivate SG_ 129 MO_StartStopp_Wiederstart 500;
BA_REL_ "GenSigTimeoutTime" BU_SG_REL_ GW_Routing_Derivate SG_ 129 MO_StartStopp_Status 500;
BA_REL_ "GenSigTimeoutTime" BU_SG_REL_ PSM_Ant_Derivate SG_ 129 MO_StartStopp_Status 500;
BA_REL_ "GenSigTimeoutTime" BU_SG_REL_ GW_Applikation_Derivate SG_ 129 MO_StartStopp_Status 500;
BA_REL_ "GenSigTimeoutTime" BU_SG_REL_ GW_Routing_Derivate SG_ 129 MO_StartStopp_Motorstopp 500;
BA_REL_ "GenSigTimeoutTime" BU_SG_REL_ LEH_Hybrid SG_ 129 MO_StartStopp_Motorstopp 500;
BA_REL_ "GenSigTimeoutTime" BU_SG_REL_ PSM_Ant_Derivate SG_ 129 MO_StartStopp_Motorstopp 500;
BA_REL_ "GenSigTimeoutTime" BU_SG_REL_ GW_Applikation_Derivate SG_ 129 MO_StartStopp_Motorstopp 500;
BA_REL_ "GenSigTimeoutTime" BU_SG_REL_ Getriebe_Derivate SG_ 129 MO_StartStopp_Motorstopp 500;
BA_REL_ "GenSigTimeoutTime" BU_SG_REL_ GW_Routing_Derivate SG_ 129 MO_StartStopp_Fahrerwunsch 500;
BA_REL_ "GenSigTimeoutTime" BU_SG_REL_ PSM_Ant_Derivate SG_ 129 Motor_02_CHK 500;
BA_REL_ "GenSigTimeoutTime" BU_SG_REL_ GW_Routing_Derivate SG_ 129 Motor_02_CHK 500;
BA_REL_ "GenSigTimeoutTime" BU_SG_REL_ Getriebe_Derivate SG_ 129 Motor_02_CHK 500;
BA_REL_ "GenSigTimeoutTime" BU_SG_REL_ PSM_Ant_Derivate SG_ 129 Motor_02_BZ 500;
BA_REL_ "GenSigTimeoutTime" BU_SG_REL_ GW_Routing_Derivate SG_ 129 Motor_02_BZ 500;
BA_REL_ "GenSigTimeoutTime" BU_SG_REL_ Getriebe_Derivate SG_ 129 Motor_02_BZ 500;
BA_REL_ "GenSigTimeoutTime" BU_SG_REL_ PSM_Ant_Derivate SG_ 129 MO_Mom_ZWR 500;
BA_REL_ "GenSigTimeoutTime" BU_SG_REL_ Getriebe_Derivate SG_ 129 MO_Mom_ZWR 500;
BA_REL_ "GenSigTimeoutTime" BU_SG_REL_ PSM_Ant_Derivate SG_ 129 MO_Mom_Soll 500;
BA_REL_ "GenSigTimeoutTime" BU_SG_REL_ PSM_Ant_Derivate SG_ 129 MO_Mom_Ist 500;
BA_REL_ "GenSigTimeoutTime" BU_SG_REL_ Getriebe_Derivate SG_ 129 MO_Mom_Ist 500;
BA_REL_ "GenSigTimeoutTime" BU_SG_REL_ PSM_Ant_Derivate SG_ 129 MO_Status_Zylabschalt_01 500;
BA_REL_ "GenSigTimeoutTime" BU_SG_REL_ PSM_Ant_Derivate SG_ 129 MO_Status_Normalbetrieb_01 500;
BA_REL_ "GenSigTimeoutTime" BU_SG_REL_ Getriebe_Derivate SG_ 129 MO_Status_Normalbetrieb_01 500;
BA_REL_ "GenSigTimeoutTime" BU_SG_REL_ PSM_Ant_Derivate SG_ 129 MO_Momentenintegral 500;
BA_REL_ "GenSigTimeoutTime" BU_SG_REL_ Getriebe_Derivate SG_ 129 MO_Momentenintegral 500;
BA_REL_ "GenSigTimeoutTime" BU_SG_REL_ Getriebe_Derivate SG_ 129 MO_Ext_E_Fahrt_aktiv 500;
BA_REL_ "GenSigTimeoutTime" BU_SG_REL_ GW_Routing_Derivate SG_ 129 MO_Ext_E_Fahrt_aktiv 500;
BA_REL_ "GenSigTimeoutTime" BU_SG_REL_ Getriebe_Derivate SG_ 261 MO_QBit_Motormomente 500;
BA_REL_ "GenSigTimeoutTime" BU_SG_REL_ GW_Routing_Derivate SG_ 261 MO_QBit_Motormomente 500;
BA_REL_ "GenSigTimeoutTime" BU_SG_REL_ PSM_Ant_Derivate SG_ 261 MO_QBit_Motormomente 500;
BA_REL_ "GenSigTimeoutTime" BU_SG_REL_ BMS_Hybrid SG_ 261 Motor_03_CHK 500;
BA_REL_ "GenSigTimeoutTime" BU_SG_REL_ PSM_Ant_Derivate SG_ 261 Motor_03_CHK 500;
BA_REL_ "GenSigTimeoutTime" BU_SG_REL_ LEH_Hybrid SG_ 261 Motor_03_CHK 500;
BA_REL_ "GenSigTimeoutTime" BU_SG_REL_ GW_Routing_Derivate SG_ 261 Motor_03_CHK 500;
BA_REL_ "GenSigTimeoutTime" BU_SG_REL_ Getriebe_Derivate SG_ 261 Motor_03_CHK 500;
BA_REL_ "GenSigTimeoutTime" BU_SG_REL_ BMS_Hybrid SG_ 261 Motor_03_BZ 500;
BA_REL_ "GenSigTimeoutTime" BU_SG_REL_ PSM_Ant_Derivate SG_ 261 Motor_03_BZ 500;
BA_REL_ "GenSigTimeoutTime" BU_SG_REL_ LEH_Hybrid SG_ 261 Motor_03_BZ 500;
BA_REL_ "GenSigTimeoutTime" BU_SG_REL_ GW_Routing_Derivate SG_ 261 Motor_03_BZ 500;
BA_REL_ "GenSigTimeoutTime" BU_SG_REL_ Getriebe_Derivate SG_ 261 Motor_03_BZ 500;
BA_REL_ "GenSigTimeoutTime" BU_SG_REL_ BMS_Hybrid SG_ 261 MO_QBit_Fahrpedalwerte_01 500;
BA_REL_ "GenSigTimeoutTime" BU_SG_REL_ PSM_Ant_Derivate SG_ 261 MO_QBit_Fahrpedalwerte_01 500;
BA_REL_ "GenSigTimeoutTime" BU_SG_REL_ GW_Routing_Derivate SG_ 261 MO_QBit_Fahrpedalwerte_01 500;
BA_REL_ "GenSigTimeoutTime" BU_SG_REL_ Getriebe_Derivate SG_ 261 MO_QBit_Fahrpedalwerte_01 500;
BA_REL_ "GenSigTimeoutTime" BU_SG_REL_ PSM_Ant_Derivate SG_ 261 MO_QBit_Fahrer_bremst 500;
BA_REL_ "GenSigTimeoutTime" BU_SG_REL_ GW_Routing_Derivate SG_ 261 MO_QBit_Fahrer_bremst 500;
BA_REL_ "GenSigTimeoutTime" BU_SG_REL_ Getriebe_Derivate SG_ 261 MO_QBit_Fahrer_bremst 500;
BA_REL_ "GenSigTimeoutTime" BU_SG_REL_ PSM_Ant_Derivate SG_ 261 MO_QBit_Drehzahl_01 500;
BA_REL_ "GenSigTimeoutTime" BU_SG_REL_ BMS_Hybrid SG_ 261 MO_QBit_Drehzahl_01 500;
BA_REL_ "GenSigTimeoutTime" BU_SG_REL_ GW_Routing_Derivate SG_ 261 MO_QBit_Drehzahl_01 500;
BA_REL_ "GenSigTimeoutTime" BU_SG_REL_ Getriebe_Derivate SG_ 261 MO_QBit_Drehzahl_01 500;
BA_REL_ "GenSigTimeoutTime" BU_SG_REL_ LEH_Hybrid SG_ 261 MO_QBit_Drehzahl_01 500;
BA_REL_ "GenSigTimeoutTime" BU_SG_REL_ PSM_Ant_Derivate SG_ 261 MO_Drehzahl_01 500;
BA_REL_ "GenSigTimeoutTime" BU_SG_REL_ BMS_Hybrid SG_ 261 MO_Drehzahl_01 500;
BA_REL_ "GenSigTimeoutTime" BU_SG_REL_ GW_Applikation_Derivate SG_ 261 MO_Drehzahl_01 500;
BA_REL_ "GenSigTimeoutTime" BU_SG_REL_ GW_Routing_Derivate SG_ 261 MO_Drehzahl_01 500;
BA_REL_ "GenSigTimeoutTime" BU_SG_REL_ Getriebe_Derivate SG_ 261 MO_Drehzahl_01 500;
BA_REL_ "GenSigTimeoutTime" BU_SG_REL_ LEH_Hybrid SG_ 261 MO_Drehzahl_01 500;
BA_REL_ "GenSigTimeoutTime" BU_SG_REL_ PSM_Ant_Derivate SG_ 261 MO_Moment_im_Leerlauf 500;
BA_REL_ "GenSigTimeoutTime" BU_SG_REL_ GW_Routing_Derivate SG_ 261 MO_Moment_im_Leerlauf 500;
BA_REL_ "GenSigTimeoutTime" BU_SG_REL_ Getriebe_Derivate SG_ 261 MO_Moment_im_Leerlauf 500;
BA_REL_ "GenSigTimeoutTime" BU_SG_REL_ PSM_Ant_Derivate SG_ 261 MO_Interlock 500;
BA_REL_ "GenSigTimeoutTime" BU_SG_REL_ GW_Routing_Derivate SG_ 261 MO_Interlock 500;
BA_REL_ "GenSigTimeoutTime" BU_SG_REL_ PSM_Ant_Derivate SG_ 261 MO_BLS 500;
BA_REL_ "GenSigTimeoutTime" BU_SG_REL_ GW_Routing_Derivate SG_ 261 MO_BLS 500;
BA_REL_ "GenSigTimeoutTime" BU_SG_REL_ Getriebe_Derivate SG_ 261 MO_BLS 500;
BA_REL_ "GenSigTimeoutTime" BU_SG_REL_ PSM_Ant_Derivate SG_ 261 MO_Fahrer_bremst 500;
BA_REL_ "GenSigTimeoutTime" BU_SG_REL_ GW_Routing_Derivate SG_ 261 MO_Fahrer_bremst 500;
BA_REL_ "GenSigTimeoutTime" BU_SG_REL_ Getriebe_Derivate SG_ 261 MO_Fahrer_bremst 500;
BA_REL_ "GenSigTimeoutTime" BU_SG_REL_ PSM_Ant_Derivate SG_ 261 MO_Konsistenz_Bremsped 500;
BA_REL_ "GenSigTimeoutTime" BU_SG_REL_ GW_Routing_Derivate SG_ 261 MO_Konsistenz_Bremsped 500;
BA_REL_ "GenSigTimeoutTime" BU_SG_REL_ PSM_Ant_Derivate SG_ 261 MO_Kuppl_schalter 500;
BA_REL_ "GenSigTimeoutTime" BU_SG_REL_ GW_Routing_Derivate SG_ 261 MO_Kuppl_schalter 500;
BA_REL_ "GenSigTimeoutTime" BU_SG_REL_ PSM_Ant_Derivate SG_ 261 MO_Timeout_ESP 500;
BA_REL_ "GenSigTimeoutTime" BU_SG_REL_ GW_Routing_Derivate SG_ 261 MO_Timeout_ESP 500;
BA_REL_ "GenSigTimeoutTime" BU_SG_REL_ PSM_Ant_Derivate SG_ 261 MO_Motor_laeuft 500;
BA_REL_ "GenSigTimeoutTime" BU_SG_REL_ GW_Applikation_Derivate SG_ 261 MO_Motor_laeuft 500;
BA_REL_ "GenSigTimeoutTime" BU_SG_REL_ GW_Routing_Derivate SG_ 261 MO_Motor_laeuft 500;
BA_REL_ "GenSigTimeoutTime" BU_SG_REL_ Getriebe_Derivate SG_ 261 MO_Motor_laeuft 500;
BA_REL_ "GenSigTimeoutTime" BU_SG_REL_ PSM_Ant_Derivate SG_ 261 MO_Solldrehz_Leerlauf 500;
BA_REL_ "GenSigTimeoutTime" BU_SG_REL_ GW_Routing_Derivate SG_ 261 MO_Solldrehz_Leerlauf 500;
BA_REL_ "GenSigTimeoutTime" BU_SG_REL_ Getriebe_Derivate SG_ 261 MO_Solldrehz_Leerlauf 500;
BA_REL_ "GenSigTimeoutTime" BU_SG_REL_ GW_Applikation_Derivate SG_ 261 MO_Solldrehz_Leerlauf 500;
BA_REL_ "GenSigTimeoutTime" BU_SG_REL_ BMS_Hybrid SG_ 261 MO_Fahrpedalrohwert_01 500;
BA_REL_ "GenSigTimeoutTime" BU_SG_REL_ PSM_Ant_Derivate SG_ 261 MO_Fahrpedalrohwert_01 500;
BA_REL_ "GenSigTimeoutTime" BU_SG_REL_ GW_Routing_Derivate SG_ 261 MO_Fahrpedalrohwert_01 500;
BA_REL_ "GenSigTimeoutTime" BU_SG_REL_ Getriebe_Derivate SG_ 261 MO_Fahrpedalrohwert_01 500;
BA_REL_ "GenSigTimeoutTime" BU_SG_REL_ PSM_Ant_Derivate SG_ 261 MO_erste_Ungenauschwelle 500;
BA_REL_ "GenSigTimeoutTime" BU_SG_REL_ GW_Routing_Derivate SG_ 261 MO_erste_Ungenauschwelle 500;
BA_REL_ "GenSigTimeoutTime" BU_SG_REL_ Getriebe_Derivate SG_ 261 MO_erste_Ungenauschwelle 500;
BA_REL_ "GenSigTimeoutTime" BU_SG_REL_ PSM_Ant_Derivate SG_ 261 MO_QBit_Stressfaktor 500;
BA_REL_ "GenSigTimeoutTime" BU_SG_REL_ GW_Routing_Derivate SG_ 261 MO_QBit_Stressfaktor 500;
BA_REL_ "GenSigTimeoutTime" BU_SG_REL_ PSM_Ant_Derivate SG_ 261 MO_Stressfaktor 500;
BA_REL_ "GenSigTimeoutTime" BU_SG_REL_ GW_Routing_Derivate SG_ 261 MO_Stressfaktor 500;
BA_REL_ "GenSigTimeoutTime" BU_SG_REL_ PSM_Ant_Derivate SG_ 263 MO_Anzeigedrehz 500;
BA_REL_ "GenSigTimeoutTime" BU_SG_REL_ GW_Routing_Derivate SG_ 263 MO_Anzeigedrehz 500;
BA_REL_ "GenSigTimeoutTime" BU_SG_REL_ BMS_Hybrid SG_ 263 MO_KVS 500;
BA_REL_ "GenSigTimeoutTime" BU_SG_REL_ PSM_Ant_Derivate SG_ 263 MO_KVS 500;
BA_REL_ "GenSigTimeoutTime" BU_SG_REL_ GW_Routing_Derivate SG_ 263 MO_KVS 500;
BA_REL_ "GenSigTimeoutTime" BU_SG_REL_ BMS_Hybrid SG_ 263 MO_KVS_Ueberlauf 500;
BA_REL_ "GenSigTimeoutTime" BU_SG_REL_ PSM_Ant_Derivate SG_ 263 MO_KVS_Ueberlauf 500;
BA_REL_ "GenSigTimeoutTime" BU_SG_REL_ GW_Routing_Derivate SG_ 263 MO_KVS_Ueberlauf 500;
BA_REL_ "GenSigTimeoutTime" BU_SG_REL_ GW_Routing_Derivate SG_ 263 MO_Ladedruck 500;
BA_REL_ "GenSigTimeoutTime" BU_SG_REL_ PSM_Ant_Derivate SG_ 263 MO_Ladedruck 500;
BA_REL_ "GenSigTimeoutTime" BU_SG_REL_ GW_Routing_Derivate SG_ 263 MO_Oeldruck_HYB 500;
BA_REL_ "GenSigTimeoutTime" BU_SG_REL_ GW_Routing_Derivate SG_ 782 MO_Handshake_STH 500;
BA_REL_ "GenSigTimeoutTime" BU_SG_REL_ GW_Routing_Derivate SG_ 782 Motor_05_CHK 500;
BA_REL_ "GenSigTimeoutTime" BU_SG_REL_ Getriebe_Derivate SG_ 782 Motor_05_CHK 500;
BA_REL_ "GenSigTimeoutTime" BU_SG_REL_ GW_Routing_Derivate SG_ 782 Motor_05_BZ 500;
BA_REL_ "GenSigTimeoutTime" BU_SG_REL_ Getriebe_Derivate SG_ 782 Motor_05_BZ 500;
BA_REL_ "GenSigTimeoutTime" BU_SG_REL_ GW_Routing_Derivate SG_ 782 MO_EKlKomLeiRed 500;
BA_REL_ "GenSigTimeoutTime" BU_SG_REL_ BMS_Hybrid SG_ 782 MO_Freig_Reku 500;
BA_REL_ "GenSigTimeoutTime" BU_SG_REL_ GW_Routing_Derivate SG_ 782 MO_Freig_Reku 500;
BA_REL_ "GenSigTimeoutTime" BU_SG_REL_ GW_Applikation_Derivate SG_ 782 MO_Freig_Reku 500;
BA_REL_ "GenSigTimeoutTime" BU_SG_REL_ GW_Routing_Derivate SG_ 782 MO_Klima_Eingr 500;
BA_REL_ "GenSigTimeoutTime" BU_SG_REL_ GW_Routing_Derivate SG_ 782 MO_Status_Normalbetrieb_02 500;
BA_REL_ "GenSigTimeoutTime" BU_SG_REL_ GW_Routing_Derivate SG_ 782 MO_Schaltbeeinfl_Leistungsbegr 500;
BA_REL_ "GenSigTimeoutTime" BU_SG_REL_ GW_Routing_Derivate SG_ 782 MO_Schaltbeeinfl_Partikelfilter 500;
BA_REL_ "GenSigTimeoutTime" BU_SG_REL_ Getriebe_Derivate SG_ 782 MO_Schaltbeeinfl_Partikelfilter 500;
BA_REL_ "GenSigTimeoutTime" BU_SG_REL_ GW_Routing_Derivate SG_ 782 MO_Prio_MIN_Wunschdrehzahl 500;
BA_REL_ "GenSigTimeoutTime" BU_SG_REL_ Getriebe_Derivate SG_ 782 MO_Prio_MIN_Wunschdrehzahl 500;
BA_REL_ "GenSigTimeoutTime" BU_SG_REL_ GW_Routing_Derivate SG_ 782 MO_Freig_Anlass 500;
BA_REL_ "GenSigTimeoutTime" BU_SG_REL_ GW_Routing_Derivate SG_ 782 MO_Aussp_Anlass 500;
BA_REL_ "GenSigTimeoutTime" BU_SG_REL_ GW_Routing_Derivate SG_ 782 MO_MAX_Wunschdrehzahl 500;
BA_REL_ "GenSigTimeoutTime" BU_SG_REL_ Getriebe_Derivate SG_ 782 MO_MAX_Wunschdrehzahl 500;
BA_REL_ "GenSigTimeoutTime" BU_SG_REL_ GW_Routing_Derivate SG_ 782 MO_Prio_MAX_Wunschdrehzahl 500;
BA_REL_ "GenSigTimeoutTime" BU_SG_REL_ Getriebe_Derivate SG_ 782 MO_Prio_MAX_Wunschdrehzahl 500;
BA_REL_ "GenSigTimeoutTime" BU_SG_REL_ GW_Routing_Derivate SG_ 782 MO_Luftpfad_aktiv 500;
BA_REL_ "GenSigTimeoutTime" BU_SG_REL_ GW_Routing_Derivate SG_ 782 MO_v_Begrenz_Aktiv 500;
BA_REL_ "GenSigTimeoutTime" BU_SG_REL_ GW_Routing_Derivate SG_ 782 MO_v_Begrenz_Aktivierbar 500;
BA_REL_ "GenSigTimeoutTime" BU_SG_REL_ GW_Routing_Derivate SG_ 782 MO_Verbot_EKP 500;
BA_REL_ "GenSigTimeoutTime" BU_SG_REL_ GW_Routing_Derivate SG_ 782 MO_Anf_Pruefimpuls 500;
BA_REL_ "GenSigTimeoutTime" BU_SG_REL_ GW_Routing_Derivate SG_ 782 MO_Anf_KL75 500;
BA_REL_ "GenSigTimeoutTime" BU_SG_REL_ GW_Routing_Derivate SG_ 782 MO_Charisma_FahrPr 500;
BA_REL_ "GenSigTimeoutTime" BU_SG_REL_ PSM_Ant_Derivate SG_ 782 MO_Charisma_Status 500;
BA_REL_ "GenSigTimeoutTime" BU_SG_REL_ GW_Routing_Derivate SG_ 782 MO_Charisma_Status 500;
BA_REL_ "GenSigTimeoutTime" BU_SG_REL_ GW_Routing_Derivate SG_ 782 MO_Charisma_Umschaltung 500;
BA_REL_ "GenSigTimeoutTime" BU_SG_REL_ GW_Routing_Derivate SG_ 782 MO_MIN_Wunschdrehzahl 500;
BA_REL_ "GenSigTimeoutTime" BU_SG_REL_ Getriebe_Derivate SG_ 782 MO_MIN_Wunschdrehzahl 500;
BA_REL_ "GenSigTimeoutTime" BU_SG_REL_ GW_Routing_Derivate SG_ 782 MO_Drehzahlbeeinflussung 500;
BA_REL_ "GenSigTimeoutTime" BU_SG_REL_ GW_Routing_Derivate SG_ 1088 MO_Kat_Warnung 1000;
BA_REL_ "GenSigTimeoutTime" BU_SG_REL_ GW_Routing_Derivate SG_ 1088 MO_ITM_Warnung_Pumpe 1000;
BA_REL_ "GenSigTimeoutTime" BU_SG_REL_ GW_Routing_Derivate SG_ 1088 MO_HYB_Text_4 1000;
BA_REL_ "GenSigTimeoutTime" BU_SG_REL_ GW_Routing_Derivate SG_ 1088 MO_HYB_Status_HV_Ladung 1000;
BA_REL_ "GenSigTimeoutTime" BU_SG_REL_ GW_Routing_Derivate SG_ 1088 MO_Zustand_HWP 1000;
BA_REL_ "GenSigTimeoutTime" BU_SG_REL_ GW_Routing_Derivate SG_ 1088 MO_Kuehlerluefter_MUX 1000;
BA_REL_ "GenSigTimeoutTime" BU_SG_REL_ GW_Routing_Derivate SG_ 1088 MO_Kuehlerluefter_1 1000;
BA_REL_ "GenSigTimeoutTime" BU_SG_REL_ GW_Routing_Derivate SG_ 1088 MO_Kuehlerluefter_2 1000;
BA_REL_ "GenSigTimeoutTime" BU_SG_REL_ GW_Routing_Derivate SG_ 1088 WIV_Anzeige_aktiv 1000;
BA_REL_ "GenSigTimeoutTime" BU_SG_REL_ GW_Routing_Derivate SG_ 1088 WIV_Oelmin_Warn 1000;
BA_REL_ "GenSigTimeoutTime" BU_SG_REL_ GW_Routing_Derivate SG_ 1088 WIV_Sensorfehler 1000;
BA_REL_ "GenSigTimeoutTime" BU_SG_REL_ GW_Routing_Derivate SG_ 1088 WIV_Schieflage 1000;
BA_REL_ "GenSigTimeoutTime" BU_SG_REL_ GW_Routing_Derivate SG_ 1088 WIV_Oelstand 1000;
BA_REL_ "GenSigTimeoutTime" BU_SG_REL_ GW_Routing_Derivate SG_ 1088 WIV_Oelsystem_aktiv 1000;
BA_REL_ "GenSigTimeoutTime" BU_SG_REL_ GW_Routing_Derivate SG_ 1088 WIV_nicht_betriebswarm 1000;
BA_REL_ "GenSigTimeoutTime" BU_SG_REL_ GW_Routing_Derivate SG_ 1088 WIV_Ueberfuell_Warn 1000;
BA_REL_ "GenSigTimeoutTime" BU_SG_REL_ GW_Routing_Derivate SG_ 1088 WIV_laufender_Motor 1000;
BA_REL_ "GenSigTimeoutTime" BU_SG_REL_ GW_Routing_Derivate SG_ 1088 MO_Text_Motorstart 1000;
BA_REL_ "GenSigTimeoutTime" BU_SG_REL_ GW_Routing_Derivate SG_ 1088 MO_Text_MSG_Werkstatt 1000;
BA_REL_ "GenSigTimeoutTime" BU_SG_REL_ GW_Routing_Derivate SG_ 1088 MO_Text_Partikelfil_Reg 1000;
BA_REL_ "GenSigTimeoutTime" BU_SG_REL_ GW_Routing_Derivate SG_ 1088 MO_Text_Fehler_Kraftstoffsys 1000;
BA_REL_ "GenSigTimeoutTime" BU_SG_REL_ GW_Routing_Derivate SG_ 1088 WIV_Oelmenge 1000;
BA_REL_ "GenSigTimeoutTime" BU_SG_REL_ GW_Routing_Derivate SG_ 1088 MO_Systemlampe 1000;
BA_REL_ "GenSigTimeoutTime" BU_SG_REL_ GW_Routing_Derivate SG_ 1088 MO_OBD2_Lampe 1000;
BA_REL_ "GenSigTimeoutTime" BU_SG_REL_ GW_Routing_Derivate SG_ 1088 MO_Heissleuchte 1000;
BA_REL_ "GenSigTimeoutTime" BU_SG_REL_ GW_Routing_Derivate SG_ 1088 MO_Partikel_Lampe 1000;
BA_REL_ "GenSigTimeoutTime" BU_SG_REL_ GW_Routing_Derivate SG_ 1088 MO_Winterfahrprog 1000;
BA_REL_ "GenSigTimeoutTime" BU_SG_REL_ GW_Routing_Derivate SG_ 1088 WIV_Oelstand_nicht_vorhanden 1000;
BA_REL_ "GenSigTimeoutTime" BU_SG_REL_ GW_Routing_Derivate SG_ 1088 WIV_nachfuellanzeige_ein 1000;
BA_REL_ "GenSigTimeoutTime" BU_SG_REL_ GW_Routing_Derivate SG_ 1088 WIV_Ueberfuell_deaktiv 1000;
BA_REL_ "GenSigTimeoutTime" BU_SG_REL_ GW_Routing_Derivate SG_ 1088 WIV_Unterfuell_Warn 1000;
BA_REL_ "GenSigTimeoutTime" BU_SG_REL_ GW_Routing_Derivate SG_ 1088 MO_Tankdeckel_Lampe 1000;
BA_REL_ "GenSigTimeoutTime" BU_SG_REL_ GW_Routing_Derivate SG_ 1088 MO_Text_Tankdeckelwarn 1000;
BA_REL_ "GenSigTimeoutTime" BU_SG_REL_ GW_Routing_Derivate SG_ 1088 WIV_Enable_Oeldr_Motor 1000;
BA_REL_ "GenSigTimeoutTime" BU_SG_REL_ GW_Routing_Derivate SG_ 1088 WIV_Oeldr_Warn_Motor 1000;
BA_REL_ "GenSigTimeoutTime" BU_SG_REL_ GW_Routing_Derivate SG_ 1088 MO_Avus_Motorschutz 1000;
BA_REL_ "GenSigTimeoutTime" BU_SG_REL_ BMS_Hybrid SG_ 1088 MO_HYB_Fahrbereitschaft 1000;
BA_REL_ "GenSigTimeoutTime" BU_SG_REL_ GW_Applikation_Derivate SG_ 1088 MO_HYB_Fahrbereitschaft 1000;
BA_REL_ "GenSigTimeoutTime" BU_SG_REL_ GW_Routing_Derivate SG_ 1088 MO_HYB_Fahrbereitschaft 1000;
BA_REL_ "GenSigTimeoutTime" BU_SG_REL_ GW_Routing_Derivate SG_ 1088 WIV_Oeldyn_avl 1000;
BA_REL_ "GenSigTimeoutTime" BU_SG_REL_ GW_Routing_Derivate SG_ 1088 MO_HYB_Text_7 1000;
BA_REL_ "GenSigTimeoutTime" BU_SG_REL_ GW_Routing_Derivate SG_ 1088 MO_HYB_Text_6 1000;
BA_REL_ "GenSigTimeoutTime" BU_SG_REL_ GW_Routing_Derivate SG_ 1088 MO_HYB_Text_5 1000;
BA_REL_ "GenSigTimeoutTime" BU_SG_REL_ GW_Routing_Derivate SG_ 1088 MO_HYB_Text_3 1000;
BA_REL_ "GenSigTimeoutTime" BU_SG_REL_ GW_Routing_Derivate SG_ 1088 MO_HYB_Text_2 1000;
BA_REL_ "GenSigTimeoutTime" BU_SG_REL_ GW_Routing_Derivate SG_ 1088 MO_HYB_Text_1 1000;
BA_REL_ "GenSigTimeoutTime" BU_SG_REL_ GW_Routing_Derivate SG_ 1600 MO_Nachlaufzeit_Heizungspumpe 5000;
BA_REL_ "GenSigTimeoutTime" BU_SG_REL_ GW_Routing_Derivate SG_ 1600 MO_Kennfeldk 5000;
BA_REL_ "GenSigTimeoutTime" BU_SG_REL_ GW_Routing_Derivate SG_ 1600 MO_QBit_Ansaugluft_Temp 5000;
BA_REL_ "GenSigTimeoutTime" BU_SG_REL_ GW_Routing_Derivate SG_ 1600 MO_QBit_Oel_Temp 5000;
BA_REL_ "GenSigTimeoutTime" BU_SG_REL_ GW_Routing_Derivate SG_ 1600 MO_QBit_Kuehlmittel_Temp 5000;
BA_REL_ "GenSigTimeoutTime" BU_SG_REL_ Getriebe_Derivate SG_ 1600 MO_QBit_Kuehlmittel_Temp 5000;
BA_REL_ "GenSigTimeoutTime" BU_SG_REL_ LEH_Hybrid SG_ 1600 MO_QBit_Kuehlmittel_Temp 5000;
BA_REL_ "GenSigTimeoutTime" BU_SG_REL_ GW_Routing_Derivate SG_ 1600 MO_Stellgliedtest_Soundaktuator 5000;
BA_REL_ "GenSigTimeoutTime" BU_SG_REL_ GW_Applikation_Derivate SG_ 1600 MO_HYB_Fehler_HV_Netz 5000;
BA_REL_ "GenSigTimeoutTime" BU_SG_REL_ GW_Routing_Derivate SG_ 1600 MO_HYB_Fehler_HV_Netz 5000;
BA_REL_ "GenSigTimeoutTime" BU_SG_REL_ GW_Routing_Derivate SG_ 1600 MO_Absperrventil_oeffnen 5000;
BA_REL_ "GenSigTimeoutTime" BU_SG_REL_ GW_Routing_Derivate SG_ 1600 MO_Ansaugluft_Temp 5000;
BA_REL_ "GenSigTimeoutTime" BU_SG_REL_ Getriebe_Derivate SG_ 1600 MO_Ansaugluft_Temp 5000;
BA_REL_ "GenSigTimeoutTime" BU_SG_REL_ GW_Routing_Derivate SG_ 1600 MO_Oel_Temp 5000;
BA_REL_ "GenSigTimeoutTime" BU_SG_REL_ BMS_Hybrid SG_ 1600 MO_Kuehlmittel_Temp 5000;
BA_REL_ "GenSigTimeoutTime" BU_SG_REL_ GW_Applikation_Derivate SG_ 1600 MO_Kuehlmittel_Temp 5000;
BA_REL_ "GenSigTimeoutTime" BU_SG_REL_ GW_Routing_Derivate SG_ 1600 MO_Kuehlmittel_Temp 5000;
BA_REL_ "GenSigTimeoutTime" BU_SG_REL_ Getriebe_Derivate SG_ 1600 MO_Kuehlmittel_Temp 5000;
BA_REL_ "GenSigTimeoutTime" BU_SG_REL_ LEH_Hybrid SG_ 1600 MO_Kuehlmittel_Temp 5000;
BA_REL_ "GenSigTimeoutTime" BU_SG_REL_ GW_Routing_Derivate SG_ 1600 MO_Hoeheninfo 5000;
BA_REL_ "GenSigTimeoutTime" BU_SG_REL_ Getriebe_Derivate SG_ 1600 MO_Hoeheninfo 5000;
BA_REL_ "GenSigTimeoutTime" BU_SG_REL_ Getriebe_Derivate SG_ 1600 MO_Versionsinfo 5000;
BA_REL_ "GenSigTimeoutTime" BU_SG_REL_ GW_Routing_Derivate SG_ 1600 MO_Versionsinfo 5000;
BA_REL_ "GenSigTimeoutTime" BU_SG_REL_ Getriebe_Derivate SG_ 1600 MO_Getriebe_kuehlen 5000;
BA_REL_ "GenSigTimeoutTime" BU_SG_REL_ GW_Routing_Derivate SG_ 1600 MO_Getriebe_kuehlen 5000;
BA_REL_ "GenSigTimeoutTime" BU_SG_REL_ GW_Routing_Derivate SG_ 1600 MO_Mom_Traegheit_02 5000;
BA_REL_ "GenSigTimeoutTime" BU_SG_REL_ GW_Routing_Derivate SG_ 1600 MO_Heizungspumpenansteuerung 5000;
BA_REL_ "GenSigTimeoutTime" BU_SG_REL_ GW_Applikation_Derivate SG_ 1600 MO_SpannungsAnf 5000;
BA_REL_ "GenSigTimeoutTime" BU_SG_REL_ GW_Routing_Derivate SG_ 1600 MO_SpannungsAnf 5000;
BA_REL_ "GenSigTimeoutTime" BU_SG_REL_ Getriebe_Derivate SG_ 1600 MO_aktives_Getriebeheizen 5000;
BA_REL_ "GenSigTimeoutTime" BU_SG_REL_ GW_Routing_Derivate SG_ 1600 MO_aktives_Getriebeheizen 5000;
BA_REL_ "GenSigTimeoutTime" BU_SG_REL_ PSM_Ant_Derivate SG_ 1601 MO_Kraftstoffart 5000;
BA_REL_ "GenSigTimeoutTime" BU_SG_REL_ GW_Routing_Derivate SG_ 1601 MO_Kraftstoffart 5000;
BA_REL_ "GenSigTimeoutTime" BU_SG_REL_ Getriebe_Derivate SG_ 1601 MO_Kraftstoffart 5000;
BA_REL_ "GenSigTimeoutTime" BU_SG_REL_ PSM_Ant_Derivate SG_ 1601 Motor_Code_01_CHK 5000;
BA_REL_ "GenSigTimeoutTime" BU_SG_REL_ LEH_Hybrid SG_ 1601 Motor_Code_01_CHK 5000;
BA_REL_ "GenSigTimeoutTime" BU_SG_REL_ GW_Routing_Derivate SG_ 1601 Motor_Code_01_CHK 5000;
BA_REL_ "GenSigTimeoutTime" BU_SG_REL_ Getriebe_Derivate SG_ 1601 Motor_Code_01_CHK 5000;
BA_REL_ "GenSigTimeoutTime" BU_SG_REL_ PSM_Ant_Derivate SG_ 1601 Motor_Code_01_BZ 5000;
BA_REL_ "GenSigTimeoutTime" BU_SG_REL_ LEH_Hybrid SG_ 1601 Motor_Code_01_BZ 5000;
BA_REL_ "GenSigTimeoutTime" BU_SG_REL_ GW_Routing_Derivate SG_ 1601 Motor_Code_01_BZ 5000;
BA_REL_ "GenSigTimeoutTime" BU_SG_REL_ Getriebe_Derivate SG_ 1601 Motor_Code_01_BZ 5000;
BA_REL_ "GenSigTimeoutTime" BU_SG_REL_ PSM_Ant_Derivate SG_ 1601 MO_Faktor_Momente 5000;
BA_REL_ "GenSigTimeoutTime" BU_SG_REL_ GW_Routing_Derivate SG_ 1601 MO_Faktor_Momente 5000;
BA_REL_ "GenSigTimeoutTime" BU_SG_REL_ Getriebe_Derivate SG_ 1601 MO_Faktor_Momente 5000;
BA_REL_ "GenSigTimeoutTime" BU_SG_REL_ PSM_Ant_Derivate SG_ 1601 MO_Hybridfahrzeug 5000;
BA_REL_ "GenSigTimeoutTime" BU_SG_REL_ GW_Routing_Derivate SG_ 1601 MO_Hybridfahrzeug 5000;
BA_REL_ "GenSigTimeoutTime" BU_SG_REL_ PSM_Ant_Derivate SG_ 1601 MO_Code 5000;
BA_REL_ "GenSigTimeoutTime" BU_SG_REL_ GW_Routing_Derivate SG_ 1601 MO_Code 5000;
BA_REL_ "GenSigTimeoutTime" BU_SG_REL_ Getriebe_Derivate SG_ 1601 MO_Code 5000;
BA_REL_ "GenSigTimeoutTime" BU_SG_REL_ PSM_Ant_Derivate SG_ 1601 MO_Getriebe_Code 5000;
BA_REL_ "GenSigTimeoutTime" BU_SG_REL_ GW_Routing_Derivate SG_ 1601 MO_Getriebe_Code 5000;
BA_REL_ "GenSigTimeoutTime" BU_SG_REL_ Getriebe_Derivate SG_ 1601 MO_Getriebe_Code 5000;
BA_REL_ "GenSigTimeoutTime" BU_SG_REL_ GW_Routing_Derivate SG_ 1601 MO_Anzahl_Zyl 5000;
BA_REL_ "GenSigTimeoutTime" BU_SG_REL_ GW_Routing_Derivate SG_ 1601 MO_Hubraum 5000;
BA_REL_ "GenSigTimeoutTime" BU_SG_REL_ GW_Routing_Derivate SG_ 1601 MO_Ansaugsystem 5000;
BA_REL_ "GenSigTimeoutTime" BU_SG_REL_ GW_Routing_Derivate SG_ 1601 MO_Leistung 5000;
BA_REL_ "GenSigTimeoutTime" BU_SG_REL_ Getriebe_Derivate SG_ 1601 MO_Leistung 5000;
BA_REL_ "GenSigTimeoutTime" BU_SG_REL_ LEH_Hybrid SG_ 1601 MO_Abgastyp 5000;
BA_REL_ "GenSigTimeoutTime" BU_SG_REL_ BMS_Hybrid SG_ 1601 MO_Abgastyp 5000;
BA_REL_ "GenSigTimeoutTime" BU_SG_REL_ GW_Routing_Derivate SG_ 1601 MO_Abgastyp 5000;
BA_REL_ "GenSigTimeoutTime" BU_SG_REL_ Getriebe_Derivate SG_ 1601 MO_Abgastyp 5000;
BA_REL_ "GenSigTimeoutTime" BU_SG_REL_ GW_Routing_Derivate SG_ 1601 MO_Einspritzart 5000;
BA_REL_ "GenSigTimeoutTime" BU_SG_REL_ GW_Routing_Derivate SG_ 1601 MO_StartStopp_Codiert 5000;
BA_REL_ "GenSigTimeoutTime" BU_SG_REL_ Getriebe_Derivate SG_ 1601 MO_StartStopp_Codiert 5000;
BA_REL_ "GenSigTimeoutTime" BU_SG_REL_ Getriebe_Derivate SG_ 157 MO_HYB_EMode_Info 500;
BA_REL_ "GenSigTimeoutTime" BU_SG_REL_ Getriebe_Derivate SG_ 157 Motor_Hybrid_01_CHK 500;
BA_REL_ "GenSigTimeoutTime" BU_SG_REL_ BMS_Hybrid SG_ 157 Motor_Hybrid_01_BZ 500;
BA_REL_ "GenSigTimeoutTime" BU_SG_REL_ Getriebe_Derivate SG_ 157 Motor_Hybrid_01_BZ 500;
BA_REL_ "GenSigTimeoutTime" BU_SG_REL_ Getriebe_Derivate SG_ 157 MO_HYB_IstStatusK0 500;
BA_REL_ "GenSigTimeoutTime" BU_SG_REL_ Getriebe_Derivate SG_ 157 MO_HYB_max_ind_VM_Mom 500;
BA_REL_ "GenSigTimeoutTime" BU_SG_REL_ BMS_Hybrid SG_ 157 MO_HYB_Zielzustand 500;
BA_REL_ "GenSigTimeoutTime" BU_SG_REL_ Getriebe_Derivate SG_ 157 MO_HYB_Zielzustand 500;
BA_REL_ "GenSigTimeoutTime" BU_SG_REL_ Getriebe_Derivate SG_ 157 MO_HYB_Startmodus 500;
BA_REL_ "GenSigTimeoutTime" BU_SG_REL_ Getriebe_Derivate SG_ 157 MO_HYB_VM_Mom_oE 500;
BA_REL_ "GenSigTimeoutTime" BU_SG_REL_ BMS_Hybrid SG_ 157 MO_HYB_VM_aktiv 500;
BA_REL_ "GenSigTimeoutTime" BU_SG_REL_ Getriebe_Derivate SG_ 157 MO_HYB_VM_aktiv 500;
BA_REL_ "GenSigTimeoutTime" BU_SG_REL_ GW_Routing_Derivate SG_ 157 MO_HYB_VM_aktiv 500;
BA_REL_ "GenSigTimeoutTime" BU_SG_REL_ Getriebe_Derivate SG_ 157 MO_HYB_Schaltverhinderung 500;
BA_REL_ "GenSigTimeoutTime" BU_SG_REL_ Getriebe_Derivate SG_ 157 MO_HYB_Selektor_Momverlauf_EM 500;
BA_REL_ "GenSigTimeoutTime" BU_SG_REL_ Getriebe_Derivate SG_ 157 MO_HYB_Momverlauf_Rek 500;
BA_REL_ "GenSigTimeoutTime" BU_SG_REL_ Getriebe_Derivate SG_ 157 MO_HYB_KnickDZ_Rek 500;
BA_REL_ "GenSigTimeoutTime" BU_SG_REL_ Getriebe_Derivate SG_ 157 MO_HYB_Momverlauf_EM 500;
BA_REL_ "GenSigTimeoutTime" BU_SG_REL_ Getriebe_Derivate SG_ 157 MO_HYB_KnickDZ_EM 500;
BA_REL_ "GenSigTimeoutTime" BU_SG_REL_ GW_Routing_Derivate SG_ 811 MO_FahrPr7_verfuegbar 500;
BA_REL_ "GenSigTimeoutTime" BU_SG_REL_ GW_Routing_Derivate SG_ 811 MO_FahrPr6_verfuegbar 500;
BA_REL_ "GenSigTimeoutTime" BU_SG_REL_ GW_Routing_Derivate SG_ 811 MO_FahrPr5_verfuegbar 500;
BA_REL_ "GenSigTimeoutTime" BU_SG_REL_ GW_Routing_Derivate SG_ 811 MO_FahrPr4_verfuegbar 500;
BA_REL_ "GenSigTimeoutTime" BU_SG_REL_ GW_Routing_Derivate SG_ 811 MO_FahrPr3_verfuegbar 500;
BA_REL_ "GenSigTimeoutTime" BU_SG_REL_ GW_Routing_Derivate SG_ 811 MO_FahrPr2_verfuegbar 500;
BA_REL_ "GenSigTimeoutTime" BU_SG_REL_ GW_Routing_Derivate SG_ 811 MO_FahrPr1_verfuegbar 500;
BA_REL_ "GenSigTimeoutTime" BU_SG_REL_ Getriebe_Derivate SG_ 811 MO_HYB_E_Faktor 500;
BA_REL_ "GenSigTimeoutTime" BU_SG_REL_ GW_Routing_Derivate SG_ 811 MO_HYB_E_Faktor 500;
BA_REL_ "GenSigTimeoutTime" BU_SG_REL_ Getriebe_Derivate SG_ 811 MO_HYB_Drehzahl_VM 500;
BA_REL_ "GenSigTimeoutTime" BU_SG_REL_ GW_Routing_Derivate SG_ 811 MO_HYB_Drehzahl_VM 500;
BA_REL_ "GenSigTimeoutTime" BU_SG_REL_ BMS_Hybrid SG_ 811 MO_HYB_Drehzahl_VM 500;
BA_REL_ "GenSigTimeoutTime" BU_SG_REL_ Getriebe_Derivate SG_ 811 MO_HYB_LowSpeedModus 500;
BA_REL_ "GenSigTimeoutTime" BU_SG_REL_ GW_Routing_Derivate SG_ 811 MO_HYB_LowSpeedModus 500;
BA_REL_ "GenSigTimeoutTime" BU_SG_REL_ GW_Routing_Derivate SG_ 933 MO_Overboost 1000;
BA_REL_ "GenSigTimeoutTime" BU_SG_REL_ GW_Routing_Derivate SG_ 933 Enrgfluss_State 1000;
BA_REL_ "GenSigTimeoutTime" BU_SG_REL_ GW_Routing_Derivate SG_ 933 Ladezustand 1000;
BA_REL_ "GenSigTimeoutTime" BU_SG_REL_ GW_Routing_Derivate SG_ 933 Energiefluss 1000;
BA_REL_ "GenSigTimeoutTime" BU_SG_REL_ GW_Routing_Derivate SG_ 933 Enrgrueckfluss 1000;
BA_REL_ "GenSigTimeoutTime" BU_SG_REL_ GW_Routing_Derivate SG_ 933 MO_Temp_MotRaum 1000;
BA_REL_ "GenSigTimeoutTime" BU_SG_REL_ GW_Routing_Derivate SG_ 933 MO_Oel_Temp_Radsatz 1000;
BA_REL_ "GenSigTimeoutTime" BU_SG_REL_ GW_Routing_Derivate SG_ 933 MO_Anf_Abgasklappe 1000;
BA_REL_ "GenSigTimeoutTime" BU_SG_REL_ GW_Routing_Derivate SG_ 933 MO_LED_Abgasklappe 1000;
BA_REL_ "GenSigTimeoutTime" BU_SG_REL_ GW_Routing_Derivate SG_ 933 MO_Hoch_Anz_Nmax 1000;
BA_REL_ "GenSigTimeoutTime" BU_SG_REL_ GW_Routing_Derivate SG_ 933 MO_Hoch_Anz_Eco 1000;
BA_REL_ "GenSigTimeoutTime" BU_SG_REL_ GW_Routing_Derivate SG_ 933 MO_Fehler_MSpG 1000;
BA_REL_ "GenSigTimeoutTime" BU_SG_REL_ Motor_EDC17_Pirol SG_ 1730 NMH_GE_Start_1 2000;
BA_REL_ "GenSigTimeoutTime" BU_SG_REL_ BMS_Hybrid SG_ 1730 NMH_GE_Start_1 2000;
BA_REL_ "GenSigTimeoutTime" BU_SG_REL_ LEH_Hybrid SG_ 1730 NMH_GE_Start_1 2000;
BA_REL_ "GenSigTimeoutTime" BU_SG_REL_ Ladegeraet_PAG_PF SG_ 1730 NMH_GE_Start_1 2000;
BA_REL_ "GenSigTimeoutTime" BU_SG_REL_ GW_Applikation_Derivate SG_ 1730 NMH_GE_Start_1 2000;
BA_REL_ "GenSigTimeoutTime" BU_SG_REL_ Motor_MED17_Hybrid SG_ 1730 NMH_GE_Start_1 2000;
BA_REL_ "GenSigTimeoutTime" BU_SG_REL_ GW_Applikation_Derivate SG_ 1730 NMH_GE_Start_2 2000;
BA_REL_ "GenSigTimeoutTime" BU_SG_REL_ GW_Applikation_Derivate SG_ 1730 NMH_GE_Normal_Mode_1 2000;
BA_REL_ "GenSigTimeoutTime" BU_SG_REL_ GW_Applikation_Derivate SG_ 1730 NMH_GE_Normal_Mode_2 2000;
BA_REL_ "GenSigTimeoutTime" BU_SG_REL_ BMS_Hybrid SG_ 1729 NMH_MO_Start_1 2000;
BA_REL_ "GenSigTimeoutTime" BU_SG_REL_ LEH_Hybrid SG_ 1729 NMH_MO_Start_1 2000;
BA_REL_ "GenSigTimeoutTime" BU_SG_REL_ Ladegeraet_PAG_PF SG_ 1729 NMH_MO_Start_1 2000;
BA_REL_ "GenSigTimeoutTime" BU_SG_REL_ GW_Applikation_Derivate SG_ 1729 NMH_MO_Start_1 2000;
BA_REL_ "GenSigTimeoutTime" BU_SG_REL_ Getriebe_Derivate SG_ 1729 NMH_MO_Start_1 2000;
BA_REL_ "GenSigTimeoutTime" BU_SG_REL_ GW_Applikation_Derivate SG_ 1729 NMH_MO_Start_2 2000;
BA_REL_ "GenSigTimeoutTime" BU_SG_REL_ GW_Applikation_Derivate SG_ 1729 NMH_MO_Normal_Mode_1 2000;
BA_REL_ "GenSigTimeoutTime" BU_SG_REL_ GW_Applikation_Derivate SG_ 1729 NMH_MO_Normal_Mode_2 2000;
BA_REL_ "GenSigTimeoutTime" BU_SG_REL_ BMS_Hybrid SG_ 913 OBD_Calc_Load_Val 1000;
BA_REL_ "GenSigTimeoutTime" BU_SG_REL_ Getriebe_Derivate SG_ 913 OBD_Calc_Load_Val 1000;
BA_REL_ "GenSigTimeoutTime" BU_SG_REL_ LEH_Hybrid SG_ 913 OBD_Calc_Load_Val 1000;
BA_REL_ "GenSigTimeoutTime" BU_SG_REL_ BMS_Hybrid SG_ 913 OBD_Eng_Cool_Temp 1000;
BA_REL_ "GenSigTimeoutTime" BU_SG_REL_ Getriebe_Derivate SG_ 913 OBD_Eng_Cool_Temp 1000;
BA_REL_ "GenSigTimeoutTime" BU_SG_REL_ LEH_Hybrid SG_ 913 OBD_Eng_Cool_Temp 1000;
BA_REL_ "GenSigTimeoutTime" BU_SG_REL_ BMS_Hybrid SG_ 913 OBD_Abs_Throttle_Pos 1000;
BA_REL_ "GenSigTimeoutTime" BU_SG_REL_ Getriebe_Derivate SG_ 913 OBD_Abs_Throttle_Pos 1000;
BA_REL_ "GenSigTimeoutTime" BU_SG_REL_ LEH_Hybrid SG_ 913 OBD_Abs_Throttle_Pos 1000;
BA_REL_ "GenSigTimeoutTime" BU_SG_REL_ BMS_Hybrid SG_ 913 OBD_Abs_Load_Val 1000;
BA_REL_ "GenSigTimeoutTime" BU_SG_REL_ Getriebe_Derivate SG_ 913 OBD_Abs_Load_Val 1000;
BA_REL_ "GenSigTimeoutTime" BU_SG_REL_ LEH_Hybrid SG_ 913 OBD_Abs_Load_Val 1000;
BA_REL_ "GenSigTimeoutTime" BU_SG_REL_ BMS_Hybrid SG_ 913 OBD_Abs_Pedal_Pos 1000;
BA_REL_ "GenSigTimeoutTime" BU_SG_REL_ Getriebe_Derivate SG_ 913 OBD_Abs_Pedal_Pos 1000;
BA_REL_ "GenSigTimeoutTime" BU_SG_REL_ LEH_Hybrid SG_ 913 OBD_Abs_Pedal_Pos 1000;
BA_REL_ "GenSigTimeoutTime" BU_SG_REL_ BMS_Hybrid SG_ 913 OBD_Driving_Cycle 1000;
BA_REL_ "GenSigTimeoutTime" BU_SG_REL_ Getriebe_Derivate SG_ 913 OBD_Driving_Cycle 1000;
BA_REL_ "GenSigTimeoutTime" BU_SG_REL_ LEH_Hybrid SG_ 913 OBD_Driving_Cycle 1000;
BA_REL_ "GenSigTimeoutTime" BU_SG_REL_ BMS_Hybrid SG_ 913 OBD_Warm_Up_Cycle 1000;
BA_REL_ "GenSigTimeoutTime" BU_SG_REL_ Getriebe_Derivate SG_ 913 OBD_Warm_Up_Cycle 1000;
BA_REL_ "GenSigTimeoutTime" BU_SG_REL_ LEH_Hybrid SG_ 913 OBD_Warm_Up_Cycle 1000;
BA_REL_ "GenSigTimeoutTime" BU_SG_REL_ GW_Applikation_Derivate SG_ 913 OBD_Warm_Up_Cycle 1000;
BA_REL_ "GenSigTimeoutTime" BU_SG_REL_ LEH_Hybrid SG_ 913 OBD_Normed_Trip 1000;
BA_REL_ "GenSigTimeoutTime" BU_SG_REL_ BMS_Hybrid SG_ 913 OBD_Normed_Trip 1000;
BA_REL_ "GenSigTimeoutTime" BU_SG_REL_ Getriebe_Derivate SG_ 913 OBD_Normed_Trip 1000;
BA_REL_ "GenSigTimeoutTime" BU_SG_REL_ BMS_Hybrid SG_ 913 OBD_Sperrung_IUMPR 1000;
BA_REL_ "GenSigTimeoutTime" BU_SG_REL_ LEH_Hybrid SG_ 913 OBD_Kaltstart_Denominator 1000;
BA_REL_ "GenSigTimeoutTime" BU_SG_REL_ BMS_Hybrid SG_ 913 OBD_Kaltstart_Denominator 1000;
BA_REL_ "GenSigTimeoutTime" BU_SG_REL_ LEH_Hybrid SG_ 913 OBD_Minimum_Trip 1000;
BA_REL_ "GenSigTimeoutTime" BU_SG_REL_ Getriebe_Derivate SG_ 913 OBD_Minimum_Trip 1000;
BA_REL_ "GenSigTimeoutTime" BU_SG_REL_ BMS_Hybrid SG_ 913 OBD_Minimum_Trip 1000;
BA_REL_ "GenSigTimeoutTime" BU_SG_REL_ Getriebe_Derivate SG_ 270 TSK_04_CHK 500;
BA_REL_ "GenSigTimeoutTime" BU_SG_REL_ Getriebe_Derivate SG_ 270 TSK_04_BZ 500;
BA_REL_ "GenSigTimeoutTime" BU_SG_REL_ Getriebe_Derivate SG_ 270 TSK_zul_Regelabw 500;
BA_REL_ "GenSigTimeoutTime" BU_SG_REL_ Getriebe_Derivate SG_ 270 TSK_ax_Getriebe 500;
BA_REL_ "GenSigTimeoutTime" BU_SG_REL_ Getriebe_Derivate SG_ 270 TSK_Limiter_aktiv 500;
BA_REL_ "GenSigTimeoutTime" BU_SG_REL_ Getriebe_Derivate SG_ 270 TSK_Status_GRA_ACC_02 500;
BA_REL_ "GenSigTimeoutTime" BU_SG_REL_ GW_Routing_Derivate SG_ 273 TSK_Fahrzeugmasse_02 500;
BA_REL_ "GenSigTimeoutTime" BU_SG_REL_ PSM_Ant_Derivate SG_ 273 TSK_05_CHK 500;
BA_REL_ "GenSigTimeoutTime" BU_SG_REL_ GW_Routing_Derivate SG_ 273 TSK_05_CHK 500;
BA_REL_ "GenSigTimeoutTime" BU_SG_REL_ Getriebe_Derivate SG_ 273 TSK_05_CHK 500;
BA_REL_ "GenSigTimeoutTime" BU_SG_REL_ PSM_Ant_Derivate SG_ 273 TSK_05_BZ 500;
BA_REL_ "GenSigTimeoutTime" BU_SG_REL_ GW_Routing_Derivate SG_ 273 TSK_05_BZ 500;
BA_REL_ "GenSigTimeoutTime" BU_SG_REL_ Getriebe_Derivate SG_ 273 TSK_05_BZ 500;
BA_REL_ "GenSigTimeoutTime" BU_SG_REL_ GW_Routing_Derivate SG_ 273 TSK_QBit_Steigung 500;
BA_REL_ "GenSigTimeoutTime" BU_SG_REL_ PSM_Ant_Derivate SG_ 273 TSK_Status_GRA_ACC_01 500;
BA_REL_ "GenSigTimeoutTime" BU_SG_REL_ GW_Routing_Derivate SG_ 273 TSK_Status_GRA_ACC_01 500;
BA_REL_ "GenSigTimeoutTime" BU_SG_REL_ Getriebe_Derivate SG_ 273 TSK_Fahrzeugmasse 500;
BA_REL_ "GenSigTimeoutTime" BU_SG_REL_ GW_Routing_Derivate SG_ 273 TSK_Fahrzeugmasse 500;
BA_REL_ "GenSigTimeoutTime" BU_SG_REL_ GW_Routing_Derivate SG_ 273 TSK_QBit_Fahrzeugmasse 500;
BA_REL_ "GenSigTimeoutTime" BU_SG_REL_ GW_Routing_Derivate SG_ 273 TSK_Steigung 500;
BA_REL_ "GenSigTimeoutTime" BU_SG_REL_ GW_Routing_Derivate SG_ 273 TSK_Getriebeinfo 500;
BA_REL_ "GenSigTimeoutTime" BU_SG_REL_ GW_Routing_Derivate SG_ 273 TSK_Codierung_ACC 500;
BA_REL_ "GenSigTimeoutTime" BU_SG_REL_ GW_Routing_Derivate SG_ 273 TSK_Zwangszusch_ESP 500;
BA_REL_ "GenSigTimeoutTime" BU_SG_REL_ GW_Routing_Derivate SG_ 273 TSK_Freig_Verzoeg_Anf 500;
BA_REL_ "GenSigTimeoutTime" BU_SG_REL_ GW_Routing_Derivate SG_ 273 TSK_Verzoeg_Anf_02 500;
BA_REL_ "GenSigTimeoutTime" BU_SG_REL_ GW_Routing_Derivate SG_ 915 WBA_Blinken 800;
BA_REL_ "GenSigTimeoutTime" BU_SG_REL_ GW_Routing_Derivate SG_ 915 WBA_GE_Warnung 800;
BA_REL_ "GenSigTimeoutTime" BU_SG_REL_ GW_Routing_Derivate SG_ 915 WBA_Fahrstufe 800;
BA_REL_ "GenSigTimeoutTime" BU_SG_REL_ GW_Routing_Derivate SG_ 915 WBA_eing_Gang 800;
BA_REL_ "GenSigTimeoutTime" BU_SG_REL_ GW_Routing_Derivate SG_ 1602 WIV_Verschleissindex 5000;
BA_REL_ "GenSigTimeoutTime" BU_SG_REL_ GW_Routing_Derivate SG_ 1602 WIV_Russindex 5000;
BA_REL_ "GenSigTimeoutTime" BU_SG_REL_ GW_Routing_Derivate SG_ 1602 WIV_t_min 5000;
BA_REL_ "GenSigTimeoutTime" BU_SG_REL_ GW_Routing_Derivate SG_ 1602 WIV_t_max 5000;
BA_REL_ "GenSigTimeoutTime" BU_SG_REL_ GW_Routing_Derivate SG_ 1602 WIV_W_min 5000;
BA_REL_ "GenSigTimeoutTime" BU_SG_REL_ GW_Routing_Derivate SG_ 1602 WIV_W_max 5000;
BA_REL_ "GenSigTimeoutTime" BU_SG_REL_ BMS_Hybrid SG_ 1646 KL_Innen_Temp 5000;
BA_REL_ "GenSigTimeoutTime" BU_SG_REL_ BMS_Hybrid SG_ 1646 KL_AussenTemp_WK 5000;
BA_REL_ "GenSigTimeoutTime" BU_SG_REL_ BMS_Hybrid SG_ 1636 KL_Umluftklappe_Status 5000;
BA_REL_ "GenSigTimeoutTime" BU_SG_REL_ BMS_Hybrid SG_ 1636 KL_Geblaese_Status 5000;
BA_REL_ "GenSigTimeoutTime" BU_SG_REL_ Motor_EDC17_Pirol SG_ 959 KL_Vorwarn_Komp_ein 1000;
BA_REL_ "GenSigTimeoutTime" BU_SG_REL_ Motor_MED17_Hybrid SG_ 959 KL_Vorwarn_Komp_ein 1000;
BA_REL_ "GenSigTimeoutTime" BU_SG_REL_ BMS_Hybrid SG_ 959 KL_Zustand 1000;
BA_REL_ "GenSigTimeoutTime" BU_SG_REL_ Motor_EDC17_Pirol SG_ 959 KL_Zustand 1000;
BA_REL_ "GenSigTimeoutTime" BU_SG_REL_ Motor_MED17_Hybrid SG_ 959 KL_Zustand 1000;
BA_REL_ "GenSigTimeoutTime" BU_SG_REL_ Motor_EDC17_Pirol SG_ 959 KL_4_Zonen 1000;
BA_REL_ "GenSigTimeoutTime" BU_SG_REL_ Motor_MED17_Hybrid SG_ 959 KL_4_Zonen 1000;
BA_REL_ "GenSigTimeoutTime" BU_SG_REL_ Motor_EDC17_Pirol SG_ 959 KL_Thermomanagement 1000;
BA_REL_ "GenSigTimeoutTime" BU_SG_REL_ Motor_MED17_Hybrid SG_ 959 KL_Thermomanagement 1000;
BA_REL_ "GenSigTimeoutTime" BU_SG_REL_ Motor_EDC17_Pirol SG_ 959 KL_Vorwarn_HHS_ein 1000;
BA_REL_ "GenSigTimeoutTime" BU_SG_REL_ Motor_MED17_Hybrid SG_ 959 KL_Vorwarn_HHS_ein 1000;
BA_REL_ "GenSigTimeoutTime" BU_SG_REL_ Motor_EDC17_Pirol SG_ 959 KL_Vorwarn_HFS_ein 1000;
BA_REL_ "GenSigTimeoutTime" BU_SG_REL_ Motor_MED17_Hybrid SG_ 959 KL_Vorwarn_HFS_ein 1000;
BA_REL_ "GenSigTimeoutTime" BU_SG_REL_ Motor_EDC17_Pirol SG_ 959 KL_StartStopp_Info 1000;
BA_REL_ "GenSigTimeoutTime" BU_SG_REL_ Motor_MED17_Hybrid SG_ 959 KL_StartStopp_Info 1000;
BA_REL_ "GenSigTimeoutTime" BU_SG_REL_ Motor_EDC17_Pirol SG_ 959 KL_Drehz_Anh 1000;
BA_REL_ "GenSigTimeoutTime" BU_SG_REL_ Motor_MED17_Hybrid SG_ 959 KL_Drehz_Anh 1000;
BA_REL_ "GenSigTimeoutTime" BU_SG_REL_ Motor_EDC17_Pirol SG_ 959 KL_Anf_KL 1000;
BA_REL_ "GenSigTimeoutTime" BU_SG_REL_ Motor_MED17_Hybrid SG_ 959 KL_Anf_KL 1000;
BA_REL_ "GenSigTimeoutTime" BU_SG_REL_ Motor_EDC17_Pirol SG_ 959 KL_Last_Kompr 1000;
BA_REL_ "GenSigTimeoutTime" BU_SG_REL_ GW_Routing_Derivate SG_ 2041 Response_Airbag_Deployment 500;
BA_REL_ "GenSigTimeoutTime" BU_SG_REL_ Airbag SG_ 2033 Request_Airbag_Deployment 500;
BA_REL_ "HYB_Tx_Baureihe" BU_BO_REL_ GW_Routing_Derivate 2022 2;
BA_REL_ "HYB_Tx_Baureihe" BU_BO_REL_ GW_Routing_Derivate 2021 2;
BA_REL_ "HYB_Tx_Baureihe" BU_BO_REL_ GW_Routing_Derivate 1720 2;
BA_REL_ "HYB_Tx_Baureihe" BU_BO_REL_ GW_Routing_Derivate 1646 2;
BA_REL_ "HYB_Tx_Baureihe" BU_BO_REL_ GW_Routing_Derivate 1636 2;
BA_REL_ "HYB_Tx_Baureihe" BU_BO_REL_ GW_Routing_Derivate 959 2;
BA_REL_ "HYB_Tx_Baureihe" BU_BO_REL_ GW_Routing_Derivate 2033 2;
VAL_ 1089 GE_OBD_AbsperrVent 0 "kein_Fehler" 12 "frei" 13 "frei" 5 "OOR-" 8 "KS+/OC" 9 "KS-/OC" 10 "KS-/KS+" 15 "frei" 3 "OC" 4 "OOR+" 6 "RC+" 7 "RC-" 11 "KS-/KS+/OC" 2 "KS+" 14 "frei" 1 "KS-" ;
VAL_ 1089 GE_Freigabe_Verfallsinfo_WFS 0 "aus" 1 "ein" ;
VAL_ 1089 GE_Index_Fahrwid 255 "Fehler" ;
VAL_ 1089 GE_Heizwunsch 0 "maximaler_Waermebedarf" 1 "kein_Waermebedarf" 2 "Kuehlbedarf" 3 "Notfall_(maximaler_Kuehlbedarf)" ;
VAL_ 1089 GE_OBD_Status 0 "MIL aus" 1 "MIL ein" ;
VAL_ 1089 GE_LFR_Adaption 0 "fuer_Adaption_geeignet" 1 "fuer_Adaption_nicht_geeignet" ;
VAL_ 1089 GE_Grenzkriechmoment 62 "Init" 63 "Fehler" ;
VAL_ 1089 GE_Charisma_FahrPr 1 "Programm_1" 2 "Programm_2" 3 "Programm_3" 4 "Programm_4" 5 "Programm_5" 6 "Programm_6" 7 "Programm_7" 0 "nicht_belegt" ;
VAL_ 1089 GE_Charisma_Status 0 "Init" 1 "verfuegbar" 2 "nicht_verfuegbar" 3 "asynchron_durch_Fahrerwunsch" ;
VAL_ 1089 GE_Charisma_Umschaltung 0 "Idle" 1 "Erkennung_Umschaltaufforderung" 2 "Steuerbotschaft_nicht_definiert" 3 "Umschaltung_verzoegert" ;
VAL_ 1089 GE_Verlustmoment 255 "Fehler" ;
VAL_ 1089 GE_amax_moeglich 511 "Wert ist nicht definiert" ;
VAL_ 1089 GE_Sumpftemperatur 255 "Fehler" ;
VAL_ 158 GE_HYB_Fehlerstatus 0 "kein_Fehler" 1 "kein_Hydraulikdruck" 2 "Anforderung_N_gleich_0" 3 "beide_Fehler" ;
VAL_ 158 GE_HYB_Freigabe_K0 0 "Freigabe_K0_oeffnen" 1 "Freigabe_K0_schliessen" ;
VAL_ 158 GE_HYB_Freigabe_LL_Reg 0 "keine_DZ_reg_erlaubt" 1 "LL_Reg_freigegeben" ;
VAL_ 158 GE_HYB_Freig_sSchl_K0 0 "keine_Anf_Schliessen_K0" 1 "Anf_Schliessen_K0" ;
VAL_ 158 GE_HYB_Freig_VM_EM_Stop 0 "VM_EM_darf_nicht_stoppen" 1 "VM_EM_darf_stoppen" ;
VAL_ 158 GE_HYB_Wiederstart 0 "kein_Wiederstart_aktiv" 1 "Wiederstart_aktiv" ;
VAL_ 158 GE_HYB_nK0 255 "Fehler" ;
VAL_ 158 GE_HYB_VZ_MomEingriff_EM 0 "positiv" 1 "negativ" ;
VAL_ 158 GE_HYB_Sportfaktor 0 "nicht_sportlich" ;
VAL_ 158 GE_HYB_VM_akt_halten 0 "keine_Empfehlung" 1 "VM_aktiv_halten_starten" ;
VAL_ 158 GE_HYB_StartAnf 0 "keine_Startanforderung" 1 "Startanforderung" ;
VAL_ 158 GE_HYB_VM_Startkontr 0 "VM_StartAnf_nicht_freigegeben" 1 "VM_StartAnf_freigegeben" ;
VAL_ 158 GE_HYB_Filt_MomAufbau 0 "keine_Beeinflussung_der_Filterung_durch_Getriebe" 7 "multiplikative_Konstante_fuer_MSG" 6 "multiplikative_Konstante_fuer_MSG" 4 "multiplikative_Konstante_fuer_MSG" 2 "multiplikative_Konstante_fuer_MSG" 1 "multiplikative_Konstante_fuer_MSG" 5 "multiplikative_Konstante_fuer_MSG" 3 "multiplikative_Konstante_fuer_MSG" ;
VAL_ 1720 KBI_Tankfuellstand_Prozent 127 "Fehler" ;
VAL_ 1720 KBI_Tankinhalt_hochaufl 16382 "Init" 16383 "Fehler" ;
VAL_ 1720 KBI_Nachtanken_erkannt 0 "Geberbetrieb" 1 "Nachtankmodus" ;
VAL_ 128 MO_Mom_o_ex 1022 "Init" 1023 "Fehler" ;
VAL_ 128 MO_Mom_m_ex 1022 "Init" 1023 "Fehler" ;
VAL_ 128 MO_Mom_Verlust 1022 "Init" 1023 "Fehler" ;
VAL_ 128 MO_Mom_Begrenzung 1022 "Init" 1023 "Fehler" ;
VAL_ 128 MO_Mom_Fahrerwunsch 1022 "Init" 1023 "Fehler" ;
VAL_ 128 MO_Kickdown 0 "kein Kickdown" 1 "Kickdown" ;
VAL_ 128 MO_KD_Fehler 1 "mind. ein KD-Fehler vorhanden" 0 "kein KD-Fehler" ;
VAL_ 129 MO_StartStopp_Wiederstart 1 "Wiederstart_aktiv" 0 "Wiederstart_inaktiv" ;
VAL_ 129 MO_StartStopp_Status 3 "Mindestens ein weiches oder hartes Veto liegt vor" 2 "Alle Vetos besagen,dass langfristig kein Motorlauf notwendig ist" 1 "Reversible Abschaltung aufgrund sicherheitsrelevanter Funktionen oder über einen Taster" 0 "Fehlerstatus erkannt oder Sicherheitsabschaltung aktiv" ;
VAL_ 129 MO_StartStopp_Motorstopp 1 "Motor_Stop_aktiv" 0 "Motor_Stop_inaktiv" ;
VAL_ 129 MO_StartStopp_Fahrerwunsch 0 "Init" 1 "Stoppverbot_durch_Fahrer" 2 "Stoppfreigabe_durch_Fahrer" 3 "Stoppanforderung_durch_Fahrer" ;
VAL_ 129 MO_Mom_ZWR 1022 "Init" 1023 "Fehler" ;
VAL_ 129 MO_Mom_Soll 1022 "Init" 1023 "Fehler" ;
VAL_ 129 MO_Mom_Ist 1022 "Init" 1023 "Fehler" ;
VAL_ 129 MO_Status_Zylabschalt_01 0 "alle Zylinder brennen" 1 "mindestens ein Zylinder wurde abgeschaltet" ;
VAL_ 129 MO_Status_Normalbetrieb_01 0 "kein Normalbetrieb" 1 "Normalbetrieb erreicht" ;
VAL_ 129 MO_Gangposition 14 "Istgang_nicht_definiert" 5 "Gang_5" 1 "Gang_1" 2 "Gang_2" 7 "Gang_7" 3 "Gang_3" 6 "Gang_6" 4 "Gang_4" 8 "Gang_8" 0 "Gang_N" 12 "Zwischengangstellung" 13 "Gang_R" 15 "Fehler" ;
VAL_ 129 MO_Ext_E_Fahrt_aktiv 1 "Rueckmeldung_E_Taster_ein" 0 "Rueckmeldung_E_Taster_aus" ;
VAL_ 261 MO_QBit_Motormomente 0 "gueltiger_Wert" 1 "Ersatz_Init_oder_Fehlerwert" ;
VAL_ 261 MO_QBit_Fahrpedalwerte_01 0 "gueltiger_Wert" 1 "Ersatz_Init_oder_Fehlerwert" ;
VAL_ 261 MO_QBit_Fahrer_bremst 0 "gueltiger_Wert" 1 "Ersatz_Init_oder_Fehlerwert" ;
VAL_ 261 MO_QBit_Drehzahl_01 0 "gueltiger_Wert" 1 "Ersatz_Init_oder_Fehlerwert" ;
VAL_ 261 MO_Drehzahl_01 65535 "Fehler" ;
VAL_ 261 MO_Moment_im_Leerlauf 0 "kein_Leergas" 1 "Leergas" ;
VAL_ 261 MO_Interlock 0 "Interlockschalter nicht betätigt" 1 "Interlockschalter betätigt" ;
VAL_ 261 MO_BLS 0 "kein Bremsen" 1 "Bremse betätigt" ;
VAL_ 261 MO_Fahrer_bremst 0 "kein Bremsen" 1 "Bremse betätigt" ;
VAL_ 261 MO_Konsistenz_Bremsped 0 "Bremspedalinformation_plausibel" 1 "Bremspedalinformation_unplausibel" ;
VAL_ 261 MO_Kuppl_schalter 0 "Schalter sagt betätigt (Ausgekuppelt)" 1 "Schalter sagt nicht betätigt (Eingekuppelt)" ;
VAL_ 261 MO_Timeout_ESP 0 "Empfang i.O." 1 "Timeout" ;
VAL_ 261 MO_Motor_laeuft 0 "Motor läuft nicht" 1 "Motor läuft autark und stabil und darf mechanisch belastet werden" ;
VAL_ 261 MO_Solldrehz_Leerlauf 255 "Fehler" ;
VAL_ 261 MO_Fahrpedalrohwert_01 255 "Fehler" ;
VAL_ 261 MO_erste_Ungenauschwelle 0 "genau" 1 "Momente ungenauer >8%" ;
VAL_ 261 MO_QBit_Stressfaktor 0 "gueltiger_Wert" 1 "Ersatz_Init_oder_Fehlerwert" ;
VAL_ 263 MO_Anzeigedrehz 4095 "Fehler" ;
VAL_ 263 MO_KVS_Ueberlauf 0 "kein Ueberlauf" 1 "Kraftstoffverbrauchsignale mindestens 1x übergelaufen" ;
VAL_ 263 MO_Ladedruck 511 "Fehler" ;
VAL_ 263 MO_Oeldruck_HYB 255 "Fehler" ;
VAL_ 263 MO_Istgang 0 "kein Gang eingelegt" 1 "1.Gang" 2 "2.Gang" 3 "3.Gang" 4 "4.Gang" 5 "5.Gang" 6 "6.Gang" ;
VAL_ 263 MO_Schaltempf_verfbar 0 "nicht verfügbar" 1 "verfügbar" ;
VAL_ 263 MO_Sollgang 0 "keine Empfehlung" 1 "1.Gang" 2 "2.Gang" 3 "3.Gang" 4 "4.Gang" 5 "5.Gang" 6 "6.Gang" ;
VAL_ 782 MO_Handshake_STH 0 "keine EKP-Ansteuerung durch STH-Anforderung" 1 "EKP-Ansteuerung durch STH-Anforderung" ;
VAL_ 782 MO_EKlKomLeiRed 0 "keine_Leistungsbegr" 1 "Leistungsbegr_75" 2 "Leistungsbegr_50" 3 "Leistungsbegr_25" ;
VAL_ 782 MO_Freig_Reku 0 "Rekuperations-Modus aus" 1 "Empfehlung Spannungsanhebung" 2 "Empfehlung Spannungsabsenkung" 3 "Rekuperationsmodus aktiv, Spannungsvariation nicht notwendig" ;
VAL_ 782 MO_Klima_Eingr 0 "kein Eingriff" 1 "Klimakompressor ausschalten" 2 "Klimakompressor Leistungsreduzierung" 3 "Klimakompressor aufgrund der Heissleuchtenvorwarnung ausschalten" ;
VAL_ 782 MO_Status_Normalbetrieb_02 0 "kein Normalbetrieb" 1 "Normalbetrieb erreicht" ;
VAL_ 782 MO_Prio_MIN_Wunschdrehzahl 0 "Wunsch" 1 "Zwang" ;
VAL_ 782 MO_Freig_Anlass 0 "Start nicht zulässig" 1 "Startfreigabe" ;
VAL_ 782 MO_Aussp_Anlass 0 "Motor läuft nicht stabil" 1 "Anlasser ausspuren (Motor läuft stabil)" ;
VAL_ 782 MO_MAX_Wunschdrehzahl 511 "Fehler" ;
VAL_ 782 MO_Prio_MAX_Wunschdrehzahl 0 "Wunsch" 1 "Zwang" ;
VAL_ 782 MO_Luftpfad_aktiv 0 "kein Eingriff oder nur Eingriff über Zündpfad" 1 "Eingriff über Luftpfad" ;
VAL_ 782 MO_v_Begrenz_Aktiv 0 "inaktiv" 1 "aktiv" ;
VAL_ 782 MO_v_Begrenz_Aktivierbar 0 "V-Begrenzung nicht möglich" 1 "V-Begrenzung möglich" ;
VAL_ 782 MO_Verbot_EKP 0 "Ansteuerung zugelassen" 1 "Ansteuerung verboten" ;
VAL_ 782 MO_Anf_Pruefimpuls 0 "keine Anforderung" 1 "Anforderung" ;
VAL_ 782 MO_Anf_KL75 0 "Anforderung KL75 ausschalten" 1 "Anforderung KL75 einschalten" ;
VAL_ 782 MO_Charisma_FahrPr 0 "nicht_belegt" 1 "Programm_1" 2 "Programm_2" 3 "Programm_3" 4 "Programm_4" 5 "Programm_5" 6 "Programm_6" 7 "Programm_7" ;
VAL_ 782 MO_Charisma_Status 0 "Init" 1 "verfuegbar" 2 "nicht_verfuegbar" 3 "asynchron_durch_Fahrerwunsch" ;
VAL_ 782 MO_Charisma_Umschaltung 0 "Idle" 1 "Erkennung_Umschaltaufforderung" 2 "Steuerbotschaft_nicht_definiert" 3 "Umschaltung_verzoegert" ;
VAL_ 782 MO_MIN_Wunschdrehzahl 255 "Fehler" ;
VAL_ 1088 MO_Kat_Warnung 0 "Lampe_aus" 1 "Lampe_ein" ;
VAL_ 1088 MO_ITM_Warnung_Pumpe 0 "keine_Warnung" 1 "ITM_Warnung" ;
VAL_ 1088 MO_HYB_Text_4 0 "kein_Text" 1 "Text_anzeigen" ;
VAL_ 1088 MO_HYB_Status_HV_Ladung 0 "HV-Ladung_nicht_notwendig" 1 "HV-Ladung_notwendig_Freigaben_erforderlich" 2 "HV-Ladung laeuf" 3 "HV-Ladung_erfolgreich_Motorstart_moeglich" 4 "HV_Ladung_abgebrochen" ;
VAL_ 1088 MO_Zustand_HWP 2 "HWP_fördert" 0 "HWP_nicht_schaltbar" 1 "HWP_fördert_nicht" 3 "reserviert" ;
VAL_ 1088 MO_Kuehlerluefter_MUX 0 "Kuehlerluefter_1" 1 "Kuehlerluefter_2" ;
VAL_ 1088 MO_Kuehlerluefter_1 126 "Init" 127 "Fehler" ;
VAL_ 1088 MO_Kuehlerluefter_2 126 "Init" 127 "Fehler" ;
VAL_ 1088 WIV_Anzeige_aktiv 0 "Anzeige aus" 1 "WIV Anzeige aktiv" ;
VAL_ 1088 WIV_Oelmin_Warn 0 "in_Ordnung" 1 "Warnung" ;
VAL_ 1088 WIV_Sensorfehler 0 "in_Ordnung" 1 "Sensor_defekt" ;
VAL_ 1088 WIV_Schieflage 0 "Fahrzeug_gerade" 1 "Fahrzeug_in_Schieflage" ;
VAL_ 1088 WIV_Oelsystem_aktiv 0 "Anzeige_aus" 1 "Anzeige_aktiv" ;
VAL_ 1088 WIV_nicht_betriebswarm 0 "Motor_warm" 1 "Motor_nicht_betriebswarm" ;
VAL_ 1088 WIV_Ueberfuell_Warn 0 "in_Ordnung" 1 "Ueberfuellwarnung" ;
VAL_ 1088 WIV_laufender_Motor 0 "Messung_moeglich" 1 "Messung_nicht_moeglich" ;
VAL_ 1088 MO_Text_Motorstart 11 "(Belegt bei VW/Audi)" 10 "(Belegt bei VW/Audi)" 9 "(Belegt bei VW/Audi)" 8 "(Vorhalt für Start/Stopp) " 7 "(Vorhalt für Start/Stopp) " 6 "(Vorhalt für Start/Stopp) " 5 "Start/Stopp temporär nicht verfügbar" 4 "Nicht belegt (Vorhalt AUDI)" 15 "Bremse treten" 14 "Waehlhebel in PN Position" 13 "Kupplung betaetigt" 12 "Motor startet" 3 "System fordert Wiederstart" 2 "StartStopp sicherheitsbedingt deaktiviert" 1 "Motor im Stoppbetrieb" 0 "keine Anzeige" ;
VAL_ 1088 MO_Systemlampe 0 "Lampe aus" 1 "Lampe ein" ;
VAL_ 1088 MO_OBD2_Lampe 0 "Lampe aus" 1 "Lampe ein" ;
VAL_ 1088 MO_Heissleuchte 0 "Lampe aus" 1 "Lampe ein" ;
VAL_ 1088 MO_Partikel_Lampe 0 "Lampe aus" 1 "Lampe ein" ;
VAL_ 1088 WIV_Oelstand_nicht_vorhanden 0 "Ölstand vorhanden" 1 "Ölstand nicht vorhanden" ;
VAL_ 1088 WIV_nachfuellanzeige_ein 0 "keine_Nachfuellanzeige" 1 "Nachfuellanzeige" ;
VAL_ 1088 WIV_Ueberfuell_deaktiv 0 "Ueberfuellwarnung_am_Kombi_aktiv" 1 "Ueberfuellwarnung_am_Kombi_deaktiv" ;
VAL_ 1088 WIV_Unterfuell_Warn 0 "in_Ordnung" 1 "Unterfuellwarnung" ;
VAL_ 1088 MO_Tankdeckel_Lampe 0 "Lampe aus" 1 "Lampe ein" ;
VAL_ 1088 MO_Text_Tankdeckelwarn 0 "kein Text" 1 "Anzeige Text Tankdeckelwarnung im Kombi" ;
VAL_ 1088 WIV_Enable_Oeldr_Motor 0 "Oeldruckauswertung_im_Kombi" 1 "Oeldruckauswertung_im_MSG" ;
VAL_ 1088 WIV_Oeldr_Warn_Motor 0 "keine_Warnung" 1 "niedrige_Oeldruckstufe_nicht_erreicht " ;
VAL_ 1088 MO_Avus_Motorschutz 0 "keine Warnung" 1 "Drehzahlwarnung Stufe 1" 2 "Drehzahlwarnung Stufe 2" 3 "Drehzahlwarnung Stufe 3" ;
VAL_ 1088 MO_HYB_Fahrbereitschaft 0 "keine_Fahrbereitschaft" 1 "Fahrbereitschaft" ;
VAL_ 1088 WIV_Oeldyn_avl 0 "Oeldyn_nicht_vorhanden" 1 "Oeldyn_vorhanden" ;
VAL_ 1088 MO_HYB_Text_7 0 "kein_Text" 1 "Text_anzeigen" ;
VAL_ 1088 MO_HYB_Text_6 1 "Text_anzeigen" 0 "kein_Text" ;
VAL_ 1088 MO_HYB_Text_5 1 "Text_anzeigen" 0 "kein_Text" ;
VAL_ 1088 MO_HYB_Text_3 0 "kein_Text" 1 "Text_anzeigen" ;
VAL_ 1088 MO_HYB_Text_2 0 "kein_Text" 1 "Text_anzeigen" ;
VAL_ 1088 MO_HYB_Text_1 1 "Text_anzeigen" 0 "kein_Text" ;
VAL_ 1600 MO_Kennfeldk 0 "keine Kennfeldkühlung vorhanden" 1 "Kennfeldkühlung vorhanden" ;
VAL_ 1600 MO_QBit_Ansaugluft_Temp 0 "gueltiger_Wert" 1 "Ersatz_Init_oder_Fehlerwert" ;
VAL_ 1600 MO_QBit_Oel_Temp 0 "gueltiger_Wert" 1 "Ersatz_Init_oder_Fehlerwert" ;
VAL_ 1600 MO_QBit_Kuehlmittel_Temp 0 "gueltiger_Wert" 1 "Ersatz_Init_oder_Fehlerwert" ;
VAL_ 1600 MO_Stellgliedtest_Soundaktuator 0 "kein_Stellgliedtest" 1 "Anforderung_des_Stellgliedtest" ;
VAL_ 1600 MO_HYB_Fehler_HV_Netz 0 "i_O" 1 "kein_generatorischer_Betrieb_moeglich" ;
VAL_ 1600 MO_Absperrventil_oeffnen 0 "nicht_verfuegbar" 1 "Ansteuerung_Ventil_zulaessig" 2 "Ventil_oeffnen_oder_geoeffnet" 3 "Ventil_schliessen_oder_geschlossen" ;
VAL_ 1600 MO_Ansaugluft_Temp 254 "Init" 255 "Fehler" ;
VAL_ 1600 MO_Oel_Temp 253 "nicht_verbaut" 254 "Init" 255 "Fehler" ;
VAL_ 1600 MO_Kuehlmittel_Temp 254 "Init" 255 "Fehler" ;
VAL_ 1600 MO_Hoeheninfo 255 "Fehler" ;
VAL_ 1600 MO_Versionsinfo 0 "zum Projektbeginn 'aufgeräumter CAN' " 1 "Motor_03_mit_10ms" 16 "MQB_mit_neuer_Momentenschnittstelle" ;
VAL_ 1600 MO_Getriebe_kuehlen 0 "nicht_kuehlen" 1 "kuehlen" ;
VAL_ 1600 MO_Heizungspumpenansteuerung 15 "nicht_verbaut" ;
VAL_ 1600 MO_SpannungsAnf 0 "keine_Anforderung" 1 "Anforderung" ;
VAL_ 1600 MO_aktives_Getriebeheizen 0 "kein_Ventil_ansteuern" 1 "Ventil_muss_angesteuert_werden" ;
VAL_ 1601 MO_Kraftstoffart 4 "Wasserstoff" 3 "Erdgas" 2 "CNG" 1 "Benzin" 0 "Diesel" ;
VAL_ 1601 MO_Faktor_Momente 0 "nicht belegt" 1 "Faktor: x 0,5Nm" 2 "Faktor: x 1,0Nm" 3 "Faktor: x 2,0Nm" ;
VAL_ 1601 MO_Hybridfahrzeug 3 "PlugIn_Hybrid" 2 "Full_Hybrid" 1 "Mild_Hybrid" 0 "kein_Hybridfahrzeug" ;
VAL_ 1601 MO_Getriebe_Code 2 "DL501" 4 "VL381" 10 "AL651" 11 "AL551, AL951, AL1000-8A" 12 "PDK_PAG" 13 "AL551_Hybrid" 15 "Handschalter (konventionell)" 16 "AQ250" 17 "AQ450" 18 "DQ200" 19 "DQ250" 20 "DQ500" 21 "SQ100" 22 "SQ200" ;
VAL_ 1601 MO_Ansaugsystem 0 "Turbo" 1 "Sauger" ;
VAL_ 1601 MO_Einspritzart 0 "MPI" 1 " FSI / TDI" ;
VAL_ 1601 MO_StartStopp_Codiert 1 "StartStopp vorhanden/verbaut" 0 "StartStopp nicht vorhanden/verbaut" ;
VAL_ 157 MO_HYB_EMode_Info 0 "Normal_Mode" 1 "Depleting_Mode" 2 "Charge_Mode" 3 "Sonder_Schaltprogramm" ;
VAL_ 157 MO_HYB_IstStatusK0 3 "Fehler" 2 "zu" 1 "Uebergang" 0 "auf" ;
VAL_ 157 MO_HYB_max_ind_VM_Mom 1022 "Init" 1023 "Fehler" ;
VAL_ 157 MO_HYB_Zielzustand 0 "Init" 1 "Leerlauf_VM" 2 "hybridisch_Fahren" 3 "Fahren_EM" 4 "Fahrbereitschaft_EM" 5 "Fahrbereitschaft_VM" 7 "Fehler" ;
VAL_ 157 MO_HYB_Startmodus 0 "Drag_Start" 1 "slip_start_comf" 2 "slip_start_trq" 3 "slip_start_pwr" 4 "anger_comf" 5 "anger_trq" 6 "anger_pwr" 7 "Impulsstart" ;
VAL_ 157 MO_HYB_Startmodus_PQ3x 0 "Impulsstart" 1 "Direktstart" ;
VAL_ 157 MO_HYB_Stoppmodus 0 "Softstopp" 1 "Dynamikstopp" ;
VAL_ 157 MO_HYB_VM_Mom_oE 1023 "Fehler" ;
VAL_ 157 MO_HYB_VM_aktiv 0 "VM_nicht_aktiv" 1 "VM_aktiv" ;
VAL_ 157 MO_HYB_Schaltverhinderung 0 "keine_Schaltverhinderung" 1 "Schaltverhinderung" ;
VAL_ 157 MO_HYB_Selektor_Momverlauf_EM 0 "keine_Werte" 1 "max_Rekup_Moment" 2 "KnickDZ_Rekup_Kurve" 3 "max_pos_EM_Moment" 4 "KnickDZ_EM_Kurve" ;
VAL_ 811 MO_FahrPr7_verfuegbar 0 "Fahrprogramm_nicht_verfuegbar" 1 "Fahrprogramm_verfuegbar" ;
VAL_ 811 MO_FahrPr6_verfuegbar 0 "Fahrprogramm_nicht_verfuegbar" 1 "Fahrprogramm_verfuegbar" ;
VAL_ 811 MO_FahrPr5_verfuegbar 0 "Fahrprogramm_nicht_verfuegbar" 1 "Fahrprogramm_verfuegbar" ;
VAL_ 811 MO_FahrPr4_verfuegbar 0 "Fahrprogramm_nicht_verfuegbar" 1 "Fahrprogramm_verfuegbar" ;
VAL_ 811 MO_FahrPr3_verfuegbar 0 "Fahrprogramm_nicht_verfuegbar" 1 "Fahrprogramm_verfuegbar" ;
VAL_ 811 MO_FahrPr2_verfuegbar 0 "Fahrprogramm_nicht_verfuegbar" 1 "Fahrprogramm_verfuegbar" ;
VAL_ 811 MO_FahrPr1_verfuegbar 0 "Fahrprogramm_nicht_verfuegbar" 1 "Fahrprogramm_verfuegbar" ;
VAL_ 811 MO_HYB_E_Faktor 0 "null" 1 "plus_1" 2 "plus_2" 3 "plus_3" 4 "plus_4" 5 "plus_5" 6 "plus_6" 7 "plus_7" 8 "minus_8" 9 "minus_7" 10 "minus_6" 11 "minus_5" 12 "minus_4" 13 "minus_3" 14 "minus_2" 15 "minus_1" ;
VAL_ 811 MO_HYB_Drehzahl_VM 65280 "Fehler" ;
VAL_ 811 MO_HYB_LowSpeedModus 0 "LowSpeed_mit_LLDZ" 1 "LowSpeed_ohne_LLDZ" ;
VAL_ 933 MO_Overboost 0 "inaktiv" 1 "aktiv" ;
VAL_ 933 Enrgfluss_State 1 "no_torques" 2 "pos_tor_EE" 3 "pos_tor_ICE" 4 "pos_tor_ICE_bat_charge" 5 "pos_tor_EE_ICE" 6 "neg_tor_EE_bar_charge" 7 "neg_tor_EE_bat_discharge" 8 "neg_tor_EE" 9 "ICE_charge_bat" 10 "neg_tor_EE_and_ICE" 11 "no_tor_sailing" 12 "no_tor_sailing_and_ICE" 255 "Fehler" ;
VAL_ 933 Ladezustand 255 "Fehler" ;
VAL_ 933 Energiefluss 255 "Fehler" ;
VAL_ 933 Enrgrueckfluss 255 "Fehler" ;
VAL_ 933 MO_Temp_MotRaum 63 "Fehler" ;
VAL_ 933 MO_Oel_Temp_Radsatz 255 "Fehler" ;
VAL_ 933 MO_Anf_Abgasklappe 0 "nicht angesteuert" 1 "angesteuert" ;
VAL_ 933 MO_LED_Abgasklappe 0 "LED aus" 1 "LED ein" ;
VAL_ 933 MO_Hoch_Anz_Nmax 0 "inaktiv" 1 "aktiv" ;
VAL_ 933 MO_Hoch_Anz_Eco 0 "inaktiv" 1 "aktiv" ;
VAL_ 933 MO_Fehler_MSpG 0 "i.O." 1 "Gebläse defekt oder Motorraumtemp. zu hoch" ;
VAL_ 1730 NMH_GE_N_Haltephase 1 "N_Haltephase_aktiv" 0 "keine_N_Haltephase" ;
VAL_ 1729 NMH_MO_NM_aktiv_HV_Abschaltung 1 "Abschaltung_aktiv" 0 "kein_Nachlauf" ;
VAL_ 913 OBD_Driving_Cycle 0 "kein Driving Cycle erkannt" 1 "DC erkannt" ;
VAL_ 913 OBD_Warm_Up_Cycle 0 "kein Warm Up Cycle erkannt" 1 "Warm Up Cycle erkannt" ;
VAL_ 913 OBD_Normed_Trip 0 "kein Normed Trip" 1 "Normed Trip erfüllt" ;
VAL_ 913 OBD_Sperrung_IUMPR 0 "IUMPR_Berechnung_freigegeben" 1 "IUMPR_Berechnung_gesperrt" ;
VAL_ 913 OBD_Kaltstart_Denominator 0 "Denominator_nicht_hochzaehlen" 1 "Bedingungen_zum_Inkr_des_Kaltstart_Denom_erf" ;
VAL_ 913 OBD_Minimum_Trip 0 "kein_Min_Normed_Trip" 1 "Min_Normed_Trip" ;
VAL_ 270 TSK_ax_Getriebe 511 "nicht definiert" ;
VAL_ 270 TSK_Freig_WU 0 "TSK_Uebersetzungswunsch nicht freigegeben" 1 "TSK_Uebersetzungswunsch freigegeben" ;
VAL_ 270 TSK_Limiter_aktiv 0 "Speed Limiter ist nicht aktiv" 1 "Speed Limiter aktiv und regelt" ;
VAL_ 270 TSK_Status_GRA_ACC_02 0 "nicht verbaut / kein ACC zulässig" 1 "GRA / ACC aktiv " 2 "GRA / ACC vom Fahrer übersteuert" 3 "Fehler, GRA/ACC nicht möglich " ;
VAL_ 273 TSK_Fahrzeugmasse_02 255 "Fehler" ;
VAL_ 273 TSK_QBit_Steigung 0 "gueltiger_Wert" 1 "Ersatz_Init_oder_Fehlerwert" ;
VAL_ 273 TSK_Status_GRA_ACC_01 0 "nicht_verbaut_kein_ACC_zulaessig" 1 "GRA_ACC_aktiv" 2 "GRA_ACC_vom_Fahrer_uebersteuert" 3 "Fehler_GRA_ACC_nicht_moeglich" ;
VAL_ 273 TSK_Fahrzeugmasse 31 "Fehler" ;
VAL_ 273 TSK_QBit_Fahrzeugmasse 0 "gueltiger_Wert" 1 "Ersatz_Init_oder_Fehlerwert" ;
VAL_ 273 TSK_Steigung 255 "Fehler" ;
VAL_ 273 TSK_Getriebeinfo 0 "Handschalter" 1 "AL_AQ_Getriebe" 2 "DL_DQ_Getriebe" 3 "CVT_Getriebe" ;
VAL_ 273 TSK_Codierung_ACC 0 "TSK_korrekt_auf_kein_ACC_codiert_oder_TSK_falsch_codiert" 1 "TSK_korrekt_auf_ACC_codiert" ;
VAL_ 273 TSK_Zwangszusch_ESP 0 "keine_ESP_ASR_Beeinflussung" 1 "ESP_ASR_Beeinflussung" ;
VAL_ 273 TSK_Freig_Verzoeg_Anf 0 "Verzoegerungsanforderung_nicht_freigegeben" 1 "Verzoegerungsanforderung_freigegeben" ;
VAL_ 915 WBA_GE_Zusatzwarnungen 0 "keine_Anzeige" 1 "Getriebeueberhitzung_Warnstufe_I" 2 "Getriebeueberhitzung_Warnstufe_II" 3 "Getriebefehler_Bitte_anhalten_und_P_einlegen" ;
VAL_ 915 WBA_Effizienzmodus 0 "nicht_im_Effizienz_Modus" 1 "Effizienz_Modus" ;
VAL_ 915 WBA_Istgang 0 "kein Gang eingelegt" 1 "1.Gang" 2 "2.Gang" 3 "3.Gang" 4 "4.Gang" 5 "5.Gang" 6 "6.Gang" ;
VAL_ 915 WBA_GE_Texte 4 "Achtung_Zeitueberschreitung_P_wird_eingelegt" 3 "Wegrollgefahr_bitte_P_einlegen" 2 "zum_Einlegen_von_R,N,D_Fussbremse_betaetigen_und_Motor_starten" 1 "zum_Einlegen_einer_Fahrstufe_Fussbremse_betaetigen__ShiftLock_Information" 0 "keine Anzeige" ;
VAL_ 915 WBA_Schaltschema_Aktiv 1 "Schaltschema_anzeigen" 0 "keine_Anzeige" ;
VAL_ 915 WH_Warnung 1 "Waehlhebelfehler_Fahrstufenwechsel_moeglich_(gelbes_Getriebesymbol)" 0 "keine_Anzeige" ;
VAL_ 915 WBA_Sollgang 0 "keine Empfehlung" 1 "1.Gang" 2 "2.Gang" 3 "3.Gang" 4 "4.Gang" 5 "5.Gang" 6 "6.Gang" ;
VAL_ 915 WBA_Senderkennung 1 "Motor" 0 "Getriebe" ;
VAL_ 915 WBA_Lampe_Shift_Lock 1 "SL_Lampe_ein" 0 "SL_Lampe_aus" ;
VAL_ 915 WBA_Blinken 1 "WBA_Blinken" 0 "kein_WBA_Blinken" ;
VAL_ 915 WBA_Getriebevariante 15 "9 Gang Automat Tiptronic" 14 "8 Gang Automat Tiptronic" 13 "7 Gang Automat Tiptronic" 12 "6 Gang Automat Tiptronic" 11 "5 Gang Automat Tiptronic" 10 "tbd." 9 "tbd." 8 "2x3 shift_by_wire" 7 "tbd." 6 "Automat PRNDS" 5 "tbd." 4 "Vorhalt für ASG (Selespeed)" 3 "tbd." 2 "tbd." 1 "Automat PRND" ;
VAL_ 915 WBA_GE_Warnung 7 "Kupplung ueberhitzt, Fahrzeug Stopp (+ rotes Getriebefehlersymbol)" 6 "Kupplung ueberhitzt, Fahrzeug Stopp (+ gelbes Getriebefehlersymbol)" 5 "Wegrollgefahr! P nicht möglich" 4 "Getriebefehler, Weiterfahrt nur in D moeglich, P bei Motor aus" 3 "nur DL-Getriebe: Weiterfahrt nur eingeschränkt möglich. Kein R-Gang" 2 "Weiterfahrt nur eingeschränkt möglich (+ gelbes Getriebefehlersymbol)" 1 "Weiterfahrt möglich (+ gelbes Getriebefehlersymbol)" 0 "keine Anzeige" ;
VAL_ 915 WBA_Schaltempf_verfbar 0 "nicht verfügbar" 1 "verfügbar" ;
VAL_ 915 WBA_eing_Gang 10 "9.Gang" 9 "8.Gang" 8 "7.Gang" 7 "6.Gang" 6 "5.Gang" 5 "4.Gang" 4 "3.Gang" 3 "2.Gang" 2 "1.Gang" 1 "Init" 0 "kein Gang eingelegt / kein Gang empfohlen" ;
VAL_ 1602 WIV_Verschleissindex 65535 "Fehler" ;
VAL_ 1602 WIV_Russindex 65535 "Fehler" ;
VAL_ 1646 KL_STL_aktiv 1 "Aktiv" 0 "Inaktiv" ;
VAL_ 1646 KL_STH_Ansteuerung 3 "Heizleistung reduziert" 2 "Ein mit Motorvorwaermung" 1 "Ein" 0 "Aus" ;
VAL_ 1646 KL_STH_aktiv 1 "Aktiv" 0 "Inaktiv" ;
VAL_ 1646 KL_Magnetventil 1 "Wasserventil geschlossen" 0 "Wasserventil geoeffnet" ;
VAL_ 1646 KL_AussenTemp_WK 253 "nicht verbaut" 254 "Init Wert, nicht verfuegbar" 255 "Fehler" ;
VAL_ 1646 KL_MSG_valid 1 "Message valid" 0 "Message not valid" ;
VAL_ 1646 KL_Solarluefter_aktiv 1 "Aktiv" 0 "Inaktiv" ;
VAL_ 1636 KL_I_Geblaese 255 "Fehler" ;
VAL_ 1636 KL_Beschlagsgefahr 0 "keine_Beschlagsgefahr" 1 "Beschlagsgefahr" ;
VAL_ 1636 KL_Umluftklappe_Status 2 "Teilumluft 20%" 5 "Teilumluft 50%" 7 "Teilumluft 70%" 9 "Teilumluft 90% " 0 "Frischluft" 4 "Teilumluft 40%" 1 "Teilumluft 10%" 10 "Umluft" 6 "Teilumluft 60%" 8 "Teilumluft 80%" 3 "Teilumluft 30%" 15 "Fehler" ;
VAL_ 1636 KL_HSH_Taktung 1 "Aktiv" 0 "Inaktiv" ;
VAL_ 1636 KL_Zuheizer_Freigabe 1 "Zuheizerfreigabe" 0 "keine Freigabe Zuheizer" ;
VAL_ 1636 KL_Geblaese_Status 15 "Fehler" 14 "Init" 10 "Geblaese Stufe 100%" 9 "Geblaese Stufe 90%" 8 "Geblaese Stufe 80%" 7 "Geblaese Stufe 70%" 6 "Geblaese Stufe 60%" 5 "Geblaese Stufe 50%" 4 "Geblaese Stufe 40%" 3 "Geblaese Stufe 30%" 2 "Geblaese Stufe 20%" 1 "Geblaese Stufe 10%" 0 "Geblaese aus" ;
VAL_ 959 KL_Zustand 1 "ein" 0 "aus" ;
VAL_ 959 KL_4_Zonen 1 "4_Zonen_Klimaanlage" 0 "2_Zonen_Klimaanlage" ;
VAL_ 959 KL_Thermomanagement 3 "volle Freigabe TMM (kein Heizbedarf)" 2 "mittlere Freigabe TMM" 1 "kleine Freigabe TMM" 0 "keine Freigabe TMM (max. Heizbedarf)" ;
VAL_ 959 KL_StartStopp_Info 3 "Systemfehler" 2 "Motoranlauf zwingend notwendig (Startanforderung)" 1 "Motoranlauf nicht zwingend notwendig (Stoppverbot, keine Startanforderung, evtl. Komforteinbussen)" 0 "Motorlauf langfristig nicht notwendig (Stoppfreigabe)" ;
VAL_ 959 KL_KD_Fehler 1 "mind. ein KD-Fehler vorhanden" 0 "kein KD-Fehler" ;
VAL_ 959 KL_Last_Kompr 255 "Fehler" ;
